VERSION ""

NS_ :

BS_:

BU_: RLPSU DPSU APSU PSB SHVU_RR vHS_B2 FCS EMCU SLB RCM CGW_CCU vDummy_HS_B ATS RLHV PFSU SGU ALBCU DSAU SWRC SHVU_FR RCS RRPSU BLTN_CAM SCM DLBCU OHCL RWPC RRHV WPC HOD ASAU

BO_ 799 SBCM_DRV_01_200ms: 8 CGW_CCU
 SG_ SBCM_DRV_Crc1Val : 0|8@1+ (1,0) [0|0] ""  Vector__XXX
 SG_ DRV_CrashUnlockCmd : 10|1@1+ (1,0) [0|0] ""  BLTN_CAM
 SG_ C_ApprOpenStatus : 11|1@1+ (1,0) [0|0] ""  Vector__XXX
 SG_ SBCM_DRV_AlvCnt1Val : 12|4@1+ (1,0) [0|0] ""  Vector__XXX
 SG_ DoorLock_DrvKeyLkSwSta_SBCM : 16|2@1+ (1,0) [0|0] ""  Vector__XXX
 SG_ DoorLock_DrvKeyUnLkSwSta_SBCM : 18|2@1+ (1,0) [0|0] ""  Vector__XXX
 SG_ Warn_DrvDrSwSta_SBCM : 20|2@1+ (1,0) [0|0] ""  WPC,RWPC,DPSU,ATS,BLTN_CAM
 SG_ DoorLock_DrvDrUnLkSta_SBCM : 22|2@1+ (1,0) [0|0] ""  ATS
 SG_ DRV_SEAWarn_LH : 24|2@1+ (1,0) [0|0] ""  Vector__XXX
 SG_ DRV_SEAWarn_RH : 26|2@1+ (1,0) [0|0] ""  Vector__XXX
 SG_ DRV_SEWWarn_LH : 28|2@1+ (1,0) [0|0] ""  Vector__XXX
 SG_ DRV_SEWWarn_RH : 30|2@1+ (1,0) [0|0] ""  Vector__XXX
 SG_ DRV_MRActivationAlarm : 32|2@1+ (1,0) [0|0] ""  Vector__XXX
 SG_ DRV_ReleaseWarn : 34|2@1+ (1,0) [0|0] ""  Vector__XXX
 SG_ Latch_TypeOption_DRV : 36|2@1+ (1,0) [0|0] ""  Vector__XXX
 SG_ DRV_SWFailAlarm : 38|2@1+ (1,0) [0|0] ""  Vector__XXX
 SG_ USM_PwrDRApprOpnSetSta : 40|2@1+ (1,0) [0|0] ""  Vector__XXX
 SG_ USM_PwrDRApprOpnSetOpt : 42|2@1+ (1,0) [0|0] ""  Vector__XXX
 SG_ USM_PwrDRCloseByRKELockSta : 44|2@1+ (1,0) [0|0] ""  Vector__XXX
 SG_ USM_PwrDRCloseByRKELockOpt : 46|2@1+ (1,0) [0|0] ""  Vector__XXX
 SG_ USM_PwrDRCloseByBrakeSta : 48|2@1+ (1,0) [0|0] ""  Vector__XXX
 SG_ USM_PwrDRCloseByBrakeOpt : 50|2@1+ (1,0) [0|0] ""  Vector__XXX
 SG_ USM_PwrDRBuzzerSta : 52|2@1+ (1,0) [0|0] ""  Vector__XXX
 SG_ USM_PwrDRBuzzerOpt : 54|2@1+ (1,0) [0|0] ""  Vector__XXX
 SG_ PDS_TypeOption_DRV : 56|2@1+ (1,0) [0|0] ""  Vector__XXX
 SG_ C_DrvDoorApproachOpen : 58|2@1+ (1,0) [0|0] ""  Vector__XXX
 SG_ C_DrvDoorApproachClose : 60|2@1+ (1,0) [0|0] ""  Vector__XXX
 SG_ DoorLock_PDSLkSwSta_DRV : 62|2@1+ (1,0) [0|0] ""  Vector__XXX
 SG_ DRVDoorPushAlarm : 8|2@1+ (1,0) [0|0] ""  Vector__XXX

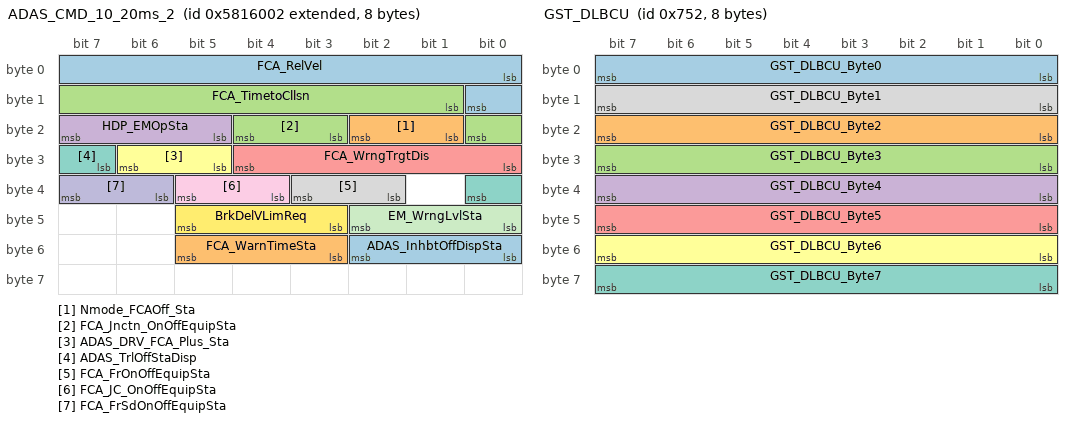
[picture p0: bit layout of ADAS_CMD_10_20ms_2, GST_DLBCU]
BO_ 2239848450 ADAS_CMD_10_20ms_2: 8 CGW_CCU
 SG_ FCA_RelVel : 0|9@1+ (0.1,-25.5) [0|0] "m/s"  Vector__XXX
 SG_ Nmode_FCAOff_Sta : 17|2@1+ (1,0) [0|0] ""  Vector__XXX
 SG_ FCA_Jnctn_OnOffEquipSta : 19|2@1+ (1,0) [0|0] ""  PSB
 SG_ HDP_EMOpSta : 21|3@1+ (1,0) [0|0] ""  Vector__XXX
 SG_ FCA_WrngTrgtDis : 24|5@1+ (1,0) [0|0] ""  APSU
 SG_ ADAS_DRV_FCA_Plus_Sta : 29|2@1+ (1,0) [0|0] ""  Vector__XXX
 SG_ ADAS_TrlOffStaDisp : 31|2@1+ (1,0) [0|0] ""  Vector__XXX
 SG_ FCA_FrOnOffEquipSta : 34|2@1+ (1,0) [0|0] ""  Vector__XXX
 SG_ FCA_JC_OnOffEquipSta : 36|2@1+ (1,0) [0|0] ""  Vector__XXX
 SG_ FCA_FrSdOnOffEquipSta : 38|2@1+ (1,0) [0|0] ""  Vector__XXX
 SG_ EM_WrngLvlSta : 40|3@1+ (1,0) [0|0] ""  Vector__XXX
 SG_ BrkDelVLimReq : 43|3@1+ (1,0) [0|0] ""  Vector__XXX
 SG_ ADAS_InhbtOffDispSta : 48|3@1+ (1,0) [0|0] ""  Vector__XXX
 SG_ FCA_WarnTimeSta : 51|3@1+ (1,0) [0|0] ""  Vector__XXX
 SG_ FCA_TimetoCllsn : 9|8@1+ (10,0) [0|0] "ms"  Vector__XXX

BO_ 1874 GST_DLBCU: 8 CGW_CCU
 SG_ GST_DLBCU_Byte0 : 0|8@1+ (1,0) [0|0] ""  DLBCU
 SG_ GST_DLBCU_Byte2 : 16|8@1+ (1,0) [0|0] ""  DLBCU
 SG_ GST_DLBCU_Byte3 : 24|8@1+ (1,0) [0|0] ""  DLBCU
 SG_ GST_DLBCU_Byte4 : 32|8@1+ (1,0) [0|0] ""  DLBCU
 SG_ GST_DLBCU_Byte5 : 40|8@1+ (1,0) [0|0] ""  DLBCU
 SG_ GST_DLBCU_Byte6 : 48|8@1+ (1,0) [0|0] ""  DLBCU
 SG_ GST_DLBCU_Byte7 : 56|8@1+ (1,0) [0|0] ""  DLBCU
 SG_ GST_DLBCU_Byte1 : 8|8@1+ (1,0) [0|0] ""  DLBCU

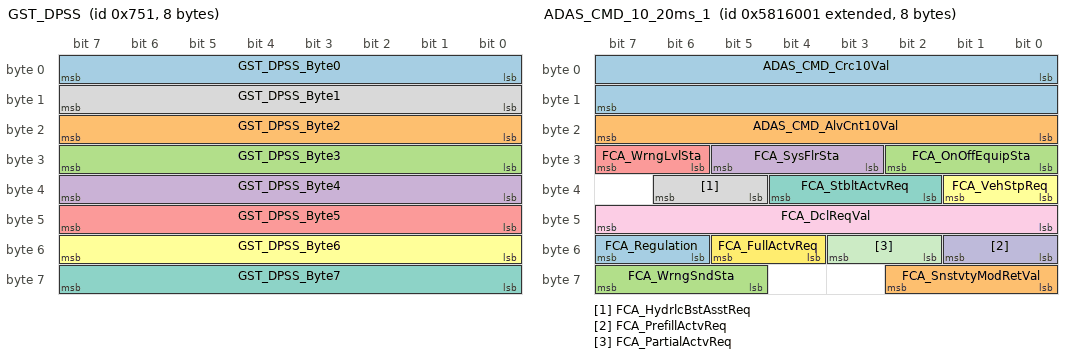
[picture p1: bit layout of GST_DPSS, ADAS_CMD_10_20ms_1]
BO_ 1873 GST_DPSS: 8 CGW_CCU
 SG_ GST_DPSS_Byte0 : 0|8@1+ (1,0) [0|0] ""  DPSU
 SG_ GST_DPSS_Byte2 : 16|8@1+ (1,0) [0|0] ""  DPSU
 SG_ GST_DPSS_Byte3 : 24|8@1+ (1,0) [0|0] ""  DPSU
 SG_ GST_DPSS_Byte4 : 32|8@1+ (1,0) [0|0] ""  DPSU
 SG_ GST_DPSS_Byte5 : 40|8@1+ (1,0) [0|0] ""  DPSU
 SG_ GST_DPSS_Byte6 : 48|8@1+ (1,0) [0|0] ""  DPSU
 SG_ GST_DPSS_Byte7 : 56|8@1+ (1,0) [0|0] ""  DPSU
 SG_ GST_DPSS_Byte1 : 8|8@1+ (1,0) [0|0] ""  DPSU

BO_ 2239848449 ADAS_CMD_10_20ms_1: 8 CGW_CCU
 SG_ ADAS_CMD_Crc10Val : 0|16@1+ (1,0) [0|0] ""  PSB
 SG_ ADAS_CMD_AlvCnt10Val : 16|8@1+ (1,0) [0|0] ""  PSB
 SG_ FCA_OnOffEquipSta : 24|3@1+ (1,0) [0|0] ""  PSB
 SG_ FCA_SysFlrSta : 27|3@1+ (1,0) [0|0] ""  PSB
 SG_ FCA_WrngLvlSta : 30|2@1+ (1,0) [0|0] ""  SWRC,APSU,RRPSU,RLPSU
 SG_ FCA_VehStpReq : 32|2@1+ (1,0) [0|0] ""  SWRC
 SG_ FCA_StbltActvReq : 34|3@1+ (1,0) [0|0] ""  PSB
 SG_ FCA_HydrlcBstAsstReq : 37|2@1+ (1,0) [0|0] ""  Vector__XXX
 SG_ FCA_DclReqVal : 40|8@1+ (0.01,0) [0|0] "g"  Vector__XXX
 SG_ FCA_PrefillActvReq : 48|2@1+ (1,0) [0|0] ""  Vector__XXX
 SG_ FCA_PartialActvReq : 50|2@1+ (1,0) [0|0] ""  Vector__XXX
 SG_ FCA_FullActvReq : 52|2@1+ (1,0) [0|0] ""  APSU,RRPSU,RLPSU
 SG_ FCA_Regulation : 54|2@1+ (1,0) [0|0] ""  Vector__XXX
 SG_ FCA_SnstvtyModRetVal : 56|3@1+ (1,0) [0|0] ""  Vector__XXX
 SG_ FCA_WrngSndSta : 61|3@1+ (1,0) [0|0] ""  Vector__XXX

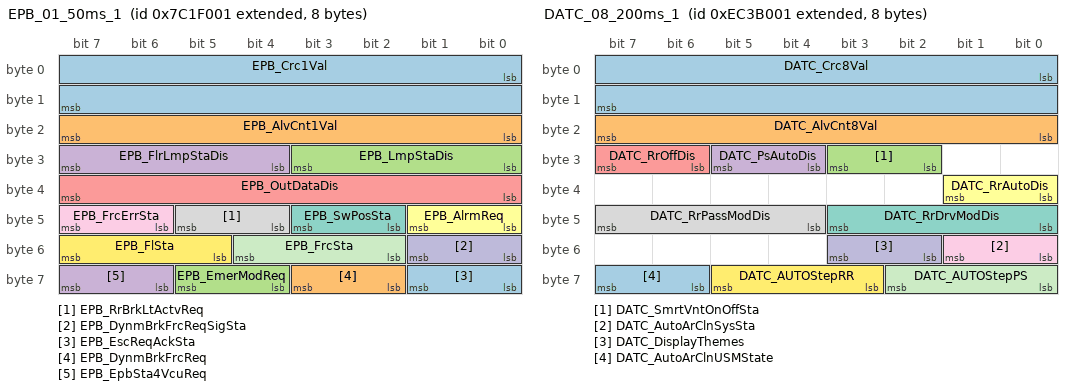
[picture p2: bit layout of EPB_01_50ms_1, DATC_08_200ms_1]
BO_ 2277634049 EPB_01_50ms_1: 8 CGW_CCU
 SG_ EPB_Crc1Val : 0|16@1+ (1,0) [0|0] ""  Vector__XXX
 SG_ EPB_AlvCnt1Val : 16|8@1+ (1,0) [0|0] ""  Vector__XXX
 SG_ EPB_LmpStaDis : 24|4@1+ (1,0) [0|0] ""  APSU,RLHV,RRHV,DPSU,PFSU,RRPSU,RLPSU
 SG_ EPB_FlrLmpStaDis : 28|4@1+ (1,0) [0|0] ""  Vector__XXX
 SG_ EPB_OutDataDis : 32|8@1+ (1,0) [0|0] ""  Vector__XXX
 SG_ EPB_AlrmReq : 40|2@1+ (1,0) [0|0] ""  Vector__XXX
 SG_ EPB_SwPosSta : 42|2@1+ (1,0) [0|0] ""  Vector__XXX
 SG_ EPB_RrBrkLtActvReq : 44|2@1+ (1,0) [0|0] ""  Vector__XXX
 SG_ EPB_FrcErrSta : 46|2@1+ (1,0) [0|0] ""  Vector__XXX
 SG_ EPB_DynmBrkFrcReqSigSta : 48|2@1+ (1,0) [0|0] ""  Vector__XXX
 SG_ EPB_FrcSta : 50|3@1+ (1,0) [0|0] ""  Vector__XXX
 SG_ EPB_FlSta : 53|3@1+ (1,0) [0|0] ""  Vector__XXX
 SG_ EPB_EscReqAckSta : 56|2@1+ (1,0) [0|0] ""  Vector__XXX
 SG_ EPB_DynmBrkFrcReq : 58|2@1+ (1,0) [0|0] ""  Vector__XXX
 SG_ EPB_EmerModReq : 60|2@1+ (1,0) [0|0] ""  Vector__XXX
 SG_ EPB_EpbSta4VcuReq : 62|2@1+ (1,0) [0|0] ""  Vector__XXX

BO_ 2277634050 EPB_01_50ms_2: 8 CGW_CCU
 SG_ EPB_ActlFrcVal : 0|12@1+ (1,-1000) [0|0] ""  Vector__XXX
 SG_ EPB_DynmBrkFrcDclReq : 16|8@1+ (0.01,0) [0|0] "g"  Vector__XXX

BO_ 2395189249 DATC_08_200ms_1: 8 CGW_CCU
 SG_ DATC_Crc8Val : 0|16@1+ (1,0) [0|0] ""  Vector__XXX
 SG_ DATC_AlvCnt8Val : 16|8@1+ (1,0) [0|0] ""  Vector__XXX
 SG_ DATC_SmrtVntOnOffSta : 26|2@1+ (1,0) [0|0] ""  Vector__XXX
 SG_ DATC_PsAutoDis : 28|2@1+ (1,0) [0|0] ""  ATS
 SG_ DATC_RrOffDis : 30|2@1+ (1,0) [0|0] ""  Vector__XXX
 SG_ DATC_RrAutoDis : 32|2@1+ (1,0) [0|0] ""  ATS
 SG_ DATC_RrDrvModDis : 40|4@1+ (1,0) [0|0] ""  ATS
 SG_ DATC_RrPassModDis : 44|4@1+ (1,0) [0|0] ""  ATS
 SG_ DATC_AutoArClnSysSta : 48|2@1+ (1,0) [0|0] ""  Vector__XXX
 SG_ DATC_DisplayThemes : 50|2@1+ (1,0) [0|0] ""  Vector__XXX
 SG_ DATC_AUTOStepPS : 56|3@1+ (1,0) [0|0] ""  ATS
 SG_ DATC_AUTOStepRR : 59|3@1+ (1,0) [0|0] ""  ATS
 SG_ DATC_AutoArClnUSMState : 62|2@1+ (1,0) [0|0] ""  Vector__XXX

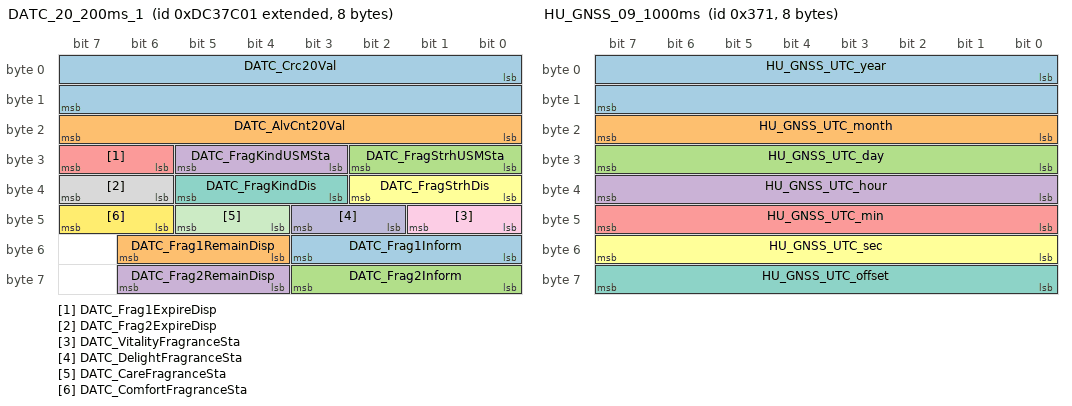
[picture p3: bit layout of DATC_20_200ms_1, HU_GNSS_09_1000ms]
BO_ 2378398721 DATC_20_200ms_1: 8 CGW_CCU
 SG_ DATC_Crc20Val : 0|16@1+ (1,0) [0|0] ""  Vector__XXX
 SG_ DATC_AlvCnt20Val : 16|8@1+ (1,0) [0|0] ""  Vector__XXX
 SG_ DATC_FragStrhUSMSta : 24|3@1+ (1,0) [0|0] ""  ATS
 SG_ DATC_FragKindUSMSta : 27|3@1+ (1,0) [0|0] ""  ATS
 SG_ DATC_Frag1ExpireDisp : 30|2@1+ (1,0) [0|0] ""  ATS
 SG_ DATC_FragStrhDis : 32|3@1+ (1,0) [0|0] ""  ATS
 SG_ DATC_FragKindDis : 35|3@1+ (1,0) [0|0] ""  ATS
 SG_ DATC_Frag2ExpireDisp : 38|2@1+ (1,0) [0|0] ""  ATS
 SG_ DATC_VitalityFragranceSta : 40|2@1+ (1,0) [0|0] ""  Vector__XXX
 SG_ DATC_DelightFragranceSta : 42|2@1+ (1,0) [0|0] ""  Vector__XXX
 SG_ DATC_CareFragranceSta : 44|2@1+ (1,0) [0|0] ""  Vector__XXX
 SG_ DATC_ComfortFragranceSta : 46|2@1+ (1,0) [0|0] ""  Vector__XXX
 SG_ DATC_Frag1Inform : 48|4@1+ (1,0) [0|0] ""  ATS
 SG_ DATC_Frag1RemainDisp : 52|3@1+ (1,0) [0|0] ""  ATS
 SG_ DATC_Frag2Inform : 56|4@1+ (1,0) [0|0] ""  ATS
 SG_ DATC_Frag2RemainDisp : 60|3@1+ (1,0) [0|0] ""  ATS

BO_ 881 HU_GNSS_09_1000ms: 8 CGW_CCU
 SG_ HU_GNSS_UTC_year : 0|16@1+ (1,0) [0|0] ""  BLTN_CAM
 SG_ HU_GNSS_UTC_month : 16|8@1+ (1,0) [0|0] ""  BLTN_CAM
 SG_ HU_GNSS_UTC_day : 24|8@1+ (1,0) [0|0] ""  BLTN_CAM
 SG_ HU_GNSS_UTC_hour : 32|8@1+ (1,0) [0|0] ""  BLTN_CAM
 SG_ HU_GNSS_UTC_min : 40|8@1+ (1,0) [0|0] ""  BLTN_CAM
 SG_ HU_GNSS_UTC_sec : 48|8@1+ (1,0) [0|0] ""  BLTN_CAM
 SG_ HU_GNSS_UTC_offset : 56|8@1+ (1,0) [0|0] "Sec"  BLTN_CAM

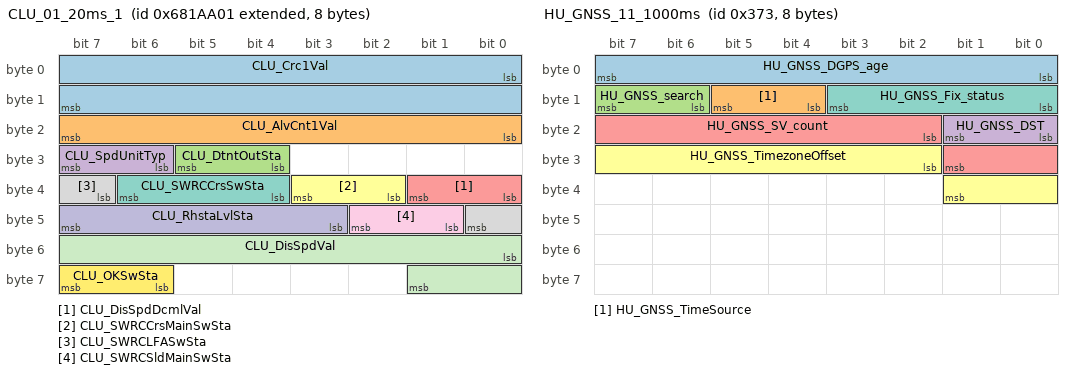
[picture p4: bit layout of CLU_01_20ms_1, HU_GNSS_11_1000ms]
BO_ 2256644609 CLU_01_20ms_1: 8 CGW_CCU
 SG_ CLU_Crc1Val : 0|16@1+ (1,0) [0|0] ""  SHVU_RR,DPSU,ATS
 SG_ CLU_AlvCnt1Val : 16|8@1+ (1,0) [0|0] ""  SHVU_RR,DPSU,ATS,EMCU
 SG_ CLU_DtntOutSta : 28|2@1+ (1,0) [0|0] ""  FCS,WPC,RWPC,SWRC,APSU,RLHV,RRHV,SHVU_FR,SHVU_RR,DPSU,RCS,RRPSU,RLPSU,ATS,DSAU,ASAU,OHCL
 SG_ CLU_SpdUnitTyp : 30|2@1+ (1,0) [0|0] ""  DPSU,BLTN_CAM,EMCU
 SG_ CLU_DisSpdDcmlVal : 32|2@1+ (0.125,0) [0|0] ""  Vector__XXX
 SG_ CLU_SWRCCrsMainSwSta : 34|2@1+ (1,0) [0|0] ""  Vector__XXX
 SG_ CLU_SWRCCrsSwSta : 36|3@1+ (1,0) [0|0] ""  Vector__XXX
 SG_ CLU_SWRCLFASwSta : 39|2@1+ (1,0) [0|0] ""  Vector__XXX
 SG_ CLU_SWRCSldMainSwSta : 41|2@1+ (1,0) [0|0] ""  Vector__XXX
 SG_ CLU_RhstaLvlSta : 43|5@1+ (1,0) [0|0] ""  FCS,WPC,RWPC,SWRC,APSU,RLHV,RRHV,SHVU_FR,SHVU_RR,DPSU,RCS,RRPSU,RLPSU,ATS,DSAU,ASAU,OHCL
 SG_ CLU_DisSpdVal : 48|10@1+ (0.5,0) [0|0] "km/h or MPH"  APSU,DPSU,BLTN_CAM,EMCU
 SG_ CLU_OKSwSta : 62|2@1+ (1,0) [0|0] ""  Vector__XXX

BO_ 883 HU_GNSS_11_1000ms: 8 CGW_CCU
 SG_ HU_GNSS_DGPS_age : 0|8@1+ (1,0) [0|0] "Sec"  Vector__XXX
 SG_ HU_GNSS_TimeSource : 12|2@1+ (1,0) [0|0] ""  Vector__XXX
 SG_ HU_GNSS_search : 14|2@1+ (1,0) [0|0] ""  Vector__XXX
 SG_ HU_GNSS_DST : 16|2@1+ (1,0) [0|0] ""  BLTN_CAM
 SG_ HU_GNSS_SV_count : 18|8@1+ (1,0) [0|0] ""  Vector__XXX
 SG_ HU_GNSS_TimezoneOffset : 26|8@1- (15,0) [0|0] "minute"  BLTN_CAM
 SG_ HU_GNSS_Fix_status : 8|4@1+ (1,0) [0|0] ""  Vector__XXX

BO_ 2470761217 CLU_07_00ms_1: 8 CGW_CCU
 SG_ CLU_Crc7Val : 0|16@1+ (1,0) [0|0] ""  Vector__XXX
 SG_ CLU_AlvCnt7Val : 16|8@1+ (1,0) [0|0] ""  Vector__XXX
 SG_ USM_AutoDrLkSetReq : 24|3@1+ (1,0) [0|0] ""  Vector__XXX
 SG_ USM_AutoDrUnlckSetReq : 27|3@1+ (1,0) [0|0] ""  Vector__XXX
 SG_ USM_HLmpEscrtSetReq : 30|2@1+ (1,0) [0|0] ""  Vector__XXX
 SG_ USM_SmrtTrnkSetReq : 32|3@1+ (1,0) [0|0] ""  Vector__XXX
 SG_ USM_MdLmpSetReq : 35|3@1+ (1,0) [0|0] ""  Vector__XXX
 SG_ USM_HrnAnswerBckSetReq : 38|2@1+ (1,0) [0|0] ""  Vector__XXX
 SG_ USM_OneTouchTrplTrnSetReq : 40|3@1+ (1,0) [0|0] ""  Vector__XXX
 SG_ USM_PsmSetReq : 43|3@1+ (1,0) [0|0] ""  DPSU
 SG_ USM_PtgmSetReq : 46|2@1+ (1,0) [0|0] ""  Vector__XXX
 SG_ USM_ScmSetReq : 48|2@1+ (1,0) [0|0] ""  Vector__XXX
 SG_ USM_OSTempUnitSetReq : 50|2@1+ (1,0) [0|0] ""  Vector__XXX
 SG_ USM_TfrChgSetReq : 52|2@1+ (1,0) [0|0] ""  Vector__XXX
 SG_ USM_WALModSetreq : 54|2@1+ (1,0) [0|0] ""  Vector__XXX
 SG_ USM_EscOffSetReq : 56|3@1+ (1,0) [0|0] ""  Vector__XXX
 SG_ USM_PsmHgtSetReq : 59|3@1+ (1,0) [0|0] ""  Vector__XXX

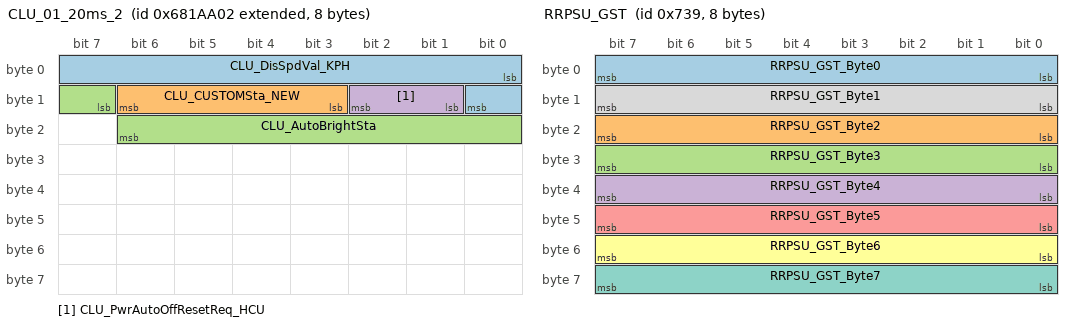
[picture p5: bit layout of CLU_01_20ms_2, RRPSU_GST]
BO_ 2256644610 CLU_01_20ms_2: 8 CGW_CCU
 SG_ CLU_DisSpdVal_KPH : 0|9@1+ (1,0) [0|0] "km/h"  WPC,RWPC,APSU,RLHV,RRHV,SHVU_FR,SHVU_RR,DPSU,DLBCU,PFSU,RRPSU,RLPSU,ATS,DSAU,ASAU,RCM,ALBCU
 SG_ CLU_CUSTOMSta_NEW : 11|4@1+ (1,0) [0|0] ""  Vector__XXX
 SG_ CLU_AutoBrightSta : 15|8@1+ (1,0) [0|0] ""  FCS,WPC,RWPC,SWRC,APSU,RLHV,RRHV,SHVU_FR,SHVU_RR,DPSU,RCS,ATS,DSAU,ASAU,OHCL,BLTN_CAM
 SG_ CLU_PwrAutoOffResetReq_HCU : 9|2@1+ (1,0) [0|0] ""  Vector__XXX

BO_ 1849 RRPSU_GST: 8 RRPSU
 SG_ RRPSU_GST_Byte0 : 0|8@1+ (1,0) [0|0] ""  CGW_CCU
 SG_ RRPSU_GST_Byte2 : 16|8@1+ (1,0) [0|0] ""  CGW_CCU
 SG_ RRPSU_GST_Byte3 : 24|8@1+ (1,0) [0|0] ""  CGW_CCU
 SG_ RRPSU_GST_Byte4 : 32|8@1+ (1,0) [0|0] ""  CGW_CCU
 SG_ RRPSU_GST_Byte5 : 40|8@1+ (1,0) [0|0] ""  CGW_CCU
 SG_ RRPSU_GST_Byte6 : 48|8@1+ (1,0) [0|0] ""  CGW_CCU
 SG_ RRPSU_GST_Byte7 : 56|8@1+ (1,0) [0|0] ""  CGW_CCU
 SG_ RRPSU_GST_Byte1 : 8|8@1+ (1,0) [0|0] ""  CGW_CCU

BO_ 884 HU_GNSS_12_1000ms: 8 CGW_CCU
 SG_ HU_MM_Latitude : 0|32@1- (1.0E-6,0) [0|0] "¢ª"  BLTN_CAM
 SG_ HU_MM_Longitude : 32|32@1- (1.0E-6,0) [0|0] "¢ª"  BLTN_CAM

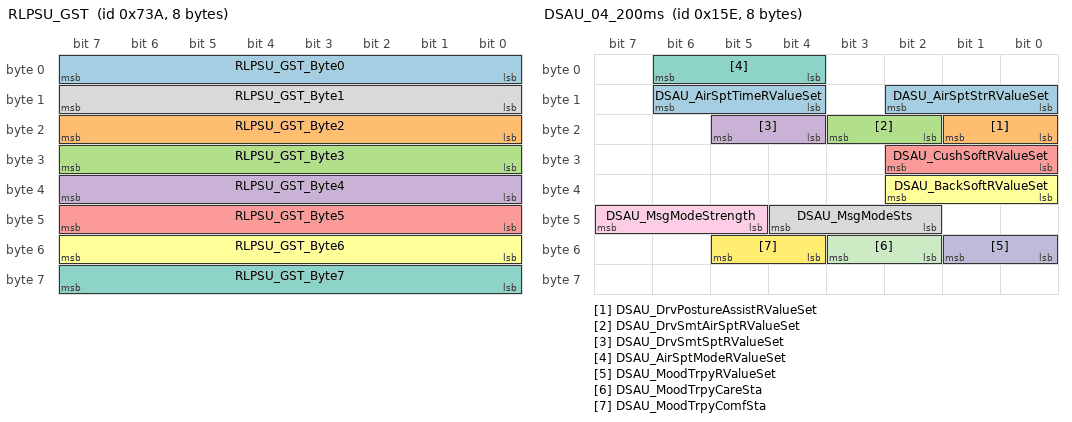
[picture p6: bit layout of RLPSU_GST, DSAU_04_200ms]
BO_ 1850 RLPSU_GST: 8 RLPSU
 SG_ RLPSU_GST_Byte0 : 0|8@1+ (1,0) [0|0] ""  CGW_CCU
 SG_ RLPSU_GST_Byte2 : 16|8@1+ (1,0) [0|0] ""  CGW_CCU
 SG_ RLPSU_GST_Byte3 : 24|8@1+ (1,0) [0|0] ""  CGW_CCU
 SG_ RLPSU_GST_Byte4 : 32|8@1+ (1,0) [0|0] ""  CGW_CCU
 SG_ RLPSU_GST_Byte5 : 40|8@1+ (1,0) [0|0] ""  CGW_CCU
 SG_ RLPSU_GST_Byte6 : 48|8@1+ (1,0) [0|0] ""  CGW_CCU
 SG_ RLPSU_GST_Byte7 : 56|8@1+ (1,0) [0|0] ""  CGW_CCU
 SG_ RLPSU_GST_Byte1 : 8|8@1+ (1,0) [0|0] ""  CGW_CCU

BO_ 2210462212 HCU_03_10ms_4: 8 CGW_CCU

BO_ 350 DSAU_04_200ms: 8 DSAU
 SG_ DSAU_AirSptTimeRValueSet : 12|3@1+ (1,0) [0|0] ""  CGW_CCU
 SG_ DSAU_DrvPostureAssistRValueSet : 16|2@1+ (1,0) [0|0] ""  Vector__XXX
 SG_ DSAU_DrvSmtAirSptRValueSet : 18|2@1+ (1,0) [0|0] ""  CGW_CCU
 SG_ DSAU_DrvSmtSptRValueSet : 20|2@1+ (1,0) [0|0] ""  Vector__XXX
 SG_ DSAU_CushSoftRValueSet : 24|3@1+ (1,0) [0|0] ""  CGW_CCU
 SG_ DSAU_BackSoftRValueSet : 32|3@1+ (1,0) [0|0] ""  CGW_CCU
 SG_ DSAU_AirSptModeRValueSet : 4|3@1+ (1,0) [0|0] ""  CGW_CCU
 SG_ DSAU_MsgModeSts : 42|3@1+ (1,0) [0|0] ""  CGW_CCU
 SG_ DSAU_MsgModeStrength : 45|3@1+ (1,0) [0|0] ""  CGW_CCU
 SG_ DSAU_MoodTrpyRValueSet : 48|2@1+ (1,0) [0|0] ""  CGW_CCU
 SG_ DSAU_MoodTrpyCareSta : 50|2@1+ (1,0) [0|0] ""  CGW_CCU
 SG_ DSAU_MoodTrpyComfSta : 52|2@1+ (1,0) [0|0] ""  CGW_CCU
 SG_ DASU_AirSptStrRValueSet : 8|3@1+ (1,0) [0|0] ""  CGW_CCU

BO_ 349 DSAU_03_200ms: 8 DSAU
 SG_ DSAU_CushInfDis : 0|2@1+ (1,0) [0|0] ""  CGW_CCU
 SG_ DSAU_CushDefDis : 2|2@1+ (1,0) [0|0] ""  CGW_CCU

BO_ 348 DSAU_02_200ms: 8 DSAU
 SG_ DSAU_BolsterInfDis : 0|2@1+ (1,0) [0|0] ""  CGW_CCU
 SG_ DSAU_BolsterDefDis : 2|2@1+ (1,0) [0|0] ""  CGW_CCU

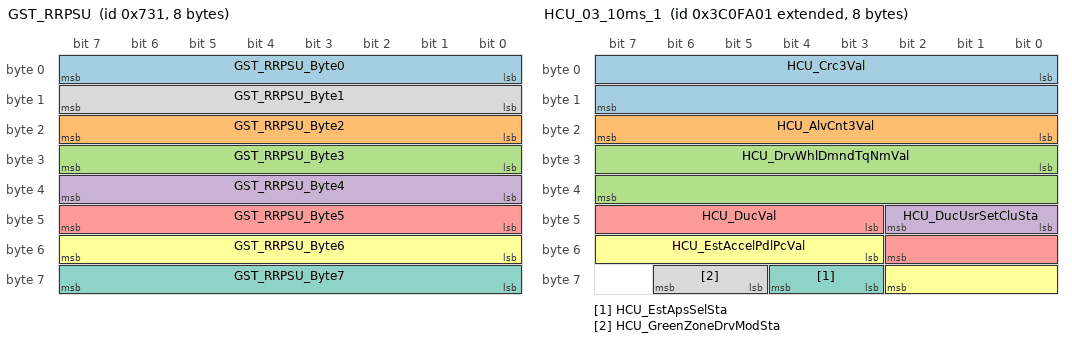
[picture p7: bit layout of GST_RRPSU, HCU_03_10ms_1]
BO_ 1841 GST_RRPSU: 8 CGW_CCU
 SG_ GST_RRPSU_Byte0 : 0|8@1+ (1,0) [0|0] ""  RRPSU
 SG_ GST_RRPSU_Byte2 : 16|8@1+ (1,0) [0|0] ""  RRPSU
 SG_ GST_RRPSU_Byte3 : 24|8@1+ (1,0) [0|0] ""  RRPSU
 SG_ GST_RRPSU_Byte4 : 32|8@1+ (1,0) [0|0] ""  RRPSU
 SG_ GST_RRPSU_Byte5 : 40|8@1+ (1,0) [0|0] ""  RRPSU
 SG_ GST_RRPSU_Byte6 : 48|8@1+ (1,0) [0|0] ""  RRPSU
 SG_ GST_RRPSU_Byte7 : 56|8@1+ (1,0) [0|0] ""  RRPSU
 SG_ GST_RRPSU_Byte1 : 8|8@1+ (1,0) [0|0] ""  RRPSU

BO_ 2210462209 HCU_03_10ms_1: 8 CGW_CCU
 SG_ HCU_Crc3Val : 0|16@1+ (1,0) [0|0] ""  Vector__XXX
 SG_ HCU_AlvCnt3Val : 16|8@1+ (1,0) [0|0] ""  Vector__XXX
 SG_ HCU_DrvWhlDmndTqNmVal : 24|16@1- (1,0) [0|0] "Nm"  Vector__XXX
 SG_ HCU_DucUsrSetCluSta : 40|3@1+ (1,0) [0|0] ""  Vector__XXX
 SG_ HCU_DucVal : 43|8@1+ (1,0) [0|0] "km"  Vector__XXX
 SG_ HCU_EstAccelPdlPcVal : 51|8@1+ (0.390625,0) [0|0] "%"  Vector__XXX
 SG_ HCU_EstApsSelSta : 59|2@1+ (1,0) [0|0] ""  Vector__XXX
 SG_ HCU_GreenZoneDrvModSta : 61|2@1+ (1,0) [0|0] ""  Vector__XXX

BO_ 346 DPSS_04_200ms: 8 DPSU
 SG_ DPSS_WalkInSwitchSts : 44|2@1+ (1,0) [0|0] ""  Vector__XXX

BO_ 2210462210 HCU_03_10ms_2: 8 CGW_CCU
 SG_ HCU_GreenZoneLmpDis : 0|2@1+ (1,0) [0|0] ""  Vector__XXX
 SG_ HCU_MILOnReq : 10|2@1+ (1,0) [0|0] ""  Vector__XXX
 SG_ HCU_PhevAutoModOnSta : 12|2@1+ (1,0) [0|0] "flag"  Vector__XXX
 SG_ HCU_SccDrvOvrdReq : 14|2@1+ (1,0) [0|0] ""  Vector__XXX
 SG_ HCU_SccEnblSta : 16|2@1+ (1,0) [0|0] ""  Vector__XXX
 SG_ HCU_SlwDnSta : 18|2@1+ (1,0) [0|0] ""  Vector__XXX
 SG_ HCU_HcuRdySta : 2|2@1+ (1,0) [0|0] ""  Vector__XXX
 SG_ HCU_SmrtEcoGdDis : 20|2@1+ (1,0) [0|0] ""  Vector__XXX
 SG_ HCU_SmrtEcoLvlDis : 22|7@1+ (1,0) [0|0] ""  Vector__XXX
 SG_ HCU_SmrtEcoRngDis : 29|7@1+ (1,0) [0|0] ""  Vector__XXX
 SG_ HCU_SpdLimDeviceActSta : 36|2@1+ (1,0) [0|0] ""  Vector__XXX
 SG_ HCU_SpdLimDeviceOperSta : 38|2@1+ (1,0) [0|0] ""  Vector__XXX
 SG_ HCU_HEVRdyDis : 4|2@1+ (1,0) [0|0] ""  Vector__XXX
 SG_ HCU_SpdLimDeviceVehSpdVal : 40|8@1+ (1,0) [0|0] "km/h"  Vector__XXX
 SG_ HCU_SrvModSta : 48|2@1+ (1,0) [0|0] ""  Vector__XXX
 SG_ HCU_StrtInhbt2Sta : 50|2@1+ (1,0) [0|0] ""  Vector__XXX
 SG_ HCU_StrtInhbtSta : 52|2@1+ (1,0) [0|0] ""  Vector__XXX
 SG_ HCU_SysShtOffReq : 54|2@1+ (1,0) [0|0] ""  Vector__XXX
 SG_ HCU_VehStrtEnblSta : 56|2@1+ (1,0) [0|0] ""  Vector__XXX
 SG_ HCU_BrkLmpOnReq : 58|2@1+ (1,0) [0|0] ""  Vector__XXX
 SG_ HCU_HevRdySta : 6|2@1+ (1,0) [0|0] ""  WPC,RWPC,SWRC,HOD,BLTN_CAM
 SG_ HCU_CcDrvAlrtDis : 60|2@1+ (1,0) [0|0] ""  Vector__XXX
 SG_ HCU_SldDrvAlrtDis : 62|2@1+ (1,0) [0|0] ""  Vector__XXX
 SG_ HCU_LimpOffSta : 8|2@1+ (1,0) [0|0] ""  Vector__XXX

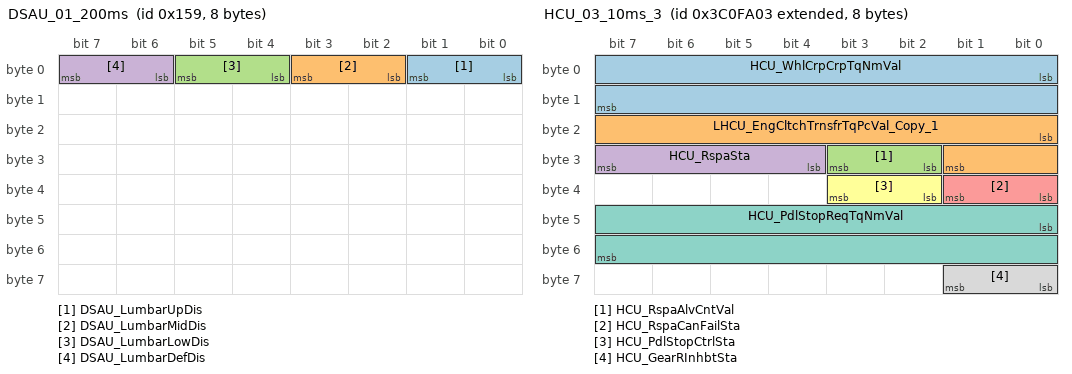
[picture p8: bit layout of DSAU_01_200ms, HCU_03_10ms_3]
BO_ 345 DSAU_01_200ms: 8 DSAU
 SG_ DSAU_LumbarUpDis : 0|2@1+ (1,0) [0|0] ""  CGW_CCU
 SG_ DSAU_LumbarMidDis : 2|2@1+ (1,0) [0|0] ""  CGW_CCU
 SG_ DSAU_LumbarLowDis : 4|2@1+ (1,0) [0|0] ""  CGW_CCU
 SG_ DSAU_LumbarDefDis : 6|2@1+ (1,0) [0|0] ""  CGW_CCU

BO_ 2210462211 HCU_03_10ms_3: 8 CGW_CCU
 SG_ HCU_WhlCrpCrpTqNmVal : 0|16@1- (1,0) [0|0] "Nm"  Vector__XXX
 SG_ LHCU_EngCltchTrnsfrTqPcVal_Copy_1 : 16|10@1- (0.1953125,0) [0|0] "%"  Vector__XXX
 SG_ HCU_RspaAlvCntVal : 26|2@1+ (1,0) [0|0] "Step"  Vector__XXX
 SG_ HCU_RspaSta : 28|4@1+ (1,0) [0|0] ""  Vector__XXX
 SG_ HCU_RspaCanFailSta : 32|2@1+ (1,0) [0|0] ""  Vector__XXX
 SG_ HCU_PdlStopCtrlSta : 34|2@1+ (1,0) [0|0] ""  Vector__XXX
 SG_ HCU_PdlStopReqTqNmVal : 40|16@1+ (1,0) [0|0] "Nm"  Vector__XXX
 SG_ HCU_GearRInhbtSta : 56|2@1+ (1,0) [0|0] ""  Vector__XXX

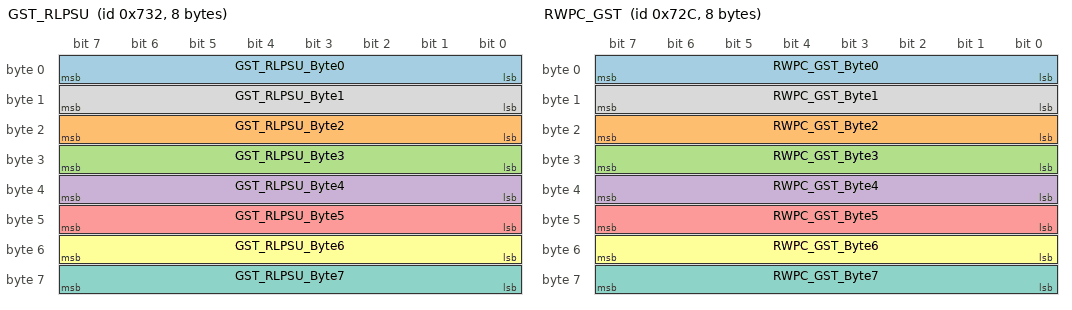
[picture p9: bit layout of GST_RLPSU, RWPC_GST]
BO_ 1842 GST_RLPSU: 8 CGW_CCU
 SG_ GST_RLPSU_Byte0 : 0|8@1+ (1,0) [0|0] ""  RLPSU
 SG_ GST_RLPSU_Byte2 : 16|8@1+ (1,0) [0|0] ""  RLPSU
 SG_ GST_RLPSU_Byte3 : 24|8@1+ (1,0) [0|0] ""  RLPSU
 SG_ GST_RLPSU_Byte4 : 32|8@1+ (1,0) [0|0] ""  RLPSU
 SG_ GST_RLPSU_Byte5 : 40|8@1+ (1,0) [0|0] ""  RLPSU
 SG_ GST_RLPSU_Byte6 : 48|8@1+ (1,0) [0|0] ""  RLPSU
 SG_ GST_RLPSU_Byte7 : 56|8@1+ (1,0) [0|0] ""  RLPSU
 SG_ GST_RLPSU_Byte1 : 8|8@1+ (1,0) [0|0] ""  RLPSU

BO_ 1836 RWPC_GST: 8 RWPC
 SG_ RWPC_GST_Byte0 : 0|8@1+ (1,0) [0|0] ""  CGW_CCU
 SG_ RWPC_GST_Byte2 : 16|8@1+ (1,0) [0|0] ""  CGW_CCU
 SG_ RWPC_GST_Byte3 : 24|8@1+ (1,0) [0|0] ""  CGW_CCU
 SG_ RWPC_GST_Byte4 : 32|8@1+ (1,0) [0|0] ""  CGW_CCU
 SG_ RWPC_GST_Byte5 : 40|8@1+ (1,0) [0|0] ""  CGW_CCU
 SG_ RWPC_GST_Byte6 : 48|8@1+ (1,0) [0|0] ""  CGW_CCU
 SG_ RWPC_GST_Byte7 : 56|8@1+ (1,0) [0|0] ""  CGW_CCU
 SG_ RWPC_GST_Byte1 : 8|8@1+ (1,0) [0|0] ""  CGW_CCU

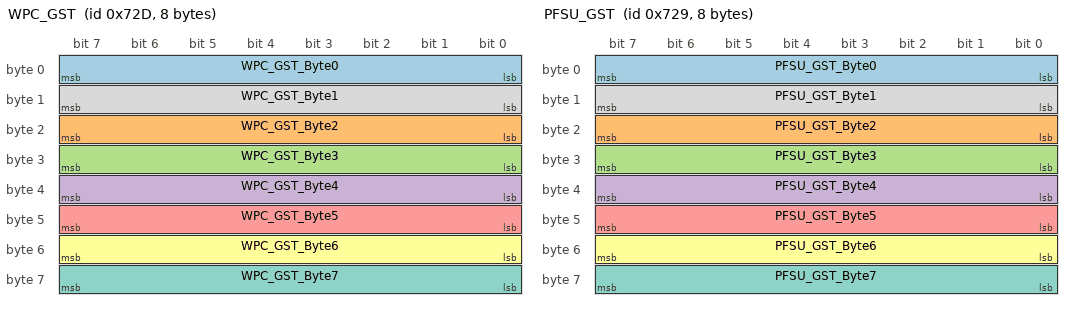
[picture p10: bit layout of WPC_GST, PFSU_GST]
BO_ 1837 WPC_GST: 8 WPC
 SG_ WPC_GST_Byte0 : 0|8@1+ (1,0) [0|0] ""  CGW_CCU
 SG_ WPC_GST_Byte2 : 16|8@1+ (1,0) [0|0] ""  CGW_CCU
 SG_ WPC_GST_Byte3 : 24|8@1+ (1,0) [0|0] ""  CGW_CCU
 SG_ WPC_GST_Byte4 : 32|8@1+ (1,0) [0|0] ""  CGW_CCU
 SG_ WPC_GST_Byte5 : 40|8@1+ (1,0) [0|0] ""  CGW_CCU
 SG_ WPC_GST_Byte6 : 48|8@1+ (1,0) [0|0] ""  CGW_CCU
 SG_ WPC_GST_Byte7 : 56|8@1+ (1,0) [0|0] ""  CGW_CCU
 SG_ WPC_GST_Byte1 : 8|8@1+ (1,0) [0|0] ""  CGW_CCU

BO_ 1833 PFSU_GST: 8 PFSU
 SG_ PFSU_GST_Byte0 : 0|8@1+ (1,0) [0|0] ""  CGW_CCU
 SG_ PFSU_GST_Byte2 : 16|8@1+ (1,0) [0|0] ""  CGW_CCU
 SG_ PFSU_GST_Byte3 : 24|8@1+ (1,0) [0|0] ""  CGW_CCU
 SG_ PFSU_GST_Byte4 : 32|8@1+ (1,0) [0|0] ""  CGW_CCU
 SG_ PFSU_GST_Byte5 : 40|8@1+ (1,0) [0|0] ""  CGW_CCU
 SG_ PFSU_GST_Byte6 : 48|8@1+ (1,0) [0|0] ""  CGW_CCU
 SG_ PFSU_GST_Byte7 : 56|8@1+ (1,0) [0|0] ""  CGW_CCU
 SG_ PFSU_GST_Byte1 : 8|8@1+ (1,0) [0|0] ""  CGW_CCU

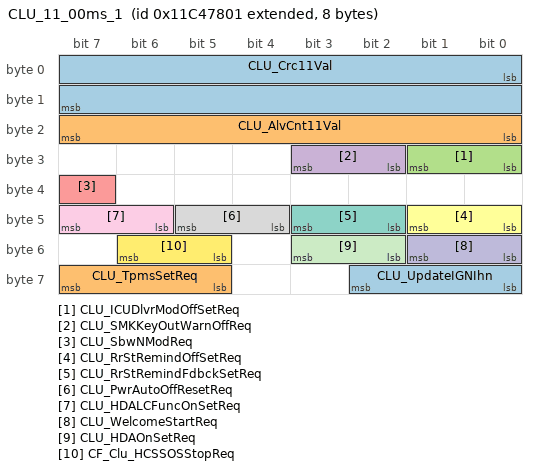
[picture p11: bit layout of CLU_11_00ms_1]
BO_ 2445572097 CLU_11_00ms_1: 8 CGW_CCU
 SG_ CLU_Crc11Val : 0|16@1+ (1,0) [0|0] ""  Vector__XXX
 SG_ CLU_AlvCnt11Val : 16|8@1+ (1,0) [0|0] ""  Vector__XXX
 SG_ CLU_ICUDlvrModOffSetReq : 24|2@1+ (1,0) [0|0] ""  Vector__XXX
 SG_ CLU_SMKKeyOutWarnOffReq : 26|2@1+ (1,0) [0|0] ""  Vector__XXX
 SG_ CLU_SbwNModReq : 39|1@1+ (1,0) [0|0] ""  Vector__XXX
 SG_ CLU_RrStRemindOffSetReq : 40|2@1+ (1,0) [0|0] ""  SWRC
 SG_ CLU_RrStRemindFdbckSetReq : 42|2@1+ (1,0) [0|0] ""  SWRC
 SG_ CLU_PwrAutoOffResetReq : 44|2@1+ (1,0) [0|0] ""  Vector__XXX
 SG_ CLU_HDALCFuncOnSetReq : 46|2@1+ (1,0) [0|0] ""  Vector__XXX
 SG_ CLU_WelcomeStartReq : 48|2@1+ (1,0) [0|0] ""  SWRC
 SG_ CLU_HDAOnSetReq : 50|2@1+ (1,0) [0|0] ""  Vector__XXX
 SG_ CF_Clu_HCSSOSStopReq : 53|2@1+ (1,0) [0|0] ""  Vector__XXX
 SG_ CLU_UpdateIGNIhn : 56|3@1+ (1,0) [0|0] ""  Vector__XXX
 SG_ CLU_TpmsSetReq : 61|3@1+ (1,0) [0|0] ""  Vector__XXX

CM_ BO_ 2239848449 "[P] Periodic";
CM_ SG_ 2239848449 ADAS_CMD_Crc10Val "ADAS_CMD_CyclicRedundancyCheck10Value ##2G##FCA - FCA11 - CR_FCA_ChkSum";
CM_ SG_ 2239848449 ADAS_CMD_AlvCnt10Val "ADAS_CMD_AliveCounter10Value ##2G##FCA - FCA11 - CR_FCA_Alive";
CM_ SG_ 2239848449 FCA_OnOffEquipSta "FCA_OnOffEquipmentStatus ##2G##FCA - FCA12 - FCA_USM";
CM_ SG_ 2239848449 FCA_SysFlrSta "FCA_SystemFailureStatus ##2G##FCA - FCA11 - FCA_Failinfo";
CM_ SG_ 2239848449 FCA_WrngLvlSta "FCA_WarningLevelStatus ##2G##FCA - FCA11 - CF_VSM_Warn";
CM_ SG_ 2239848449 FCA_VehStpReq "FCA_VehicleStopRequest ##2G##FCA - FCA11 - FCA_StopReq";
CM_ SG_ 2239848449 FCA_StbltActvReq "FCA_SeatBeltActivateRequest ##2G##FCA - FCA11 - CF_VSM_BeltCmd";
CM_ SG_ 2239848449 FCA_HydrlcBstAsstReq "FCA_HydraulicBoostAssistRequest ##2G##FCA - FCA11 - CF_VSM_HBACmd";
CM_ SG_ 2239848449 FCA_DclReqVal "FCA_DecelerationRequestValue ##2G##FCA - FCA11 - CR_VSM_DecCmd";
CM_ SG_ 2239848449 FCA_PrefillActvReq "FCA_PrefillActivateRequest ##2G##FCA - FCA11 - CF_VSM_Prefill";
CM_ SG_ 2239848449 FCA_PartialActvReq "FCA_PartialActivateRequest";
CM_ SG_ 2239848449 FCA_FullActvReq "FCA_FullActivateRequest";
CM_ SG_ 2239848449 FCA_Regulation "FCA_Regulation";
CM_ SG_ 2239848449 FCA_SnstvtyModRetVal "FCA_SensitivityModeReturnValue ##2G##FCA - FCA12 - FCA_DrvSetState";
CM_ SG_ 2239848449 FCA_WrngSndSta "FCA warning sound status";
CM_ BO_ 2239848450 "[P] Periodic";
CM_ SG_ 2239848450 FCA_RelVel "FCA_RelativeVelocity ##2G##FCA - FCA11_FS - FCA_RelativeVelocity";
CM_ SG_ 2239848450 Nmode_FCAOff_Sta "Nmode_FCAOff_Status ##2G##FCA - FCA12 - Nmode_FCAOff_Status";
CM_ SG_ 2239848450 FCA_Jnctn_OnOffEquipSta "FCA_Junction_OnOffEquipStatus";
CM_ SG_ 2239848450 HDP_EMOpSta "HDP EM Operating State";
CM_ SG_ 2239848450 FCA_WrngTrgtDis "FCA_WarningTargetDisplay";
CM_ SG_ 2239848450 ADAS_DRV_FCA_Plus_Sta "Àü¹æÄ«¸Þ¶ó, Àü¹æ·¹ÀÌ´õ ¹× ÀüÃø¹æ ·¹ÀÌ´õ/ÈÄÃø¹æ ·¹ÀÌÅÍ Ç»Àü Æ®·¢À» ÅëÇØ FCA-Car Å¸°Ù ¹× ÀÚÂ÷ ÁÂÃø/¿ìÃø ¿µ¿ª È¸ÇÇ ºÒ°¡´É ¿©ºÎ¸¦ ÆÇ´ÜÇÏ¿© FCA-Car/Ped/Cyc+ Flag¸¦ Ãâ·Â";
CM_ SG_ 2239848450 ADAS_TrlOffStaDisp "ADAS_Trailer Off State Display";
CM_ SG_ 2239848450 FCA_FrOnOffEquipSta "FCA Front On Off Equipment State";
CM_ SG_ 2239848450 FCA_JC_OnOffEquipSta "FCA_JC On Off Equipment State";
CM_ SG_ 2239848450 FCA_FrSdOnOffEquipSta "FCA Front Side On Off Equipment State";
CM_ SG_ 2239848450 EM_WrngLvlSta "EM_WarningLevelStatus";
CM_ SG_ 2239848450 BrkDelVLimReq "Brake Delta V Limit Request";
CM_ SG_ 2239848450 ADAS_InhbtOffDispSta "ADAS Inhibit Off Display State";
CM_ SG_ 2239848450 FCA_WarnTimeSta "FCA Warning Timing State";
CM_ SG_ 2239848450 FCA_TimetoCllsn "FCA_TimetoCollision ##2G##FCA - FCA11_FS - FCA_TimetoCollision";
CM_ BO_ 2256644609 "[P] Periodic";
CM_ SG_ 2256644609 CLU_Crc1Val "CLU_CyclicRedundancyCheck1Value";
CM_ SG_ 2256644609 CLU_AlvCnt1Val "CLU_AliveCounter1Value";
CM_ SG_ 2256644609 CLU_DtntOutSta "CLU_DetentOutStatus";
CM_ SG_ 2256644609 CLU_SpdUnitTyp "CLU_SpeedUnitType";
CM_ SG_ 2256644609 CLU_DisSpdDcmlVal "CLU_DisplaySpeedDecimalValue";
CM_ SG_ 2256644609 CLU_SWRCCrsMainSwSta "CLU_SWRCCrsMainSwSta";
CM_ SG_ 2256644609 CLU_SWRCCrsSwSta "CLU_SWRCCrsSwSta";
CM_ SG_ 2256644609 CLU_SWRCLFASwSta "SWRC_LFASwitchStatus";
CM_ SG_ 2256644609 CLU_SWRCSldMainSwSta "SWRC_SpeedLimiterMainSwitchStatus";
CM_ SG_ 2256644609 CLU_RhstaLvlSta "CLU_RheostatLevelStatus";
CM_ SG_ 2256644609 CLU_DisSpdVal "CLU_DisplaySpeedValue";
CM_ SG_ 2256644609 CLU_OKSwSta "OK Switch On/Off State";
CM_ BO_ 2256644610 "[P] Periodic";
CM_ SG_ 2256644610 CLU_DisSpdVal_KPH "CLU_DisplaySpeedValue_KPH";
CM_ SG_ 2256644610 CLU_AutoBrightSta "CLU_AutoBrightStatus";
CM_ SG_ 2256644610 CLU_PwrAutoOffResetReq_HCU "reset power auto off time";
CM_ BO_ 2470761217 "[EC] On Event and On Change";
CM_ SG_ 2470761217 CLU_Crc7Val "CLU_CyclicRedundancyCheck7Value";
CM_ SG_ 2470761217 CLU_AlvCnt7Val "CLU_AliveCounter7Value";
CM_ SG_ 2470761217 USM_AutoDrLkSetReq "USM_AutoDoorLockSetRequest";
CM_ SG_ 2470761217 USM_AutoDrUnlckSetReq "USM_AutoDoorUnlockSetRequest";
CM_ SG_ 2470761217 USM_HLmpEscrtSetReq "USM_HeadLampEscortSetRequest";
CM_ SG_ 2470761217 USM_SmrtTrnkSetReq "USM_SmartTrunkSetRequest";
CM_ SG_ 2470761217 USM_MdLmpSetReq "USM_MoodLampSetRequest";
CM_ SG_ 2470761217 USM_HrnAnswerBckSetReq "USM_HornAnswerBackSetRequest";
CM_ SG_ 2470761217 USM_OneTouchTrplTrnSetReq "USM_OneTouchTripleTurnSetRequest";
CM_ SG_ 2470761217 USM_PsmSetReq "USM_PsmSetRequest";
CM_ SG_ 2470761217 USM_PtgmSetReq "USM_PtgmSetRequest";
CM_ SG_ 2470761217 USM_ScmSetReq "USM_ScmSetRequest";
CM_ SG_ 2470761217 USM_OSTempUnitSetReq "USM_OutsideTemperatureUnitSetValue";
CM_ SG_ 2470761217 USM_TfrChgSetReq "USM_TrafficChangeSetRequest";
CM_ SG_ 2470761217 USM_WALModSetreq "USM_WalkAwayLockModeSetRequest(2nd General : CF_Clu_WALNValueset))";
CM_ SG_ 2470761217 USM_EscOffSetReq "USM_EscOffSetRequest (2nd general : CLU14/CF_Clu_EscOffNValueSet";
CM_ SG_ 2470761217 USM_PsmHgtSetReq "USM_PsmHeightSetRequest(2nd general : CLU20/CF_Clu_PSMHeightNValueSet )";
CM_ BO_ 2445572097 "[EC] On Event and On Change";
CM_ SG_ 2445572097 CLU_Crc11Val "CLU_CyclicRedundancyCheck11Value";
CM_ SG_ 2445572097 CLU_AlvCnt11Val "CLU_AliveCounter11Value";
CM_ SG_ 2445572097 CLU_ICUDlvrModOffSetReq "CLU_ICUDeliveryModeOffSetRequest";
CM_ SG_ 2445572097 CLU_SMKKeyOutWarnOffReq "CLU_SMKKeyOutWarningOffRequest";
CM_ SG_ 2445572097 CLU_SbwNModReq "CLU_SbwNModeRequest(2nd general: CLU22/CF_Clu_SbwNModeReq)";
CM_ SG_ 2445572097 CLU_RrStRemindOffSetReq "CLU_RrseatReminderOffSetRequest(2nd general:CLU20/CF_Clu_RrSeatRemindOff)";
CM_ SG_ 2445572097 CLU_RrStRemindFdbckSetReq "CLU_RrseatReminderFeedbackRequest (2nd general : CLU20/CF_Clu_RrSeatRemindFeedback)";
CM_ SG_ 2445572097 CLU_PwrAutoOffResetReq "reset power auto off time";
CM_ SG_ 2445572097 CLU_HDALCFuncOnSetReq "CLU_HDALCFuncOnSetReq";
CM_ SG_ 2445572097 CLU_WelcomeStartReq "Cluster welcome start signal";
CM_ SG_ 2445572097 CLU_HDAOnSetReq "This signal is used for a request to set on LFA/HDA";
CM_ SG_ 2445572097 CF_Clu_HCSSOSStopReq "Request to stop the SOS call";
CM_ SG_ 2445572097 CLU_TpmsSetReq "This signal is for setting the reference pressure of the iTPMS system";
CM_ BO_ 2395189249 "[PE] Periodic and On Event";
CM_ SG_ 2395189249 DATC_Crc8Val "DATC_CyclicRedundancyCheck8Value";
CM_ SG_ 2395189249 DATC_AlvCnt8Val "DATC_AliveCounter8Value";
CM_ SG_ 2395189249 DATC_SmrtVntOnOffSta "DATC_SmartVentilationOnOffStatus";
CM_ SG_ 2395189249 DATC_PsAutoDis "DATC_PassengerAutoDisplay";
CM_ SG_ 2395189249 DATC_RrOffDis "DATC_RearOffDisplay";
CM_ SG_ 2395189249 DATC_RrAutoDis "DATC_RearAutoDisplay";
CM_ SG_ 2395189249 DATC_RrDrvModDis "DATC_RearDriverModeDisplay";
CM_ SG_ 2395189249 DATC_RrPassModDis "DATC_RearPassengerModeDisplay";
CM_ SG_ 2395189249 DATC_AutoArClnSysSta "Auto Air Cleaning System State (China region only)";
CM_ SG_ 2395189249 DATC_DisplayThemes "DATC_DisplayThemesInformation";
CM_ SG_ 2395189249 DATC_AUTOStepPS "This signal indicates Passenger AUTO step status in case Multi Auto Blower type.";
CM_ SG_ 2395189249 DATC_AUTOStepRR "This signal indicates Rear AUTO step status in case Multi Auto Blower type.";
CM_ SG_ 2395189249 DATC_AutoArClnUSMState "Auto Air Cleaning USM State (China only apply)";
CM_ BO_ 2378398721 "[PE] Periodic and On Event";
CM_ SG_ 2378398721 DATC_Crc20Val "DATC_CyclicRedundancyCheck20Value";
CM_ SG_ 2378398721 DATC_AlvCnt20Val "DATC_AliveCounter20Value";
CM_ SG_ 2378398721 DATC_FragStrhUSMSta "Fragrance Strength State";
CM_ SG_ 2378398721 DATC_FragKindUSMSta "Fragrance Kind State";
CM_ SG_ 2378398721 DATC_Frag1ExpireDisp "DATC_Fragrance1ExpireDisplay";
CM_ SG_ 2378398721 DATC_FragStrhDis "Fragrance Strength Display";
CM_ SG_ 2378398721 DATC_FragKindDis "Fragrance Kind Display";
CM_ SG_ 2378398721 DATC_Frag2ExpireDisp "DATC_Fragrance2ExpireDisplay";
CM_ SG_ 2378398721 DATC_VitalityFragranceSta "DATC_VitalityFragranceState";
CM_ SG_ 2378398721 DATC_DelightFragranceSta "DATC_DelightFragranceState";
CM_ SG_ 2378398721 DATC_CareFragranceSta "DATC_CareFragranceState";
CM_ SG_ 2378398721 DATC_ComfortFragranceSta "DATC_ComfortFragranceState";
CM_ SG_ 2378398721 DATC_Frag1Inform "DATC_Fragrance1Information";
CM_ SG_ 2378398721 DATC_Frag1RemainDisp "DATC_Fragrance1RemainDisplay";
CM_ SG_ 2378398721 DATC_Frag2Inform "DATC_Fragrance2Information";
CM_ SG_ 2378398721 DATC_Frag2RemainDisp "DATC_Fragrance2RemainDisplay";
CM_ BO_ 346 "[PE] Periodic and On Event";
CM_ SG_ 346 DPSS_WalkInSwitchSts "DPSS_WalkInSwitchStatus";
CM_ BO_ 345 "[PE] Periodic and On Event";
CM_ SG_ 345 DSAU_LumbarUpDis "DSAU_LumbarUppperDisplay";
CM_ SG_ 345 DSAU_LumbarMidDis "DSAU_LumbarMidDisplay";
CM_ SG_ 345 DSAU_LumbarLowDis "DSAU_LumbarLowerDisplay";
CM_ SG_ 345 DSAU_LumbarDefDis "DSAU_LumbarDeflationDisplay";
CM_ BO_ 348 "[PE] Periodic and On Event";
CM_ SG_ 348 DSAU_BolsterInfDis "DSAU_BolsterInflationDisplay";
CM_ SG_ 348 DSAU_BolsterDefDis "DSAU_BolsterDeflationDisplay";
CM_ BO_ 349 "[PE] Periodic and On Event";
CM_ SG_ 349 DSAU_CushInfDis "DSAU_CushionInflationDisplay";
CM_ SG_ 349 DSAU_CushDefDis "DSAU_CushionDeflationDisplay";
CM_ BO_ 350 "[PE] Periodic and On Event";
CM_ SG_ 350 DSAU_AirSptTimeRValueSet "Air Support Time(Massage Time) USM R Value";
CM_ SG_ 350 DSAU_DrvPostureAssistRValueSet "Drive Seat Posture Assist Function USM R Value";
CM_ SG_ 350 DSAU_DrvSmtAirSptRValueSet "Seat Smart Air Support Function USM R Value";
CM_ SG_ 350 DSAU_DrvSmtSptRValueSet "Seat Smart Support Function USM R Value";
CM_ SG_ 350 DSAU_CushSoftRValueSet "Cushion Soft R Value";
CM_ SG_ 350 DSAU_BackSoftRValueSet "Back Soft USM R Value";
CM_ SG_ 350 DSAU_AirSptModeRValueSet "Air Support Mode(Massage Mode) USM R Value";
CM_ SG_ 350 DSAU_MsgModeSts "Air Support Mode Function Operating Display";
CM_ SG_ 350 DSAU_MsgModeStrength "Air Support intensity regulation(Massage Strenth)";
CM_ SG_ 350 DSAU_MoodTrpyRValueSet "Drive Seat Mood Therapy R Value";
CM_ SG_ 350 DSAU_MoodTrpyCareSta "Drive Seat Mood Therapy Care Mode R Value";
CM_ SG_ 350 DSAU_MoodTrpyComfSta "Drive Seat Mood Therapy Comfort Mode R Value";
CM_ SG_ 350 DASU_AirSptStrRValueSet "Air Support Strenth(Massage Strenth) USM R Value";
CM_ BO_ 2277634049 "[P] Periodic";
CM_ SG_ 2277634049 EPB_Crc1Val "EPB_CyclicRedundancyCheck1Value";
CM_ SG_ 2277634049 EPB_AlvCnt1Val "EPB_AliveCounter1Value";
CM_ SG_ 2277634049 EPB_LmpStaDis "EPB_LampStateDisplay ##2G##EPB - EPB11 - EPB_I_LAMP";
CM_ SG_ 2277634049 EPB_FlrLmpStaDis "EPB_FailureLampStateDisplay ##2G##EPB - EPB11 - EPB_F_LAMP";
CM_ SG_ 2277634049 EPB_OutDataDis "EPB_OutputDataDisplay ##2G##EPB - EPB11 - EPB_CLU";
CM_ SG_ 2277634049 EPB_AlrmReq "EPB_AlarmRequest ##2G##EPB - EPB11 - EPB_ALARM";
CM_ SG_ 2277634049 EPB_SwPosSta "EPB_SwitchPositionStatus ##2G##EPB - EPB11 - EPB_SWITCH";
CM_ SG_ 2277634049 EPB_RrBrkLtActvReq "EPB_RearBrakeLightActivationRequest ##2G##EPB - EPB11 - EPB_RBL";
CM_ SG_ 2277634049 EPB_FrcErrSta "EPB_ForceErrorStatus ##2G##EPB - EPB11 - EPB_FRC_ERR";
CM_ SG_ 2277634049 EPB_DynmBrkFrcReqSigSta "EPB_DynamicBrakingForceRequestSignalStatus ##2G##EPB - EPB11 - EPB_DBF_STAT";
CM_ SG_ 2277634049 EPB_FrcSta "EPB_ForceStatus ##2G##EPB - EPB11 - EPB_STATUS";
CM_ SG_ 2277634049 EPB_FlSta "EPB_FailStatus ##2G##EPB - EPB11 - EPB_FAIL";
CM_ SG_ 2277634049 EPB_EscReqAckSta "EPB_EscRequestAcknowledgeStatus ##2G##EPB - EPB11 - ESP_ACK";
CM_ SG_ 2277634049 EPB_DynmBrkFrcReq "EPB_DynamicBrakingForceRequest ##2G##EPB - EPB11 - EPB_DBF_REQ";
CM_ SG_ 2277634049 EPB_EmerModReq "EPB Emergency Mode Request";
CM_ SG_ 2277634049 EPB_EpbSta4VcuReq "EPB Status when VCU request of parking command or not parking command";
CM_ BO_ 2277634050 "[P] Periodic";
CM_ SG_ 2277634050 EPB_ActlFrcVal "EPB_ActualForceValue ##2G##EPB - EPB11 - EPB_FORCE";
CM_ SG_ 2277634050 EPB_DynmBrkFrcDclReq "EPB_DynamicBrakingForceDecelerationRequest ##2G##EPB - EPB11 - EPB_DBF_DECEL";
CM_ BO_ 1874 "[TP] Transport Protocol";
CM_ BO_ 1873 "[TP] Transport Protocol";
CM_ BO_ 1842 "[TP] Transport Protocol";
CM_ BO_ 1841 "[TP] Transport Protocol";
CM_ BO_ 2210462209 "[P] Periodic";
CM_ SG_ 2210462209 HCU_Crc3Val "HCU_CyclicRedundancyCheck3Value";
CM_ SG_ 2210462209 HCU_AlvCnt3Val "HCU_AliveCounter3Value";
CM_ SG_ 2210462209 HCU_DrvWhlDmndTqNmVal "HCU_DriverWheelDemandTorqueNmValue ##2G##HCU - HCU2 - CR_Hcu_WhlDemTq_Nm";
CM_ SG_ 2210462209 HCU_DucUsrSetCluSta "HCU_DucUserSettingClusterStatus ##2G##HCU - HCU4 - CF_Hcu_DUCPopUp";
CM_ SG_ 2210462209 HCU_DucVal "HCU_DucValue ##2G##HCU - HCU4 - CR_Hcu_DUC";
CM_ SG_ 2210462209 HCU_EstAccelPdlPcVal "HCU_EstimatedAcceleratorPedalPcValue ##2G##HCU - HCU4 - CR_Hcu_EstAccPed_PC";
CM_ SG_ 2210462209 HCU_EstApsSelSta "HCU_EstimatedApsSelectStatus ##2G##HCU - HCU4 - CF_HCU_EstApsSel";
CM_ SG_ 2210462209 HCU_GreenZoneDrvModSta "0x0:Default (USM ¹Ì Ç¥Ãâ (¸Þ´º»èÁ¦))
0x1:Off (USM Ç¥Ãâ Off »óÅÂ Ç¥½Ã) ##2G##HCU - HCU4 - CF_Hcu_GreenZoneDrv_Status";
CM_ BO_ 2210462210 "[P] Periodic";
CM_ SG_ 2210462210 HCU_GreenZoneLmpDis "Indicate Green Zone Area ##2G##HCU - HCU4 - CF_Hcu_GreenZoneLamp";
CM_ SG_ 2210462210 HCU_MILOnReq "HCU_MalfunctionIndicatorLampOnRequest ##2G##HCU - HCU1 - CF_Hcu_MILReq";
CM_ SG_ 2210462210 HCU_PhevAutoModOnSta "HCU_PhevAutoModeOnStatus ##2G##HCU - HCU4 - CF_Hcu_AutoCdCs";
CM_ SG_ 2210462210 HCU_SccDrvOvrdReq "HCU_SccDriverOverrideRequest ##2G##HCU - HCU2 - CF_Hcu_Ovrride";
CM_ SG_ 2210462210 HCU_SccEnblSta "HCU_SmartCruiseControlEnableStatus ##2G##HCU - HCU2 - CF_Hcu_SccEna";
CM_ SG_ 2210462210 HCU_SlwDnSta "HCU_SlowDownStatus ##2G##HCU - HCU1 - CF_Hcu_SlwDwnStat";
CM_ SG_ 2210462210 HCU_HcuRdySta "HCU_HybridControlUnitReadyStatus ##2G##HCU - HCU1 - CF_Hcu_Rdy";
CM_ SG_ 2210462210 HCU_SmrtEcoGdDis "HCU_SmartEcoGuideDisplay ##2G##HCU - HCU4 - CF_Hcu_SmartEcoDisp";
CM_ SG_ 2210462210 HCU_SmrtEcoLvlDis "HCU_SmartEcoLevelDisplay ##2G##HCU - HCU4 - CR_Hcu_SmartEcoLvl";
CM_ SG_ 2210462210 HCU_SmrtEcoRngDis "HCU_SmartEcoRangeDisplay ##2G##HCU - HCU4 - CR_Hcu_SmartEcoRng";
CM_ SG_ 2210462210 HCU_SpdLimDeviceActSta "HCU_SpeedLimiterDeviceActivationStatus ##2G##HCU - HCU4 - CF_Vcu_SldAct";
CM_ SG_ 2210462210 HCU_SpdLimDeviceOperSta "HCU_SpeedLimiterDeviceOperationStatus ##2G##HCU - HCU4 - CF_Hcu_SldOpr";
CM_ SG_ 2210462210 HCU_HEVRdyDis "HCU_HybridVehicleReadyDisplay ##2G##HCU - HCU1 - CF_Hcu_HevRdyClu";
CM_ SG_ 2210462210 HCU_SpdLimDeviceVehSpdVal "HCU_SpeedLimiterDeviceVehicleSpeedValue ##2G##HCU - HCU4 - CR_Vcu_SldVs";
CM_ SG_ 2210462210 HCU_SrvModSta "HCU_ServiceModeStatus ##2G##HCU - HCU2 - CF_Hcu_ServiceMod";
CM_ SG_ 2210462210 HCU_StrtInhbt2Sta "HCU_StartInhibit2Status ##2G##HCU - HCU3 - CF_Hcu_StartInh";
CM_ SG_ 2210462210 HCU_StrtInhbtSta "HCU_StartInhibitStatus ##2G##HCU - HCU1 - CF_Hcu_StInhStat";
CM_ SG_ 2210462210 HCU_SysShtOffReq "HCU_SystemShutOffRequest ##2G##HCU - HCU1 - CF_Hcu_SysShutOffReq";
CM_ SG_ 2210462210 HCU_VehStrtEnblSta "HCU_VehicleStartEnableStatus ##2G##HCU - HCU1 - CF_Hcu_Veh_ST";
CM_ SG_ 2210462210 HCU_BrkLmpOnReq "HCU_BrakeLampOnRequest###2G####HCU - HCU5 - CF_Hcu_BrkLpReq";
CM_ SG_ 2210462210 HCU_HevRdySta "HCU_HybridVehicleReadyStatus ##2G##HCU - HCU1 - CF_Hcu_HevRdy";
CM_ SG_ 2210462210 HCU_CcDrvAlrtDis "Driver display information of CC can not be engaged";
CM_ SG_ 2210462210 HCU_SldDrvAlrtDis "SLD must be disengaged by system or cannot be engaged";
CM_ SG_ 2210462210 HCU_LimpOffSta "HCU_LimpOffStatus ##2G##HCU - HCU22 - CF_Hcu_LimpOff";
CM_ BO_ 2210462211 "[P] Periodic";
CM_ SG_ 2210462211 HCU_WhlCrpCrpTqNmVal "HCU_WheelCreepTorqueNmValue ##2G##HCU - HCU2 - CR_Hcu_CrpTq_Nm";
CM_ SG_ 2210462211 LHCU_EngCltchTrnsfrTqPcVal_Copy_1 "##2G##HCU - HCU7 - CR_Hcu_EngCltTrnfTq_Pc";
CM_ SG_ 2210462211 HCU_RspaAlvCntVal "RSPA HCU Alive Counter ##2G##HCU - HCU4 - CF_Hcu_RspaAliveCnt";
CM_ SG_ 2210462211 HCU_RspaSta "HCU RSPA Cooperative control staus ##2G##HCU - HCU4 - CF_Hcu_RspaStat";
CM_ SG_ 2210462211 HCU_RspaCanFailSta "HCU RSPA CAN Fail Status ##2G##HCU - HCU4 - CR_Hcu_RspaCanFailFlag";
CM_ BO_ 2210462212 "[P] Periodic";
CM_ BO_ 881 "[P] Periodic";
CM_ SG_ 881 HU_GNSS_UTC_year "UTC year";
CM_ SG_ 881 HU_GNSS_UTC_hour "UTC_HOUR";
CM_ BO_ 883 "[P] Periodic";
CM_ SG_ 883 HU_GNSS_TimeSource "Time Source¶õ ÀÏÁ¾ÀÇ ModuleÀÌ Ãâ·ÂÇÒ ¼ö ÀÖ´Â ½Ã°£Á¤º¸ÀÇ À¯È¿¼º·¹º§À» Å¸³ª³»¸ç, User´Â RTC  or GPS(<1ms)  ÀÏ¶§¸¸ ½Ã°£ Á¤º¸ »ç¿ë °¡´É";
CM_ SG_ 883 HU_GNSS_DST "DST setting";
CM_ SG_ 883 HU_GNSS_TimezoneOffset "Timezone Offset";
CM_ SG_ 883 HU_GNSS_Fix_status "GNSS fix status";
CM_ BO_ 884 "[P] Periodic";
CM_ SG_ 884 HU_MM_Latitude "Map matching Latitude";
CM_ SG_ 884 HU_MM_Longitude "Mapmatching Longitude";
CM_ BO_ 1833 "[TP] Transport Protocol";
CM_ BO_ 1850 "[TP] Transport Protocol";
CM_ BO_ 1849 "[TP] Transport Protocol";
CM_ BO_ 1836 "[TP] Transport Protocol";
CM_ BO_ 799 "[PE] Periodic and On Event";
CM_ SG_ 799 SBCM_DRV_Crc1Val "SBCM_DRV_CyclicRedundancyCheck1Value";
CM_ SG_ 799 C_ApprOpenStatus "Stop fob searching signal";
CM_ SG_ 799 SBCM_DRV_AlvCnt1Val "SBCM_DRV_AliveCounter1Value";
CM_ SG_ 799 DoorLock_DrvKeyLkSwSta_SBCM "DoorLock_DriverKeyLockSwitchStatus ##2G## -  - C_DrvKeyLockSw";
CM_ SG_ 799 DoorLock_DrvKeyUnLkSwSta_SBCM "DoorLock_DriverKeyUnLockSwitchStatus ##2G## -  - C_DrvKeyUnlockSw";
CM_ SG_ 799 Warn_DrvDrSwSta_SBCM "DoorLock_DriverDoorSwitchStatus ##2G## -  - C_DrvDrSw,CF_Gway_DrvDrSw,Warn_DrvDrSwSta";
CM_ SG_ 799 DoorLock_DrvDrUnLkSta_SBCM "DoorLock_DriverDoorUnLockStatus ##2G## -  - C_DrvUnlockState,CF_Gway_DrvUnlockState";
CM_ SG_ 799 C_DrvDoorApproachOpen "Approach open";
CM_ BO_ 1837 "[TP] Transport Protocol";
BA_DEF_ BO_ "DiagState" ENUM "No","Yes" ;
BA_DEF_ BO_ "DiagResponse" ENUM "No","Yes" ;
BA_DEF_ BO_ "DiagRequest" ENUM "No","Yes" ;
BA_DEF_ BO_ "TpMessage" ENUM "No","Yes" ;
BA_DEF_ BO_ "UsrMsgIDSforwardDeviation" INT 0 100 ;
BA_DEF_ BO_ "UsrMsgIDSbackwardDeviation" INT 50 1000 ;
BA_DEF_ BO_ "GenMsgCycleTime" INT 0 2000 ;
BA_DEF_ BO_ "GenMsgStartDelayTime" INT 0 2000 ;
BA_DEF_ BO_ "GenMsgSendType" ENUM "Cyclic","NoMsgSendType" ;
BA_DEF_ BO_ "GenMsgCycleTimeFast" INT 0 500 ;
BA_DEF_ BO_ "GenMsgDelayTime" INT 0 20 ;
BA_DEF_ BO_ "GenMsgILSupport" ENUM "No","Yes" ;
BA_DEF_ BO_ "GenMsgNrOfRepetition" INT 0 3 ;
BA_DEF_ BO_ "NmMessage" ENUM "No","Yes" ;
BA_DEF_ BO_ "NWM-Botschaft" ENUM "No","Yes" ;
BA_DEF_ BO_ "TpTxIndex" INT 0 255 ;
BA_DEF_ BO_ "VFrameFormat" ENUM "StandardCAN","ExtendedCAN","reserved","reserved","reserved","reserved","reserved","reserved","reserved","reserved","reserved","reserved","reserved","reserved","StandardCAN_FD","ExtendedCAN_FD" ;
BA_DEF_ SG_ "UserSigValidity" ENUM "B+","ACC","IG","IG1","IG2","IG3","IG1 or IG2","IG1 or IG3","Undef" ;
BA_DEF_ SG_ "TimeoutValue" STRING ;
BA_DEF_ SG_ "UsrSigPurpose" ENUM "Undef","FN","DIAG","DIAG(Req)","DIAG(Res)","DIAG(Phy)","DEV","CCP(Req)","CCP(Res)","NM","TP" ;
BA_DEF_ SG_ "GenSigStartValue" INT 0 1215752192 ;
BA_DEF_ SG_ "NetworkRequest" ENUM "Yes","No" ;
BA_DEF_ SG_ "NetworkRequestHoldingTime" INT 0 65535 ;
BA_DEF_ SG_ "Description" STRING ;
BA_DEF_ SG_ "Version" STRING ;
BA_DEF_ SG_ "GenSigEnvVarType" ENUM "Int","Float","Undef" ;
BA_DEF_ SG_ "GenSigSendType" ENUM "Cyclic","OnWrite","OnWriteWithRepetition","OnChange","OnChangeWithRepetition","IfActive","IfActiveWithRepetition","NoSigSendType","OnChangeAndIfActive","OnChangeAndIfActiveWithRepetition" ;
BA_DEF_ SG_ "GwSigLatencyTime" INT 0 65536 ;
BA_DEF_ SG_ "GwSigMissingSourceType" ENUM "Undef","OldValue","DefaultValue","InitialValue" ;
BA_DEF_ SG_ "NWM-WakeupAllowed" ENUM "<n.a.>" ;
BA_DEF_ SG_ "RoutingFactor" INT 1 1215752192 ;
BA_DEF_REL_ BU_SG_REL_ "GenSigTimeoutTime" INT 0 7000 ;
BA_DEF_DEF_ "DiagState" "No" ;
BA_DEF_DEF_ "DiagResponse" "No" ;
BA_DEF_DEF_ "DiagRequest" "No" ;
BA_DEF_DEF_ "TpMessage" "No" ;
BA_DEF_DEF_ "UsrMsgIDSforwardDeviation" 10 ;
BA_DEF_DEF_ "UsrMsgIDSbackwardDeviation" 100 ;
BA_DEF_DEF_ "GenMsgCycleTime" 200 ;
BA_DEF_DEF_ "GenMsgStartDelayTime" 0 ;
BA_DEF_DEF_ "GenMsgSendType" "NoMsgSendType" ;
BA_DEF_DEF_ "GenMsgCycleTimeFast" 40 ;
BA_DEF_DEF_ "GenMsgDelayTime" 20 ;
BA_DEF_DEF_ "GenMsgILSupport" "Yes" ;
BA_DEF_DEF_ "GenMsgNrOfRepetition" 3 ;
BA_DEF_DEF_ "NmMessage" "No" ;
BA_DEF_DEF_ "NWM-Botschaft" "No" ;
BA_DEF_DEF_ "TpTxIndex" 0 ;
BA_DEF_DEF_ "VFrameFormat" "StandardCAN" ;
BA_DEF_DEF_ "UserSigValidity" "IG" ;
BA_DEF_DEF_ "TimeoutValue" "" ;
BA_DEF_DEF_ "UsrSigPurpose" "FN" ;
BA_DEF_DEF_ "GenSigStartValue" 0 ;
BA_DEF_DEF_ "NetworkRequest" "No" ;
BA_DEF_DEF_ "NetworkRequestHoldingTime" 0 ;
BA_DEF_DEF_ "Description" "" ;
BA_DEF_DEF_ "Version" "" ;
BA_DEF_DEF_ "GenSigEnvVarType" "Undef" ;
BA_DEF_DEF_ "GenSigSendType" "NoSigSendType" ;
BA_DEF_DEF_ "GwSigLatencyTime" 40 ;
BA_DEF_DEF_ "GwSigMissingSourceType" "Undef" ;
BA_DEF_DEF_ "NWM-WakeupAllowed" "<n.a.>" ;
BA_DEF_DEF_ "RoutingFactor" 1 ;
BA_DEF_DEF_REL_ "GenSigTimeoutTime" 500 ;
BA_ "GenMsgSendType" BO_ 2239848449 0;
BA_ "GenMsgCycleTime" BO_ 2239848449 100;
BA_ "GenMsgCycleTimeFast" BO_ 2239848449 0;
BA_ "GenMsgNrOfRepetition" BO_ 2239848449 0;
BA_ "VFrameFormat" BO_ 2239848449 1;
BA_ "Description" SG_ 2239848449 ADAS_CMD_Crc10Val "The data area for CRC calculation is based on the data length (DLC) of the message DB.

The CRC shall be calculated over the entire data block (excluding the CRC bytes) including the user data, alive counter and Data ID

 

- CRC Polynomial (0x1021) , Initial Value : 0xFFFF, XOR value : 0x0000, Data ID : Message ID + 0xF800 

- The initial value is for CRC calculation and the message should be sent with the calculated result value. 

- The mathematical expression to 16 bit CRC polynomial is given here. G(x) = x16 + x12 + x5 + 1";
BA_ "GenSigStartValue" SG_ 2239848449 ADAS_CMD_Crc10Val 65535;
BA_ "UserSigValidity" SG_ 2239848449 ADAS_CMD_Crc10Val 3;
BA_REL_ "GenSigTimeoutTime" BU_SG_REL_ PSB SG_ 2239848449 ADAS_CMD_Crc10Val 1500;
BA_ "RoutingFactor" SG_ 2239848449 ADAS_CMD_Crc10Val 5;
BA_ "Version" SG_ 2239848449 ADAS_CMD_Crc10Val "18.11.08";
BA_ "Description" SG_ 2239848449 ADAS_CMD_AlvCnt10Val "For the first transmission request for a data element the counter shall be initialized with 0 and shall be incremented by 1 for every subsequent send request. 

When the counter reaches the maximum value(0xFF), then it shall restart with 0 for the next send request";
BA_ "UserSigValidity" SG_ 2239848449 ADAS_CMD_AlvCnt10Val 3;
BA_REL_ "GenSigTimeoutTime" BU_SG_REL_ PSB SG_ 2239848449 ADAS_CMD_AlvCnt10Val 1500;
BA_ "RoutingFactor" SG_ 2239848449 ADAS_CMD_AlvCnt10Val 5;
BA_ "Version" SG_ 2239848449 ADAS_CMD_AlvCnt10Val "18.11.08";
BA_ "Description" SG_ 2239848449 FCA_OnOffEquipSta "This signal describes the FCA Function.

- ½Ã½ºÅÛ ÀåÂø ¿©ºÎ ¹× ½Ã½ºÅÛ on/off Á¤º¸";
BA_ "UserSigValidity" SG_ 2239848449 FCA_OnOffEquipSta 3;
BA_REL_ "GenSigTimeoutTime" BU_SG_REL_ PSB SG_ 2239848449 FCA_OnOffEquipSta 1500;
BA_ "RoutingFactor" SG_ 2239848449 FCA_OnOffEquipSta 5;
BA_ "Version" SG_ 2239848449 FCA_OnOffEquipSta "17.12.00";
BA_ "Description" SG_ 2239848449 FCA_SysFlrSta "This signal describes the failure information of FCA Function.

- ½Ã½ºÅÛ Á¤»ó ¶Ç´Â Ä«¸Þ¶ó/·¹ÀÌ´õ/½Ã½ºÅÛ °íÀå»óÅÂ Á¤º¸

0x1: Temporary unavailable by Front View Camera (blockage, high temperature, etc) for Sensor Fusion FCA 

0x2: Temporary unavailable by Front Radar (blockage, high temperature, etc) for either Radar only FCA or Sensor Fusion FCA when logic is in Front Radar

0x3: System failure (Failure by Front View Camera failure, Front Radar failure or relative cooperative control units, etc)

0x4: Temporary unavailable by Front View Camera (blockage, high temperature, etc) for Front View Camera only FCA

0x5: Temporary unavailable of steering function by Front View Camera (blockage, high temperature, etc) for sensor fusion when logic is in ADAS_DRV

0x6: Temporary unavailable by Front Radar (blockage, high temperature, etc) for Sensor Fusion FCA when logic is in Front View Camera";
BA_ "UserSigValidity" SG_ 2239848449 FCA_SysFlrSta 3;
BA_REL_ "GenSigTimeoutTime" BU_SG_REL_ PSB SG_ 2239848449 FCA_SysFlrSta 1500;
BA_ "RoutingFactor" SG_ 2239848449 FCA_SysFlrSta 5;
BA_ "Version" SG_ 2239848449 FCA_SysFlrSta "19.08.04";
BA_ "Description" SG_ 2239848449 FCA_WrngLvlSta "Request CLU to activate the corresponding warning device(s) according to the FCA warning level. (Braking / Steering act)

- FCA ±â´ÉÀÇ Á¦µ¿ ¹× Á¶Çâ Á¦¾î ÀÛµ¿ »óÅÂ Ç¥½Ã¿ë Á¤º¸½ÅÈ£";
BA_ "UserSigValidity" SG_ 2239848449 FCA_WrngLvlSta 3;
BA_REL_ "GenSigTimeoutTime" BU_SG_REL_ SWRC SG_ 2239848449 FCA_WrngLvlSta 1500;
BA_REL_ "GenSigTimeoutTime" BU_SG_REL_ APSU SG_ 2239848449 FCA_WrngLvlSta 1500;
BA_REL_ "GenSigTimeoutTime" BU_SG_REL_ RRPSU SG_ 2239848449 FCA_WrngLvlSta 1500;
BA_REL_ "GenSigTimeoutTime" BU_SG_REL_ RLPSU SG_ 2239848449 FCA_WrngLvlSta 1500;
BA_ "RoutingFactor" SG_ 2239848449 FCA_WrngLvlSta 5;
BA_ "Version" SG_ 2239848449 FCA_WrngLvlSta "19.06.02";
BA_ "Description" SG_ 2239848449 FCA_VehStpReq "A control request flag for vehicle stop. FCA expects vehicle to be controlled to a complete stop and hold its state by ESC.



- FCA Á¦µ¿»óÈ² Á¾·áÈÄ Á¤Â÷ »óÅÂ À¯Áö¸¦ À§ÇÑ ½ÅÈ£";
BA_ "UserSigValidity" SG_ 2239848449 FCA_VehStpReq 3;
BA_REL_ "GenSigTimeoutTime" BU_SG_REL_ SWRC SG_ 2239848449 FCA_VehStpReq 1500;
BA_ "RoutingFactor" SG_ 2239848449 FCA_VehStpReq 5;
BA_ "Version" SG_ 2239848449 FCA_VehStpReq "17.12.00";
BA_ "Description" SG_ 2239848449 FCA_StbltActvReq "Depending on the driving situation, FCA tells PSB to release(no alert), retract or pull the seat belt for occupant protection or warning.

- FCA Á¦µ¿»óÈ²½Ã ½ÃÆ®º§Æ® ÀÛµ¿À» À§ÇÑ Á¤º¸ ½ÅÈ£";
BA_ "UserSigValidity" SG_ 2239848449 FCA_StbltActvReq 3;
BA_REL_ "GenSigTimeoutTime" BU_SG_REL_ PSB SG_ 2239848449 FCA_StbltActvReq 1500;
BA_ "RoutingFactor" SG_ 2239848449 FCA_StbltActvReq 5;
BA_ "Version" SG_ 2239848449 FCA_StbltActvReq "17.12.00";
BA_ "Description" SG_ 2239848449 FCA_HydrlcBstAsstReq "Depending on the driving situation, FCA tells ESC to use lowered HBA (Hydraulic Boost Assist) threshold to sensitize the HBA entrance. 

The boost assist function is more easily activated than under normal driving condition.

- FCA Á¦µ¿»óÈ²½Ã HBA ÀÛµ¿À» À§ÇÑ Á¤º¸ ½ÅÈ£";
BA_ "UserSigValidity" SG_ 2239848449 FCA_HydrlcBstAsstReq 3;
BA_ "RoutingFactor" SG_ 2239848449 FCA_HydrlcBstAsstReq 5;
BA_ "Version" SG_ 2239848449 FCA_HydrlcBstAsstReq "17.12.00";
BA_ "Description" SG_ 2239848449 FCA_DclReqVal "Depending on the driving situation, FCA gives ESC the deceleration command. ESC maintains the deceleration.

- FCA Á¦µ¿À» À§ÇÑ ¿ä±¸ °¨¼Óµµ °ª";
BA_ "UserSigValidity" SG_ 2239848449 FCA_DclReqVal 3;
BA_ "RoutingFactor" SG_ 2239848449 FCA_DclReqVal 5;
BA_ "Version" SG_ 2239848449 FCA_DclReqVal "17.12.00";
BA_ "Description" SG_ 2239848449 FCA_PrefillActvReq "A control requeset flag for FCA first warning. (Audible Warning)

- FCA 1Â÷ Á¦µ¿»óÈ² ¿äÃ»½ÅÈ£";
BA_ "UserSigValidity" SG_ 2239848449 FCA_PrefillActvReq 3;
BA_ "RoutingFactor" SG_ 2239848449 FCA_PrefillActvReq 5;
BA_ "Version" SG_ 2239848449 FCA_PrefillActvReq "17.12.00";
BA_ "Description" SG_ 2239848449 FCA_PartialActvReq "A control requeset flag for FCA second warning. (Partial braking)

- FCA 2Â÷ Á¦µ¿»óÈ² ¿äÃ»½ÅÈ£";
BA_ "UserSigValidity" SG_ 2239848449 FCA_PartialActvReq 3;
BA_ "RoutingFactor" SG_ 2239848449 FCA_PartialActvReq 5;
BA_ "Version" SG_ 2239848449 FCA_PartialActvReq "17.11.00";
BA_ "Description" SG_ 2239848449 FCA_FullActvReq "A control requeset flag for FCA third warning. (Full braking)

- FCA 3Â÷ Á¦µ¿»óÈ² ¿äÃ»½ÅÈ£";
BA_ "UserSigValidity" SG_ 2239848449 FCA_FullActvReq 3;
BA_REL_ "GenSigTimeoutTime" BU_SG_REL_ APSU SG_ 2239848449 FCA_FullActvReq 1500;
BA_REL_ "GenSigTimeoutTime" BU_SG_REL_ RRPSU SG_ 2239848449 FCA_FullActvReq 1500;
BA_REL_ "GenSigTimeoutTime" BU_SG_REL_ RLPSU SG_ 2239848449 FCA_FullActvReq 1500;
BA_ "RoutingFactor" SG_ 2239848449 FCA_FullActvReq 5;
BA_ "Version" SG_ 2239848449 FCA_FullActvReq "17.11.00";
BA_ "Description" SG_ 2239848449 FCA_Regulation "This signal contains FCA regulation compliance information.";
BA_ "UserSigValidity" SG_ 2239848449 FCA_Regulation 3;
BA_ "RoutingFactor" SG_ 2239848449 FCA_Regulation 5;
BA_ "Version" SG_ 2239848449 FCA_Regulation "20.12.01";
BA_ "Description" SG_ 2239848449 FCA_SnstvtyModRetVal "This signal is FCA sensitive set mode switch(USM) info return value to cluster.

- FCA ¹Î°¨µµ ¼³Á¤ °ü·Ã USM ¼³Á¤ ½ºÀ§Ä¡ Á¤º¸ÀÇ ¸®ÅÏ °ª";
BA_ "UserSigValidity" SG_ 2239848449 FCA_SnstvtyModRetVal 3;
BA_ "RoutingFactor" SG_ 2239848449 FCA_SnstvtyModRetVal 5;
BA_ "Version" SG_ 2239848449 FCA_SnstvtyModRetVal "17.12.00";
BA_ "Description" SG_ 2239848449 FCA_WrngSndSta "FCA warning sound status";
BA_ "UserSigValidity" SG_ 2239848449 FCA_WrngSndSta 3;
BA_ "RoutingFactor" SG_ 2239848449 FCA_WrngSndSta 5;
BA_ "Version" SG_ 2239848449 FCA_WrngSndSta "18.12.04";
BA_ "GenMsgSendType" BO_ 2239848450 0;
BA_ "GenMsgCycleTime" BO_ 2239848450 100;
BA_ "GenMsgCycleTimeFast" BO_ 2239848450 0;
BA_ "GenMsgNrOfRepetition" BO_ 2239848450 0;
BA_ "VFrameFormat" BO_ 2239848450 1;
BA_ "Description" SG_ 2239848450 FCA_RelVel "This signal indicates the relative velocity between the host vehicle and a forward vehicle.







(PH) = ((HEX)-0FFH)*0.1 [m/s/digit]



       = (HEX)*0.1 [m/s/digit] - 25.5 [m/s]



CAN Message Physical range : Max. Relative velocity : 0x1FE(25.5m/s), Zero : 0x0FF(0m/s), Min. Relative velocity : 0x000(-25.5m/s)";
BA_ "UserSigValidity" SG_ 2239848450 FCA_RelVel 3;
BA_ "RoutingFactor" SG_ 2239848450 FCA_RelVel 5;
BA_ "Version" SG_ 2239848450 FCA_RelVel "20.02.00";
BA_ "Description" SG_ 2239848450 Nmode_FCAOff_Sta "This signal describes status of FCA off when Nmode on";
BA_ "UserSigValidity" SG_ 2239848450 Nmode_FCAOff_Sta 3;
BA_ "RoutingFactor" SG_ 2239848450 Nmode_FCAOff_Sta 5;
BA_ "Version" SG_ 2239848450 Nmode_FCAOff_Sta "17.12.00";
BA_ "Description" SG_ 2239848450 FCA_Jnctn_OnOffEquipSta "This signal describes the FCA-JC Function.

- ½Ã½ºÅÛ ÀåÂø ¿©ºÎ ¹× ½Ã½ºÅÛ on/off Á¤º¸";
BA_ "UserSigValidity" SG_ 2239848450 FCA_Jnctn_OnOffEquipSta 3;
BA_REL_ "GenSigTimeoutTime" BU_SG_REL_ PSB SG_ 2239848450 FCA_Jnctn_OnOffEquipSta 1500;
BA_ "RoutingFactor" SG_ 2239848450 FCA_Jnctn_OnOffEquipSta 5;
BA_ "Version" SG_ 2239848450 FCA_Jnctn_OnOffEquipSta "17.11.00";
BA_ "Description" SG_ 2239848450 HDP_EMOpSta "EM On (Not Active/Active), Off status";
BA_ "UserSigValidity" SG_ 2239848450 HDP_EMOpSta 3;
BA_ "RoutingFactor" SG_ 2239848450 HDP_EMOpSta 5;
BA_ "Version" SG_ 2239848450 HDP_EMOpSta "20.06.05";
BA_ "Description" SG_ 2239848450 FCA_WrngTrgtDis "Request CLU to activate the corresponding warning device(s) according to the type of FCA warning target.

- FCA °æ°í ´ë»ó Á¾·ùº° Ç¥½Ã Á¤º¸½ÅÈ£";
BA_ "UserSigValidity" SG_ 2239848450 FCA_WrngTrgtDis 3;
BA_REL_ "GenSigTimeoutTime" BU_SG_REL_ APSU SG_ 2239848450 FCA_WrngTrgtDis 1500;
BA_ "RoutingFactor" SG_ 2239848450 FCA_WrngTrgtDis 5;
BA_ "Version" SG_ 2239848450 FCA_WrngTrgtDis "19.03.06";
BA_ "Description" SG_ 2239848450 ADAS_DRV_FCA_Plus_Sta "Àü¹æÄ«¸Þ¶ó, Àü¹æ·¹ÀÌ´õ ¹× ÀüÃø¹æ ·¹ÀÌ´õ/ÈÄÃø¹æ ·¹ÀÌÅÍ Ç»Àü Æ®·¢À» ÅëÇØ FCA-Car Å¸°Ù ¹× ÀÚÂ÷ ÁÂÃø/¿ìÃø ¿µ¿ª È¸ÇÇ ºÒ°¡´É ¿©ºÎ¸¦ ÆÇ´ÜÇÏ¿© FCA-Car/Ped/Cyc+ Flag¸¦ Ãâ·ÂÇÔ";
BA_ "UserSigValidity" SG_ 2239848450 ADAS_DRV_FCA_Plus_Sta 3;
BA_ "RoutingFactor" SG_ 2239848450 ADAS_DRV_FCA_Plus_Sta 5;
BA_ "Version" SG_ 2239848450 ADAS_DRV_FCA_Plus_Sta "18.08.06";
BA_ "Description" SG_ 2239848450 ADAS_TrlOffStaDisp "This signal describes ADAS system automatically off by trailer connected.";
BA_ "UserSigValidity" SG_ 2239848450 ADAS_TrlOffStaDisp 3;
BA_ "RoutingFactor" SG_ 2239848450 ADAS_TrlOffStaDisp 5;
BA_ "Version" SG_ 2239848450 ADAS_TrlOffStaDisp "20.12.01";
BA_ "Description" SG_ 2239848450 FCA_FrOnOffEquipSta "This signal describes the FCA-Car/Ped/Cyc/JT state.

- Front Camera Only: FCA-Car/Ped/Cyc

- Sensor Fusion: FCA-Car/Ped/Cyc/JT



 FCA-Car/Ped/Cyc/JT Àû¿ë ¿©ºÎ ¹× On/Off Á¤º¸

- Àü¹æ Ä«¸Þ¶ó ´Üµ¶: FCA-Car/Ped/Cyc

- ¼¾¼­Ç»Àü: FCA-Car/Ped/Cyc/JT";
BA_ "UserSigValidity" SG_ 2239848450 FCA_FrOnOffEquipSta 3;
BA_ "RoutingFactor" SG_ 2239848450 FCA_FrOnOffEquipSta 5;
BA_ "Version" SG_ 2239848450 FCA_FrOnOffEquipSta "20.12.03";
BA_ "Description" SG_ 2239848450 FCA_JC_OnOffEquipSta "This signal describes the FCA-JC state.

 - FCA-JC Àû¿ë ¿©ºÎ ¹× On/Off Á¤º¸";
BA_ "UserSigValidity" SG_ 2239848450 FCA_JC_OnOffEquipSta 3;
BA_ "RoutingFactor" SG_ 2239848450 FCA_JC_OnOffEquipSta 5;
BA_ "Version" SG_ 2239848450 FCA_JC_OnOffEquipSta "20.12.03";
BA_ "Description" SG_ 2239848450 FCA_FrSdOnOffEquipSta "This signal describes the FCA-LO/LS, w/ ESA state.

 - FCA-LO/LS, w/ ESA Àû¿ë ¿©ºÎ ¹×  On/Off Á¤º¸";
BA_ "UserSigValidity" SG_ 2239848450 FCA_FrSdOnOffEquipSta 3;
BA_ "RoutingFactor" SG_ 2239848450 FCA_FrSdOnOffEquipSta 5;
BA_ "Version" SG_ 2239848450 FCA_FrSdOnOffEquipSta "20.12.03";
BA_ "Description" SG_ 2239848450 EM_WrngLvlSta "Request CLU to activate the corresponding warning device(s) according to the EM warning level. (Braking / Steering act)

- EM ±â´ÉÀÇ Á¦µ¿ ¹× Á¶Çâ Á¦¾î ÀÛµ¿ »óÅÂ Ç¥½Ã¿ë Á¤º¸½ÅÈ£";
BA_ "UserSigValidity" SG_ 2239848450 EM_WrngLvlSta 3;
BA_ "RoutingFactor" SG_ 2239848450 EM_WrngLvlSta 5;
BA_ "Version" SG_ 2239848450 EM_WrngLvlSta "19.12.00";
BA_ "Description" SG_ 2239848450 BrkDelVLimReq "- Request ESC whether to release brake control or not when FCA or EM function reduces vehicle¡¯s velocity over 50km/h for ISO 26262.

- FCA ¶Ç´Â EM ÀÛµ¿ Áß ESC°¡ 50km/h ÃÊ°ú °¨¼Ó ½Ã Á¦µ¿Á¦¾î ÇØÁ¦/¹ÌÇØÁ¦ ¿äÃ» ½ÅÈ£ (ISO 26262 ´ëÀÀ)";
BA_ "UserSigValidity" SG_ 2239848450 BrkDelVLimReq 3;
BA_ "RoutingFactor" SG_ 2239848450 BrkDelVLimReq 5;
BA_ "Version" SG_ 2239848450 BrkDelVLimReq "20.03.00";
BA_ "Description" SG_ 2239848450 ADAS_InhbtOffDispSta "This Signal dispaly the ADAS System off inhibition state 

- »óÈ²¿¡ µû¸¥ ADAS ½Ã½ºÅÛ ²ô±â ±ÝÁö »óÅÂ Ç¥½Ã ½ÅÈ£";
BA_ "UserSigValidity" SG_ 2239848450 ADAS_InhbtOffDispSta 3;
BA_ "RoutingFactor" SG_ 2239848450 ADAS_InhbtOffDispSta 5;
BA_ "Version" SG_ 2239848450 ADAS_InhbtOffDispSta "20.12.00";
BA_ "Description" SG_ 2239848450 FCA_WarnTimeSta "This signal describes the FCA warning timing state.

 - FCA °æ°í ½ÃÁ¡ Á¤º¸";
BA_ "UserSigValidity" SG_ 2239848450 FCA_WarnTimeSta 3;
BA_ "RoutingFactor" SG_ 2239848450 FCA_WarnTimeSta 5;
BA_ "Version" SG_ 2239848450 FCA_WarnTimeSta "20.12.00";
BA_ "Description" SG_ 2239848450 FCA_TimetoCllsn "This signal indicates predictive time to Collision between the host vehicle and a forward vehicle.







(PH) = 10*(HEX) [ms]



CAN Message Physical range : 0 ~ 2540 [ms], Resolution : 10ms";
BA_ "GenSigStartValue" SG_ 2239848450 FCA_TimetoCllsn 254;
BA_ "UserSigValidity" SG_ 2239848450 FCA_TimetoCllsn 3;
BA_ "RoutingFactor" SG_ 2239848450 FCA_TimetoCllsn 5;
BA_ "Version" SG_ 2239848450 FCA_TimetoCllsn "19.06.03";
BA_ "GenMsgSendType" BO_ 2256644609 0;
BA_ "GenMsgCycleTime" BO_ 2256644609 100;
BA_ "GenMsgCycleTimeFast" BO_ 2256644609 0;
BA_ "GenMsgNrOfRepetition" BO_ 2256644609 0;
BA_ "VFrameFormat" BO_ 2256644609 1;
BA_ "Description" SG_ 2256644609 CLU_Crc1Val "The data area for CRC calculation is based on the data length (DLC) of the message DB.

The CRC shall be calculated over the entire data block (excluding the CRC bytes) including the user data, alive counter and Data ID

 

- CRC Polynomial (0x1021) , Initial Value : 0xFFFF, XOR value : 0x0000, Data ID : Message ID + 0xF800 

- The initial value is for CRC calculation and the message should be sent with the calculated result value. 

- The mathematical expression to 16 bit CRC polynomial is given here. G(x) = x16 + x12 + x5 + 1";
BA_ "GenSigStartValue" SG_ 2256644609 CLU_Crc1Val 65535;
BA_ "UserSigValidity" SG_ 2256644609 CLU_Crc1Val 3;
BA_REL_ "GenSigTimeoutTime" BU_SG_REL_ SHVU_RR SG_ 2256644609 CLU_Crc1Val 1500;
BA_REL_ "GenSigTimeoutTime" BU_SG_REL_ DPSU SG_ 2256644609 CLU_Crc1Val 1500;
BA_REL_ "GenSigTimeoutTime" BU_SG_REL_ ATS SG_ 2256644609 CLU_Crc1Val 1500;
BA_ "RoutingFactor" SG_ 2256644609 CLU_Crc1Val 5;
BA_ "Version" SG_ 2256644609 CLU_Crc1Val "18.11.08";
BA_ "Description" SG_ 2256644609 CLU_AlvCnt1Val "For the first transmission request for a data element the counter shall be initialized with 0 and shall be incremented by 1 for every subsequent send request. 

When the counter reaches the maximum value(0xFF), then it shall restart with 0 for the next send request";
BA_ "UserSigValidity" SG_ 2256644609 CLU_AlvCnt1Val 3;
BA_REL_ "GenSigTimeoutTime" BU_SG_REL_ SHVU_RR SG_ 2256644609 CLU_AlvCnt1Val 1500;
BA_REL_ "GenSigTimeoutTime" BU_SG_REL_ DPSU SG_ 2256644609 CLU_AlvCnt1Val 1500;
BA_REL_ "GenSigTimeoutTime" BU_SG_REL_ ATS SG_ 2256644609 CLU_AlvCnt1Val 1500;
BA_REL_ "GenSigTimeoutTime" BU_SG_REL_ EMCU SG_ 2256644609 CLU_AlvCnt1Val 1500;
BA_ "RoutingFactor" SG_ 2256644609 CLU_AlvCnt1Val 5;
BA_ "Version" SG_ 2256644609 CLU_AlvCnt1Val "18.11.08";
BA_ "Description" SG_ 2256644609 CLU_DtntOutSta "This signal indicates the status of detent illumination. Cluster sends the detent information for a Unified Illumination system.";
BA_ "UserSigValidity" SG_ 2256644609 CLU_DtntOutSta 0;
BA_REL_ "GenSigTimeoutTime" BU_SG_REL_ FCS SG_ 2256644609 CLU_DtntOutSta 1500;
BA_REL_ "GenSigTimeoutTime" BU_SG_REL_ WPC SG_ 2256644609 CLU_DtntOutSta 1500;
BA_REL_ "GenSigTimeoutTime" BU_SG_REL_ RWPC SG_ 2256644609 CLU_DtntOutSta 1500;
BA_REL_ "GenSigTimeoutTime" BU_SG_REL_ SWRC SG_ 2256644609 CLU_DtntOutSta 1500;
BA_REL_ "GenSigTimeoutTime" BU_SG_REL_ APSU SG_ 2256644609 CLU_DtntOutSta 1500;
BA_REL_ "GenSigTimeoutTime" BU_SG_REL_ RLHV SG_ 2256644609 CLU_DtntOutSta 1500;
BA_REL_ "GenSigTimeoutTime" BU_SG_REL_ RRHV SG_ 2256644609 CLU_DtntOutSta 1500;
BA_REL_ "GenSigTimeoutTime" BU_SG_REL_ SHVU_FR SG_ 2256644609 CLU_DtntOutSta 1500;
BA_REL_ "GenSigTimeoutTime" BU_SG_REL_ SHVU_RR SG_ 2256644609 CLU_DtntOutSta 1500;
BA_REL_ "GenSigTimeoutTime" BU_SG_REL_ DPSU SG_ 2256644609 CLU_DtntOutSta 1500;
BA_REL_ "GenSigTimeoutTime" BU_SG_REL_ RCS SG_ 2256644609 CLU_DtntOutSta 1500;
BA_REL_ "GenSigTimeoutTime" BU_SG_REL_ RRPSU SG_ 2256644609 CLU_DtntOutSta 1500;
BA_REL_ "GenSigTimeoutTime" BU_SG_REL_ RLPSU SG_ 2256644609 CLU_DtntOutSta 1500;
BA_REL_ "GenSigTimeoutTime" BU_SG_REL_ ATS SG_ 2256644609 CLU_DtntOutSta 1500;
BA_REL_ "GenSigTimeoutTime" BU_SG_REL_ DSAU SG_ 2256644609 CLU_DtntOutSta 1500;
BA_REL_ "GenSigTimeoutTime" BU_SG_REL_ ASAU SG_ 2256644609 CLU_DtntOutSta 1500;
BA_REL_ "GenSigTimeoutTime" BU_SG_REL_ OHCL SG_ 2256644609 CLU_DtntOutSta 1500;
BA_ "RoutingFactor" SG_ 2256644609 CLU_DtntOutSta 5;
BA_ "Version" SG_ 2256644609 CLU_DtntOutSta "17.11.00";
BA_ "Description" SG_ 2256644609 CLU_SpdUnitTyp "This signal indicates the unit of the speed displayed in the speedometer.";
BA_ "UserSigValidity" SG_ 2256644609 CLU_SpdUnitTyp 3;
BA_REL_ "GenSigTimeoutTime" BU_SG_REL_ DPSU SG_ 2256644609 CLU_SpdUnitTyp 1500;
BA_REL_ "GenSigTimeoutTime" BU_SG_REL_ BLTN_CAM SG_ 2256644609 CLU_SpdUnitTyp 1500;
BA_REL_ "GenSigTimeoutTime" BU_SG_REL_ EMCU SG_ 2256644609 CLU_SpdUnitTyp 1500;
BA_ "RoutingFactor" SG_ 2256644609 CLU_SpdUnitTyp 5;
BA_ "Version" SG_ 2256644609 CLU_SpdUnitTyp "17.11.00";
BA_ "Description" SG_ 2256644609 CLU_DisSpdDcmlVal "The signal 'CF_Clu_VanzDecimal' means the extra value of the signal 'CF_Clu_Vanz' (vehicle speed which is indicated in the speedometer)

Also, This signal should be sent in km/h or MPH according to the 'CF_Clu_SPEED_UNIT' signal.

CF_Clu_SPEED_UNIT = 0 : [km/h]

CF_Clu_SPEED_UNIT = 1 : [MPH]



Example)   CF_Clu_Vanz = 13,  CF_Clu_VanzDecimal  = 3

Displayed vehicle speed  = (CF_Clu_Vanz / 2) + (CF_Clu_VanzDecimal / 8)

= ( 13 / 2 ) + ( 3 / 8 ) = 6.875 [Km/h or MPH]";
BA_ "UserSigValidity" SG_ 2256644609 CLU_DisSpdDcmlVal 3;
BA_ "RoutingFactor" SG_ 2256644609 CLU_DisSpdDcmlVal 5;
BA_ "Version" SG_ 2256644609 CLU_DisSpdDcmlVal "17.11.00";
BA_ "Description" SG_ 2256644609 CLU_SWRCCrsMainSwSta "Cruise on/off switch";
BA_ "UserSigValidity" SG_ 2256644609 CLU_SWRCCrsMainSwSta 3;
BA_ "RoutingFactor" SG_ 2256644609 CLU_SWRCCrsMainSwSta 5;
BA_ "Version" SG_ 2256644609 CLU_SWRCCrsMainSwSta "18.04.00";
BA_ "Description" SG_ 2256644609 CLU_SWRCCrsSwSta "Depending on whether One-touch logic is applied, the meaning of each signal value is divided into two cases as shown below



Case1) Not applied

0x0:Idle Position

0x1:Resume/Plus

0x2:Set/Minus

0x3:Time gap (Distance, SCC only)

0x4:ACC/SCC cancel



Case2) Applied

0x0: Idle Position

0x1: Plus/Set

0x2: Minus/Set

0x3: Time gap (Distance, SCC only)

0x4: Pause/Resume";
BA_ "UserSigValidity" SG_ 2256644609 CLU_SWRCCrsSwSta 3;
BA_ "RoutingFactor" SG_ 2256644609 CLU_SWRCCrsSwSta 5;
BA_ "Version" SG_ 2256644609 CLU_SWRCCrsSwSta "18.07.01";
BA_ "Description" SG_ 2256644609 CLU_SWRCLFASwSta "LFA/HDA on/off switch";
BA_ "UserSigValidity" SG_ 2256644609 CLU_SWRCLFASwSta 3;
BA_ "RoutingFactor" SG_ 2256644609 CLU_SWRCLFASwSta 5;
BA_ "Version" SG_ 2256644609 CLU_SWRCLFASwSta "18.04.00";
BA_ "Description" SG_ 2256644609 CLU_SWRCSldMainSwSta "Speedlimiter on/off switch";
BA_ "UserSigValidity" SG_ 2256644609 CLU_SWRCSldMainSwSta 3;
BA_ "RoutingFactor" SG_ 2256644609 CLU_SWRCSldMainSwSta 5;
BA_ "Version" SG_ 2256644609 CLU_SWRCSldMainSwSta "18.04.00";
BA_ "Description" SG_ 2256644609 CLU_RhstaLvlSta "This signal is used for a rheostat level of CLUSTER from 1 to 21 level (21 level : Detent) for a Unified Illumination system.



¡Ø Start Value : Current value";
BA_ "UserSigValidity" SG_ 2256644609 CLU_RhstaLvlSta 0;
BA_REL_ "GenSigTimeoutTime" BU_SG_REL_ FCS SG_ 2256644609 CLU_RhstaLvlSta 1500;
BA_REL_ "GenSigTimeoutTime" BU_SG_REL_ WPC SG_ 2256644609 CLU_RhstaLvlSta 1500;
BA_REL_ "GenSigTimeoutTime" BU_SG_REL_ RWPC SG_ 2256644609 CLU_RhstaLvlSta 1500;
BA_REL_ "GenSigTimeoutTime" BU_SG_REL_ SWRC SG_ 2256644609 CLU_RhstaLvlSta 1500;
BA_REL_ "GenSigTimeoutTime" BU_SG_REL_ APSU SG_ 2256644609 CLU_RhstaLvlSta 1500;
BA_REL_ "GenSigTimeoutTime" BU_SG_REL_ RLHV SG_ 2256644609 CLU_RhstaLvlSta 1500;
BA_REL_ "GenSigTimeoutTime" BU_SG_REL_ RRHV SG_ 2256644609 CLU_RhstaLvlSta 1500;
BA_REL_ "GenSigTimeoutTime" BU_SG_REL_ SHVU_FR SG_ 2256644609 CLU_RhstaLvlSta 1500;
BA_REL_ "GenSigTimeoutTime" BU_SG_REL_ SHVU_RR SG_ 2256644609 CLU_RhstaLvlSta 1500;
BA_REL_ "GenSigTimeoutTime" BU_SG_REL_ DPSU SG_ 2256644609 CLU_RhstaLvlSta 1500;
BA_REL_ "GenSigTimeoutTime" BU_SG_REL_ RCS SG_ 2256644609 CLU_RhstaLvlSta 1500;
BA_REL_ "GenSigTimeoutTime" BU_SG_REL_ RRPSU SG_ 2256644609 CLU_RhstaLvlSta 1500;
BA_REL_ "GenSigTimeoutTime" BU_SG_REL_ RLPSU SG_ 2256644609 CLU_RhstaLvlSta 1500;
BA_REL_ "GenSigTimeoutTime" BU_SG_REL_ ATS SG_ 2256644609 CLU_RhstaLvlSta 1500;
BA_REL_ "GenSigTimeoutTime" BU_SG_REL_ DSAU SG_ 2256644609 CLU_RhstaLvlSta 1500;
BA_REL_ "GenSigTimeoutTime" BU_SG_REL_ ASAU SG_ 2256644609 CLU_RhstaLvlSta 1500;
BA_REL_ "GenSigTimeoutTime" BU_SG_REL_ OHCL SG_ 2256644609 CLU_RhstaLvlSta 1500;
BA_ "RoutingFactor" SG_ 2256644609 CLU_RhstaLvlSta 5;
BA_ "Version" SG_ 2256644609 CLU_RhstaLvlSta "17.11.00";
BA_ "Description" SG_ 2256644609 CLU_DisSpdVal "The vehicle speed which is indicated in the speedmeter has to be sent to SCC. This value is used for evalution of SCC command values instead of the vehicle velocity in order to avoid significant difference between the speedmeter indicator and the set speed indicator(especially in the case of free cruising with the set speed). In terms of debouning and presnce on CAN, the same time scales have to be used and described for time gap setting.

This signal should be sent in km/h or MPH according to the ¡°SPEED_UNIT¡± signal.

SPEED_UNIT = 0 : [km/h]

SPEED_UNIT = 1 : [MPH]";
BA_ "UserSigValidity" SG_ 2256644609 CLU_DisSpdVal 3;
BA_REL_ "GenSigTimeoutTime" BU_SG_REL_ APSU SG_ 2256644609 CLU_DisSpdVal 1500;
BA_REL_ "GenSigTimeoutTime" BU_SG_REL_ DPSU SG_ 2256644609 CLU_DisSpdVal 1500;
BA_REL_ "GenSigTimeoutTime" BU_SG_REL_ BLTN_CAM SG_ 2256644609 CLU_DisSpdVal 1500;
BA_REL_ "GenSigTimeoutTime" BU_SG_REL_ EMCU SG_ 2256644609 CLU_DisSpdVal 1500;
BA_ "RoutingFactor" SG_ 2256644609 CLU_DisSpdVal 5;
BA_ "Version" SG_ 2256644609 CLU_DisSpdVal "17.12.03";
BA_ "Description" SG_ 2256644609 CLU_OKSwSta "This signal represents operating status of Ok Switch in Steering Wheel. Default value of this signal is 0 and the value is set to 1 only while a driver is pressing the OK Switch.";
BA_ "UserSigValidity" SG_ 2256644609 CLU_OKSwSta 3;
BA_ "RoutingFactor" SG_ 2256644609 CLU_OKSwSta 5;
BA_ "Version" SG_ 2256644609 CLU_OKSwSta "19.03.06";
BA_ "GenMsgSendType" BO_ 2256644610 0;
BA_ "GenMsgCycleTime" BO_ 2256644610 100;
BA_ "GenMsgCycleTimeFast" BO_ 2256644610 0;
BA_ "GenMsgNrOfRepetition" BO_ 2256644610 0;
BA_ "VFrameFormat" BO_ 2256644610 1;
BA_ "Description" SG_ 2256644610 CLU_DisSpdVal_KPH "The vehicle speed which is indicated in the speedmeter.

This signal should be sent in km/h only.";
BA_ "UserSigValidity" SG_ 2256644610 CLU_DisSpdVal_KPH 3;
BA_REL_ "GenSigTimeoutTime" BU_SG_REL_ WPC SG_ 2256644610 CLU_DisSpdVal_KPH 1500;
BA_REL_ "GenSigTimeoutTime" BU_SG_REL_ RWPC SG_ 2256644610 CLU_DisSpdVal_KPH 1500;
BA_REL_ "GenSigTimeoutTime" BU_SG_REL_ APSU SG_ 2256644610 CLU_DisSpdVal_KPH 1500;
BA_REL_ "GenSigTimeoutTime" BU_SG_REL_ RLHV SG_ 2256644610 CLU_DisSpdVal_KPH 1500;
BA_REL_ "GenSigTimeoutTime" BU_SG_REL_ RRHV SG_ 2256644610 CLU_DisSpdVal_KPH 1500;
BA_REL_ "GenSigTimeoutTime" BU_SG_REL_ SHVU_FR SG_ 2256644610 CLU_DisSpdVal_KPH 1500;
BA_REL_ "GenSigTimeoutTime" BU_SG_REL_ SHVU_RR SG_ 2256644610 CLU_DisSpdVal_KPH 1500;
BA_REL_ "GenSigTimeoutTime" BU_SG_REL_ DPSU SG_ 2256644610 CLU_DisSpdVal_KPH 1500;
BA_REL_ "GenSigTimeoutTime" BU_SG_REL_ DLBCU SG_ 2256644610 CLU_DisSpdVal_KPH 1500;
BA_REL_ "GenSigTimeoutTime" BU_SG_REL_ PFSU SG_ 2256644610 CLU_DisSpdVal_KPH 1500;
BA_REL_ "GenSigTimeoutTime" BU_SG_REL_ RRPSU SG_ 2256644610 CLU_DisSpdVal_KPH 1500;
BA_REL_ "GenSigTimeoutTime" BU_SG_REL_ RLPSU SG_ 2256644610 CLU_DisSpdVal_KPH 1500;
BA_REL_ "GenSigTimeoutTime" BU_SG_REL_ ATS SG_ 2256644610 CLU_DisSpdVal_KPH 1500;
BA_REL_ "GenSigTimeoutTime" BU_SG_REL_ DSAU SG_ 2256644610 CLU_DisSpdVal_KPH 1500;
BA_REL_ "GenSigTimeoutTime" BU_SG_REL_ ASAU SG_ 2256644610 CLU_DisSpdVal_KPH 1500;
BA_REL_ "GenSigTimeoutTime" BU_SG_REL_ RCM SG_ 2256644610 CLU_DisSpdVal_KPH 1500;
BA_REL_ "GenSigTimeoutTime" BU_SG_REL_ ALBCU SG_ 2256644610 CLU_DisSpdVal_KPH 1500;
BA_ "RoutingFactor" SG_ 2256644610 CLU_DisSpdVal_KPH 5;
BA_ "Version" SG_ 2256644610 CLU_DisSpdVal_KPH "17.12.09";
BA_ "Description" SG_ 2256644610 CLU_CUSTOMSta_NEW "This is a signal for New concept CUSTOM mode in AVN USM

This is a confirm signal for selecting CUSTOM mode in AVN USM

And Other units refer this signal when CUSTOM mode (CLU_DrvngModSwSta=0x6

). Other unit decided the Detailed CUSTOM Mode with this signal

EX>

 In AVN USM, MY DRIVE MODE is selected, sent CLU_CUSTOMSta_NEW= 0x1

In vehicle, current mode is MY DRIVE MODE, other unit refer this signal and decide detailed Mode.In this case, MY DRIVE MODE is a mode";
BA_ "UserSigValidity" SG_ 2256644610 CLU_CUSTOMSta_NEW 3;
BA_ "RoutingFactor" SG_ 2256644610 CLU_CUSTOMSta_NEW 5;
BA_ "Version" SG_ 2256644610 CLU_CUSTOMSta_NEW "20.08.07";
BA_ "Description" SG_ 2256644610 CLU_AutoBrightSta "This signal is used for a auto bright level of CLUSTER from 1step to 200step for a Unified Illumination system.



¡Ø Start Value : Current value";
BA_ "UserSigValidity" SG_ 2256644610 CLU_AutoBrightSta 0;
BA_REL_ "GenSigTimeoutTime" BU_SG_REL_ FCS SG_ 2256644610 CLU_AutoBrightSta 1500;
BA_REL_ "GenSigTimeoutTime" BU_SG_REL_ WPC SG_ 2256644610 CLU_AutoBrightSta 1500;
BA_REL_ "GenSigTimeoutTime" BU_SG_REL_ RWPC SG_ 2256644610 CLU_AutoBrightSta 1500;
BA_REL_ "GenSigTimeoutTime" BU_SG_REL_ SWRC SG_ 2256644610 CLU_AutoBrightSta 1500;
BA_REL_ "GenSigTimeoutTime" BU_SG_REL_ APSU SG_ 2256644610 CLU_AutoBrightSta 1500;
BA_REL_ "GenSigTimeoutTime" BU_SG_REL_ RLHV SG_ 2256644610 CLU_AutoBrightSta 1500;
BA_REL_ "GenSigTimeoutTime" BU_SG_REL_ RRHV SG_ 2256644610 CLU_AutoBrightSta 1500;
BA_REL_ "GenSigTimeoutTime" BU_SG_REL_ SHVU_FR SG_ 2256644610 CLU_AutoBrightSta 1500;
BA_REL_ "GenSigTimeoutTime" BU_SG_REL_ SHVU_RR SG_ 2256644610 CLU_AutoBrightSta 1500;
BA_REL_ "GenSigTimeoutTime" BU_SG_REL_ DPSU SG_ 2256644610 CLU_AutoBrightSta 1500;
BA_REL_ "GenSigTimeoutTime" BU_SG_REL_ RCS SG_ 2256644610 CLU_AutoBrightSta 1500;
BA_REL_ "GenSigTimeoutTime" BU_SG_REL_ ATS SG_ 2256644610 CLU_AutoBrightSta 1500;
BA_REL_ "GenSigTimeoutTime" BU_SG_REL_ DSAU SG_ 2256644610 CLU_AutoBrightSta 1500;
BA_REL_ "GenSigTimeoutTime" BU_SG_REL_ ASAU SG_ 2256644610 CLU_AutoBrightSta 1500;
BA_REL_ "GenSigTimeoutTime" BU_SG_REL_ OHCL SG_ 2256644610 CLU_AutoBrightSta 1500;
BA_REL_ "GenSigTimeoutTime" BU_SG_REL_ BLTN_CAM SG_ 2256644610 CLU_AutoBrightSta 1500;
BA_ "RoutingFactor" SG_ 2256644610 CLU_AutoBrightSta 5;
BA_ "Version" SG_ 2256644610 CLU_AutoBrightSta "20.12.05";
BA_ "Description" SG_ 2256644610 CLU_PwrAutoOffResetReq_HCU "This signal is used for a request to reset power auto off time

when OK sw on, this signal 0x1 for 3 period times,and send 0x0 

It is signal for HCU";
BA_ "UserSigValidity" SG_ 2256644610 CLU_PwrAutoOffResetReq_HCU 3;
BA_ "RoutingFactor" SG_ 2256644610 CLU_PwrAutoOffResetReq_HCU 5;
BA_ "Version" SG_ 2256644610 CLU_PwrAutoOffResetReq_HCU "19.10.03";
BA_ "GenMsgCycleTime" BO_ 2470761217 0;
BA_ "VFrameFormat" BO_ 2470761217 1;
BA_ "Description" SG_ 2470761217 CLU_Crc7Val "The data area for CRC calculation is based on the data length (DLC) of the message DB.

The CRC shall be calculated over the entire data block (excluding the CRC bytes) including the user data, alive counter and Data ID

 

- CRC Polynomial (0x1021) , Initial Value : 0xFFFF, XOR value : 0x0000, Data ID : Message ID + 0xF800 

- The initial value is for CRC calculation and the message should be sent with the calculated result value. 

- The mathematical expression to 16 bit CRC polynomial is given here. G(x) = x16 + x12 + x5 + 1";
BA_ "GenSigSendType" SG_ 2470761217 CLU_Crc7Val 4;
BA_ "GenSigStartValue" SG_ 2470761217 CLU_Crc7Val 65535;
BA_ "UserSigValidity" SG_ 2470761217 CLU_Crc7Val 3;
BA_ "Version" SG_ 2470761217 CLU_Crc7Val "18.11.08";
BA_ "Description" SG_ 2470761217 CLU_AlvCnt7Val "For the first transmission request for a data element the counter shall be initialized with 0 and shall be incremented by 1 for every subsequent send request. 

When the counter reaches the maximum value(0xFF), then it shall restart with 0 for the next send request";
BA_ "GenSigSendType" SG_ 2470761217 CLU_AlvCnt7Val 4;
BA_ "UserSigValidity" SG_ 2470761217 CLU_AlvCnt7Val 3;
BA_ "Version" SG_ 2470761217 CLU_AlvCnt7Val "18.11.08";
BA_ "Description" SG_ 2470761217 USM_AutoDrLkSetReq "Request set the new Auto Door Lock Mode";
BA_ "GenSigSendType" SG_ 2470761217 USM_AutoDrLkSetReq 4;
BA_ "UserSigValidity" SG_ 2470761217 USM_AutoDrLkSetReq 3;
BA_ "Version" SG_ 2470761217 USM_AutoDrLkSetReq "17.11.00";
BA_ "Description" SG_ 2470761217 USM_AutoDrUnlckSetReq "Request to set Auto Door Unlock Mode";
BA_ "GenSigSendType" SG_ 2470761217 USM_AutoDrUnlckSetReq 4;
BA_ "UserSigValidity" SG_ 2470761217 USM_AutoDrUnlckSetReq 3;
BA_ "Version" SG_ 2470761217 USM_AutoDrUnlckSetReq "17.11.00";
BA_ "Description" SG_ 2470761217 USM_HLmpEscrtSetReq "Request to set Head Lamp Escort Option";
BA_ "GenSigSendType" SG_ 2470761217 USM_HLmpEscrtSetReq 4;
BA_ "UserSigValidity" SG_ 2470761217 USM_HLmpEscrtSetReq 3;
BA_ "Version" SG_ 2470761217 USM_HLmpEscrtSetReq "17.11.00";
BA_ "Description" SG_ 2470761217 USM_SmrtTrnkSetReq "Request to set Smart Trunk/Tailgate Mode";
BA_ "GenSigSendType" SG_ 2470761217 USM_SmrtTrnkSetReq 4;
BA_ "UserSigValidity" SG_ 2470761217 USM_SmrtTrnkSetReq 3;
BA_ "Version" SG_ 2470761217 USM_SmrtTrnkSetReq "17.11.00";
BA_ "Description" SG_ 2470761217 USM_MdLmpSetReq "Request to set interior mood lamp setting";
BA_ "GenSigSendType" SG_ 2470761217 USM_MdLmpSetReq 4;
BA_ "UserSigValidity" SG_ 2470761217 USM_MdLmpSetReq 3;
BA_ "Version" SG_ 2470761217 USM_MdLmpSetReq "17.11.00";
BA_ "Description" SG_ 2470761217 USM_HrnAnswerBckSetReq "Request to set Horn Answer Back Mode";
BA_ "GenSigSendType" SG_ 2470761217 USM_HrnAnswerBckSetReq 4;
BA_ "UserSigValidity" SG_ 2470761217 USM_HrnAnswerBckSetReq 3;
BA_ "Version" SG_ 2470761217 USM_HrnAnswerBckSetReq "17.11.00";
BA_ "Description" SG_ 2470761217 USM_OneTouchTrplTrnSetReq "This signal is used for a request current setting value of USM Menus. When this signal change, the message (CLU14) is sent 3 times.";
BA_ "GenSigSendType" SG_ 2470761217 USM_OneTouchTrplTrnSetReq 4;
BA_ "UserSigValidity" SG_ 2470761217 USM_OneTouchTrplTrnSetReq 3;
BA_ "Version" SG_ 2470761217 USM_OneTouchTrplTrnSetReq "17.11.00";
BA_ "Description" SG_ 2470761217 USM_PsmSetReq "This signal is used for a request to set the value of UMS Menus.

This signal requests to set Seat Easy Access Mode.

When this signal change, the message (CLU14) is sent 3 times.";
BA_ "GenSigSendType" SG_ 2470761217 USM_PsmSetReq 4;
BA_ "UserSigValidity" SG_ 2470761217 USM_PsmSetReq 3;
BA_REL_ "GenSigTimeoutTime" BU_SG_REL_ DPSU SG_ 2470761217 USM_PsmSetReq 0;
BA_ "Version" SG_ 2470761217 USM_PsmSetReq "17.11.00";
BA_ "Description" SG_ 2470761217 USM_PtgmSetReq "Request to set PTGM Mode";
BA_ "GenSigSendType" SG_ 2470761217 USM_PtgmSetReq 4;
BA_ "UserSigValidity" SG_ 2470761217 USM_PtgmSetReq 3;
BA_ "Version" SG_ 2470761217 USM_PtgmSetReq "17.11.00";
BA_ "Description" SG_ 2470761217 USM_ScmSetReq "Request to set Steering Easy Access mode";
BA_ "GenSigSendType" SG_ 2470761217 USM_ScmSetReq 4;
BA_ "UserSigValidity" SG_ 2470761217 USM_ScmSetReq 3;
BA_ "Version" SG_ 2470761217 USM_ScmSetReq "17.11.00";
BA_ "Description" SG_ 2470761217 USM_OSTempUnitSetReq "This signal is used for a request to set the value of USM Menus. This signal requests to set Outside Temperature Unit.

When this signal change, the message (CLU14) is sent 3 times.";
BA_ "GenSigSendType" SG_ 2470761217 USM_OSTempUnitSetReq 4;
BA_ "UserSigValidity" SG_ 2470761217 USM_OSTempUnitSetReq 3;
BA_ "Version" SG_ 2470761217 USM_OSTempUnitSetReq "17.11.00";
BA_ "Description" SG_ 2470761217 USM_TfrChgSetReq "This signal is used for a request to set the value of UMS Menus.

This signal requests to set Traffic Change Mode.

When this signal change, the message (CLU4) is sent 3 times.";
BA_ "GenSigSendType" SG_ 2470761217 USM_TfrChgSetReq 4;
BA_ "UserSigValidity" SG_ 2470761217 USM_TfrChgSetReq 3;
BA_ "Version" SG_ 2470761217 USM_TfrChgSetReq "17.11.00";
BA_ "Description" SG_ 2470761217 USM_WALModSetreq "This signal is used for a request to set the value USM Menus.

This signal requests to set WAL(WalkAwayLock) function";
BA_ "GenSigSendType" SG_ 2470761217 USM_WALModSetreq 4;
BA_ "UserSigValidity" SG_ 2470761217 USM_WALModSetreq 3;
BA_ "Version" SG_ 2470761217 USM_WALModSetreq "18.10.02";
BA_ "Description" SG_ 2470761217 USM_EscOffSetReq "Request to set ESC OFF mode

If ESC off switch is not applied in vehicle, this signal is needed for USM menu";
BA_ "GenSigSendType" SG_ 2470761217 USM_EscOffSetReq 4;
BA_ "UserSigValidity" SG_ 2470761217 USM_EscOffSetReq 3;
BA_ "Version" SG_ 2470761217 USM_EscOffSetReq "18.07.03";
BA_ "Description" SG_ 2470761217 USM_PsmHgtSetReq "This signal is used for a request to set the value of UMS Menus.

This signal requests to set Seat Easy Access Mode.

When this signal change, the message (CLU_07_00ms) is sent 3 times.";
BA_ "GenSigSendType" SG_ 2470761217 USM_PsmHgtSetReq 4;
BA_ "UserSigValidity" SG_ 2470761217 USM_PsmHgtSetReq 3;
BA_ "Version" SG_ 2470761217 USM_PsmHgtSetReq "18.07.03";
BA_ "GenMsgCycleTime" BO_ 2445572097 0;
BA_ "VFrameFormat" BO_ 2445572097 1;
BA_ "Description" SG_ 2445572097 CLU_Crc11Val "The data area for CRC calculation is based on the data length (DLC) of the message DB.

The CRC shall be calculated over the entire data block (excluding the CRC bytes) including the user data, alive counter and Data ID

 

- CRC Polynomial (0x1021) , Initial Value : 0xFFFF, XOR value : 0x0000, Data ID : Message ID + 0xF800 

- The initial value is for CRC calculation and the message should be sent with the calculated result value. 

- The mathematical expression to 16 bit CRC polynomial is given here. G(x) = x16 + x12 + x5 + 1";
BA_ "GenSigSendType" SG_ 2445572097 CLU_Crc11Val 4;
BA_ "GenSigStartValue" SG_ 2445572097 CLU_Crc11Val 65535;
BA_ "UserSigValidity" SG_ 2445572097 CLU_Crc11Val 3;
BA_ "Version" SG_ 2445572097 CLU_Crc11Val "18.11.08";
BA_ "Description" SG_ 2445572097 CLU_AlvCnt11Val "For the first transmission request for a data element the counter shall be initialized with 0 and shall be incremented by 1 for every subsequent send request. 

When the counter reaches the maximum value(0xFF), then it shall restart with 0 for the next send request";
BA_ "GenSigSendType" SG_ 2445572097 CLU_AlvCnt11Val 4;
BA_ "UserSigValidity" SG_ 2445572097 CLU_AlvCnt11Val 3;
BA_ "Version" SG_ 2445572097 CLU_AlvCnt11Val "18.11.08";
BA_ "Description" SG_ 2445572097 CLU_ICUDlvrModOffSetReq "This signal is used for a request to set off the delivery mode for ICU";
BA_ "GenSigSendType" SG_ 2445572097 CLU_ICUDlvrModOffSetReq 4;
BA_ "UserSigValidity" SG_ 2445572097 CLU_ICUDlvrModOffSetReq 3;
BA_ "Version" SG_ 2445572097 CLU_ICUDlvrModOffSetReq "17.12.03";
BA_ "Description" SG_ 2445572097 CLU_SMKKeyOutWarnOffReq "This signal is used for a request to SMK warn off request";
BA_ "GenSigSendType" SG_ 2445572097 CLU_SMKKeyOutWarnOffReq 4;
BA_ "UserSigValidity" SG_ 2445572097 CLU_SMKKeyOutWarnOffReq 3;
BA_ "Version" SG_ 2445572097 CLU_SMKKeyOutWarnOffReq "17.12.03";
BA_ "Description" SG_ 2445572097 CLU_SbwNModReq "This signal is for N Mode request in SBW variant";
BA_ "GenSigSendType" SG_ 2445572097 CLU_SbwNModReq 4;
BA_ "UserSigValidity" SG_ 2445572097 CLU_SbwNModReq 3;
BA_ "Version" SG_ 2445572097 CLU_SbwNModReq "18.08.10";
BA_ "Description" SG_ 2445572097 CLU_RrStRemindOffSetReq "Request to set off the Rear Seat Remind 2nd Alarm";
BA_ "GenSigSendType" SG_ 2445572097 CLU_RrStRemindOffSetReq 4;
BA_ "UserSigValidity" SG_ 2445572097 CLU_RrStRemindOffSetReq 0;
BA_REL_ "GenSigTimeoutTime" BU_SG_REL_ SWRC SG_ 2445572097 CLU_RrStRemindOffSetReq 0;
BA_ "Version" SG_ 2445572097 CLU_RrStRemindOffSetReq "19.07.04";
BA_ "Description" SG_ 2445572097 CLU_RrStRemindFdbckSetReq "Signal is if or not 1st ROA alert message in cluster";
BA_ "GenSigSendType" SG_ 2445572097 CLU_RrStRemindFdbckSetReq 4;
BA_ "UserSigValidity" SG_ 2445572097 CLU_RrStRemindFdbckSetReq 0;
BA_REL_ "GenSigTimeoutTime" BU_SG_REL_ SWRC SG_ 2445572097 CLU_RrStRemindFdbckSetReq 0;
BA_ "Version" SG_ 2445572097 CLU_RrStRemindFdbckSetReq "19.07.06";
BA_ "Description" SG_ 2445572097 CLU_PwrAutoOffResetReq "This signal is used for a request to reset power auto off time";
BA_ "GenSigSendType" SG_ 2445572097 CLU_PwrAutoOffResetReq 4;
BA_ "UserSigValidity" SG_ 2445572097 CLU_PwrAutoOffResetReq 3;
BA_ "Version" SG_ 2445572097 CLU_PwrAutoOffResetReq "18.12.02";
BA_ "Description" SG_ 2445572097 CLU_HDALCFuncOnSetReq "This signal is used for a request to set on lane change function of HDA.";
BA_ "GenSigSendType" SG_ 2445572097 CLU_HDALCFuncOnSetReq 4;
BA_ "UserSigValidity" SG_ 2445572097 CLU_HDALCFuncOnSetReq 3;
BA_ "Version" SG_ 2445572097 CLU_HDALCFuncOnSetReq "19.03.05";
BA_ "Description" SG_ 2445572097 CLU_WelcomeStartReq "Cluster welcome start signal (CLU -> AVN)";
BA_ "GenSigSendType" SG_ 2445572097 CLU_WelcomeStartReq 4;
BA_ "UserSigValidity" SG_ 2445572097 CLU_WelcomeStartReq 0;
BA_REL_ "GenSigTimeoutTime" BU_SG_REL_ SWRC SG_ 2445572097 CLU_WelcomeStartReq 0;
BA_ "Version" SG_ 2445572097 CLU_WelcomeStartReq "19.08.05";
BA_ "Description" SG_ 2445572097 CLU_HDAOnSetReq "This signal is used for a request to set on LFA/HDA

Applied when LFA button doesn't exist";
BA_ "GenSigSendType" SG_ 2445572097 CLU_HDAOnSetReq 4;
BA_ "UserSigValidity" SG_ 2445572097 CLU_HDAOnSetReq 3;
BA_ "Version" SG_ 2445572097 CLU_HDAOnSetReq "19.08.05";
BA_ "Description" SG_ 2445572097 CF_Clu_HCSSOSStopReq "This signal is used for a request to stop the SOS call.

When this signal change, the message is sent 3 times.";
BA_ "GenSigSendType" SG_ 2445572097 CF_Clu_HCSSOSStopReq 4;
BA_ "UserSigValidity" SG_ 2445572097 CF_Clu_HCSSOSStopReq 3;
BA_ "Version" SG_ 2445572097 CF_Clu_HCSSOSStopReq "19.01.10";
BA_ "Description" SG_ 2445572097 CLU_UpdateIGNIhn "This signal is only used by IBU for Ignition control.



This signal is applied for cluster software update



Other units should not use this signal.";
BA_ "GenSigSendType" SG_ 2445572097 CLU_UpdateIGNIhn 4;
BA_ "UserSigValidity" SG_ 2445572097 CLU_UpdateIGNIhn 0;
BA_ "Version" SG_ 2445572097 CLU_UpdateIGNIhn "20.12.04";
BA_ "Description" SG_ 2445572097 CLU_TpmsSetReq "This signal is for setting the reference pressure of the iTPMS system";
BA_ "GenSigSendType" SG_ 2445572097 CLU_TpmsSetReq 4;
BA_ "UserSigValidity" SG_ 2445572097 CLU_TpmsSetReq 0;
BA_ "Version" SG_ 2445572097 CLU_TpmsSetReq "20.10.00";
BA_ "GenMsgSendType" BO_ 2395189249 0;
BA_ "VFrameFormat" BO_ 2395189249 1;
BA_ "Description" SG_ 2395189249 DATC_Crc8Val "The data area for CRC calculation is based on the data length (DLC) of the message DB.

The CRC shall be calculated over the entire data block (excluding the CRC bytes) including the user data, alive counter and Data ID

 

- CRC Polynomial (0x1021) , Initial Value : 0xFFFF, XOR value : 0x0000, Data ID : Message ID + 0xF800 

- The initial value is for CRC calculation and the message should be sent with the calculated result value. 

- The mathematical expression to 16 bit CRC polynomial is given here. G(x) = x16 + x12 + x5 + 1";
BA_ "GenSigSendType" SG_ 2395189249 DATC_Crc8Val 4;
BA_ "GenSigStartValue" SG_ 2395189249 DATC_Crc8Val 65535;
BA_ "UserSigValidity" SG_ 2395189249 DATC_Crc8Val 3;
BA_ "Version" SG_ 2395189249 DATC_Crc8Val "18.11.08";
BA_ "Description" SG_ 2395189249 DATC_AlvCnt8Val "For the first transmission request for a data element the counter shall be initialized with 0 and shall be incremented by 1 for every subsequent send request. 

When the counter reaches the maximum value(0xFF), then it shall restart with 0 for the next send request";
BA_ "GenSigSendType" SG_ 2395189249 DATC_AlvCnt8Val 4;
BA_ "UserSigValidity" SG_ 2395189249 DATC_AlvCnt8Val 3;
BA_ "Version" SG_ 2395189249 DATC_AlvCnt8Val "18.11.08";
BA_ "GenSigSendType" SG_ 2395189249 DATC_SmrtVntOnOffSta 4;
BA_ "GenSigStartValue" SG_ 2395189249 DATC_SmrtVntOnOffSta 3;
BA_ "UserSigValidity" SG_ 2395189249 DATC_SmrtVntOnOffSta 3;
BA_ "Version" SG_ 2395189249 DATC_SmrtVntOnOffSta "17.11.00";
BA_ "GenSigSendType" SG_ 2395189249 DATC_PsAutoDis 4;
BA_ "UserSigValidity" SG_ 2395189249 DATC_PsAutoDis 3;
BA_REL_ "GenSigTimeoutTime" BU_SG_REL_ ATS SG_ 2395189249 DATC_PsAutoDis 1500;
BA_ "Version" SG_ 2395189249 DATC_PsAutoDis "17.11.00";
BA_ "GenSigSendType" SG_ 2395189249 DATC_RrOffDis 4;
BA_ "GenSigStartValue" SG_ 2395189249 DATC_RrOffDis 3;
BA_ "UserSigValidity" SG_ 2395189249 DATC_RrOffDis 3;
BA_ "Version" SG_ 2395189249 DATC_RrOffDis "17.11.00";
BA_ "GenSigSendType" SG_ 2395189249 DATC_RrAutoDis 4;
BA_ "UserSigValidity" SG_ 2395189249 DATC_RrAutoDis 3;
BA_REL_ "GenSigTimeoutTime" BU_SG_REL_ ATS SG_ 2395189249 DATC_RrAutoDis 1500;
BA_ "Version" SG_ 2395189249 DATC_RrAutoDis "17.11.00";
BA_ "GenSigSendType" SG_ 2395189249 DATC_RrDrvModDis 4;
BA_ "UserSigValidity" SG_ 2395189249 DATC_RrDrvModDis 7;
BA_REL_ "GenSigTimeoutTime" BU_SG_REL_ ATS SG_ 2395189249 DATC_RrDrvModDis 1500;
BA_ "Version" SG_ 2395189249 DATC_RrDrvModDis "18.11.05";
BA_ "GenSigSendType" SG_ 2395189249 DATC_RrPassModDis 4;
BA_ "UserSigValidity" SG_ 2395189249 DATC_RrPassModDis 7;
BA_REL_ "GenSigTimeoutTime" BU_SG_REL_ ATS SG_ 2395189249 DATC_RrPassModDis 1500;
BA_ "Version" SG_ 2395189249 DATC_RrPassModDis "18.11.05";
BA_ "Description" SG_ 2395189249 DATC_AutoArClnSysSta "This signal indicates Auto Air Cleaning System State for pop-up on OSD screen

(China region only apply)";
BA_ "GenSigSendType" SG_ 2395189249 DATC_AutoArClnSysSta 4;
BA_ "GenSigStartValue" SG_ 2395189249 DATC_AutoArClnSysSta 3;
BA_ "UserSigValidity" SG_ 2395189249 DATC_AutoArClnSysSta 7;
BA_ "Version" SG_ 2395189249 DATC_AutoArClnSysSta "20.01.01";
BA_ "Description" SG_ 2395189249 DATC_DisplayThemes "This signal indicates DATC lcd white or black themes. (only TFT LCD type)";
BA_ "GenSigSendType" SG_ 2395189249 DATC_DisplayThemes 4;
BA_ "UserSigValidity" SG_ 2395189249 DATC_DisplayThemes 7;
BA_ "Version" SG_ 2395189249 DATC_DisplayThemes "20.01.01";
BA_ "Description" SG_ 2395189249 DATC_AUTOStepPS "This signal indicates Passenger AUTO step status in case Multi Auto Blower type.";
BA_ "GenSigSendType" SG_ 2395189249 DATC_AUTOStepPS 4;
BA_ "UserSigValidity" SG_ 2395189249 DATC_AUTOStepPS 7;
BA_REL_ "GenSigTimeoutTime" BU_SG_REL_ ATS SG_ 2395189249 DATC_AUTOStepPS 1500;
BA_ "Version" SG_ 2395189249 DATC_AUTOStepPS "19.12.00";
BA_ "Description" SG_ 2395189249 DATC_AUTOStepRR "This signal indicates Rear AUTO step status in case Multi Auto Blower type.";
BA_ "GenSigSendType" SG_ 2395189249 DATC_AUTOStepRR 4;
BA_ "UserSigValidity" SG_ 2395189249 DATC_AUTOStepRR 7;
BA_REL_ "GenSigTimeoutTime" BU_SG_REL_ ATS SG_ 2395189249 DATC_AUTOStepRR 1500;
BA_ "Version" SG_ 2395189249 DATC_AUTOStepRR "19.12.00";
BA_ "Description" SG_ 2395189249 DATC_AutoArClnUSMState "Auto Air Cleaning USM State (China only apply)";
BA_ "GenSigSendType" SG_ 2395189249 DATC_AutoArClnUSMState 4;
BA_ "GenSigStartValue" SG_ 2395189249 DATC_AutoArClnUSMState 3;
BA_ "UserSigValidity" SG_ 2395189249 DATC_AutoArClnUSMState 7;
BA_ "Version" SG_ 2395189249 DATC_AutoArClnUSMState "19.12.00";
BA_ "GenMsgSendType" BO_ 2378398721 0;
BA_ "VFrameFormat" BO_ 2378398721 1;
BA_ "Description" SG_ 2378398721 DATC_Crc20Val "The data area for CRC calculation is based on the data length (DLC) of the message DB.

The CRC shall be calculated over the entire data block (excluding the CRC bytes) including the user data, alive counter and Data ID

 

- CRC Polynomial (0x1021) , Initial Value : 0xFFFF, XOR value : 0x0000, Data ID : Message ID + 0xF800 

- The initial value is for CRC calculation and the message should be sent with the calculated result value. 

- The mathematical expression to 16 bit CRC polynomial is given here. G(x) = x16 + x12 + x5 + 1";
BA_ "GenSigSendType" SG_ 2378398721 DATC_Crc20Val 4;
BA_ "GenSigStartValue" SG_ 2378398721 DATC_Crc20Val 65535;
BA_ "UserSigValidity" SG_ 2378398721 DATC_Crc20Val 3;
BA_ "Version" SG_ 2378398721 DATC_Crc20Val "21.01.02";
BA_ "Description" SG_ 2378398721 DATC_AlvCnt20Val "For the first transmission request for a data element the counter shall be initialized with 0 and shall be incremented by 1 for every subsequent send request. 

When the counter reaches the maximum value(0xFF), then it shall restart with 0 for the next send request";
BA_ "GenSigSendType" SG_ 2378398721 DATC_AlvCnt20Val 4;
BA_ "UserSigValidity" SG_ 2378398721 DATC_AlvCnt20Val 3;
BA_ "Version" SG_ 2378398721 DATC_AlvCnt20Val "21.01.02";
BA_ "Description" SG_ 2378398721 DATC_FragStrhUSMSta "This signal indicate frangrance strength USM state";
BA_ "GenSigSendType" SG_ 2378398721 DATC_FragStrhUSMSta 4;
BA_ "UserSigValidity" SG_ 2378398721 DATC_FragStrhUSMSta 7;
BA_REL_ "GenSigTimeoutTime" BU_SG_REL_ ATS SG_ 2378398721 DATC_FragStrhUSMSta 1500;
BA_ "Version" SG_ 2378398721 DATC_FragStrhUSMSta "21.01.02";
BA_ "Description" SG_ 2378398721 DATC_FragKindUSMSta "This signal indicate fragrance kind USM state.";
BA_ "GenSigSendType" SG_ 2378398721 DATC_FragKindUSMSta 4;
BA_ "UserSigValidity" SG_ 2378398721 DATC_FragKindUSMSta 7;
BA_REL_ "GenSigTimeoutTime" BU_SG_REL_ ATS SG_ 2378398721 DATC_FragKindUSMSta 1500;
BA_ "Version" SG_ 2378398721 DATC_FragKindUSMSta "21.01.02";
BA_ "Description" SG_ 2378398721 DATC_Frag1ExpireDisp "This signal indicate Expire Display of Fragrance No.1";
BA_ "GenSigSendType" SG_ 2378398721 DATC_Frag1ExpireDisp 4;
BA_ "UserSigValidity" SG_ 2378398721 DATC_Frag1ExpireDisp 7;
BA_REL_ "GenSigTimeoutTime" BU_SG_REL_ ATS SG_ 2378398721 DATC_Frag1ExpireDisp 1500;
BA_ "Version" SG_ 2378398721 DATC_Frag1ExpireDisp "21.01.02";
BA_ "Description" SG_ 2378398721 DATC_FragStrhDis "This signal indicate frangrance strength display value.";
BA_ "GenSigSendType" SG_ 2378398721 DATC_FragStrhDis 4;
BA_ "UserSigValidity" SG_ 2378398721 DATC_FragStrhDis 7;
BA_REL_ "GenSigTimeoutTime" BU_SG_REL_ ATS SG_ 2378398721 DATC_FragStrhDis 1500;
BA_ "Version" SG_ 2378398721 DATC_FragStrhDis "21.01.02";
BA_ "Description" SG_ 2378398721 DATC_FragKindDis "This signal indicate fragrance kind display value.";
BA_ "GenSigSendType" SG_ 2378398721 DATC_FragKindDis 4;
BA_ "UserSigValidity" SG_ 2378398721 DATC_FragKindDis 7;
BA_REL_ "GenSigTimeoutTime" BU_SG_REL_ ATS SG_ 2378398721 DATC_FragKindDis 1500;
BA_ "Version" SG_ 2378398721 DATC_FragKindDis "21.01.02";
BA_ "Description" SG_ 2378398721 DATC_Frag2ExpireDisp "This signal indicate Expire Display of Fragrance No.2";
BA_ "GenSigSendType" SG_ 2378398721 DATC_Frag2ExpireDisp 4;
BA_ "UserSigValidity" SG_ 2378398721 DATC_Frag2ExpireDisp 7;
BA_REL_ "GenSigTimeoutTime" BU_SG_REL_ ATS SG_ 2378398721 DATC_Frag2ExpireDisp 1500;
BA_ "Version" SG_ 2378398721 DATC_Frag2ExpireDisp "21.01.02";
BA_ "Description" SG_ 2378398721 DATC_VitalityFragranceSta "This signal indicate USM setting state of Fragrance for Vatality Mood.";
BA_ "GenSigSendType" SG_ 2378398721 DATC_VitalityFragranceSta 4;
BA_ "UserSigValidity" SG_ 2378398721 DATC_VitalityFragranceSta 3;
BA_ "Version" SG_ 2378398721 DATC_VitalityFragranceSta "21.01.02";
BA_ "Description" SG_ 2378398721 DATC_DelightFragranceSta "This signal indicate USM setting state of Fragrance for Delight Mood.";
BA_ "GenSigSendType" SG_ 2378398721 DATC_DelightFragranceSta 4;
BA_ "UserSigValidity" SG_ 2378398721 DATC_DelightFragranceSta 3;
BA_ "Version" SG_ 2378398721 DATC_DelightFragranceSta "21.01.02";
BA_ "Description" SG_ 2378398721 DATC_CareFragranceSta "This signal indicate USM setting state of Fragrance for Care Mood.";
BA_ "GenSigSendType" SG_ 2378398721 DATC_CareFragranceSta 4;
BA_ "UserSigValidity" SG_ 2378398721 DATC_CareFragranceSta 3;
BA_ "Version" SG_ 2378398721 DATC_CareFragranceSta "21.01.02";
BA_ "Description" SG_ 2378398721 DATC_ComfortFragranceSta "This signal indicate USM setting state of Fragrance for Comfort Mood.";
BA_ "GenSigSendType" SG_ 2378398721 DATC_ComfortFragranceSta 4;
BA_ "UserSigValidity" SG_ 2378398721 DATC_ComfortFragranceSta 3;
BA_ "Version" SG_ 2378398721 DATC_ComfortFragranceSta "21.01.02";
BA_ "Description" SG_ 2378398721 DATC_Frag1Inform "This signal indicate Fragrance 1 information.";
BA_ "GenSigSendType" SG_ 2378398721 DATC_Frag1Inform 4;
BA_ "UserSigValidity" SG_ 2378398721 DATC_Frag1Inform 7;
BA_REL_ "GenSigTimeoutTime" BU_SG_REL_ ATS SG_ 2378398721 DATC_Frag1Inform 1500;
BA_ "Version" SG_ 2378398721 DATC_Frag1Inform "21.01.02";
BA_ "Description" SG_ 2378398721 DATC_Frag1RemainDisp "This signal indicate Remain Display of Fragrance No.1";
BA_ "GenSigSendType" SG_ 2378398721 DATC_Frag1RemainDisp 4;
BA_ "UserSigValidity" SG_ 2378398721 DATC_Frag1RemainDisp 7;
BA_REL_ "GenSigTimeoutTime" BU_SG_REL_ ATS SG_ 2378398721 DATC_Frag1RemainDisp 1500;
BA_ "Version" SG_ 2378398721 DATC_Frag1RemainDisp "21.01.02";
BA_ "Description" SG_ 2378398721 DATC_Frag2Inform "This signal indicate Fragrance 2 Information.";
BA_ "GenSigSendType" SG_ 2378398721 DATC_Frag2Inform 4;
BA_ "UserSigValidity" SG_ 2378398721 DATC_Frag2Inform 7;
BA_REL_ "GenSigTimeoutTime" BU_SG_REL_ ATS SG_ 2378398721 DATC_Frag2Inform 1500;
BA_ "Version" SG_ 2378398721 DATC_Frag2Inform "21.01.02";
BA_ "Description" SG_ 2378398721 DATC_Frag2RemainDisp "This signal indicate Remains Display of Fragrance No.2";
BA_ "GenSigSendType" SG_ 2378398721 DATC_Frag2RemainDisp 4;
BA_ "UserSigValidity" SG_ 2378398721 DATC_Frag2RemainDisp 7;
BA_REL_ "GenSigTimeoutTime" BU_SG_REL_ ATS SG_ 2378398721 DATC_Frag2RemainDisp 1500;
BA_ "Version" SG_ 2378398721 DATC_Frag2RemainDisp "21.01.02";
BA_ "GenMsgSendType" BO_ 346 0;
BA_ "Description" SG_ 346 DPSS_WalkInSwitchSts "DPSS_WalkInSwitchStatus";
BA_ "GenSigSendType" SG_ 346 DPSS_WalkInSwitchSts 4;
BA_ "UserSigValidity" SG_ 346 DPSS_WalkInSwitchSts 3;
BA_ "NetworkRequest" SG_ 346 DPSS_WalkInSwitchSts 0;
BA_ "NetworkRequestHoldingTime" SG_ 346 DPSS_WalkInSwitchSts 5000;
BA_ "Version" SG_ 346 DPSS_WalkInSwitchSts "19.11.06";
BA_ "GenMsgSendType" BO_ 345 0;
BA_ "Description" SG_ 345 DSAU_LumbarUpDis "DSAU_LumbarUppperDisplay";
BA_ "GenSigSendType" SG_ 345 DSAU_LumbarUpDis 4;
BA_ "UserSigValidity" SG_ 345 DSAU_LumbarUpDis 3;
BA_REL_ "GenSigTimeoutTime" BU_SG_REL_ CGW_CCU SG_ 345 DSAU_LumbarUpDis 1500;
BA_ "NetworkRequest" SG_ 345 DSAU_LumbarUpDis 0;
BA_ "NetworkRequestHoldingTime" SG_ 345 DSAU_LumbarUpDis 5000;
BA_ "Version" SG_ 345 DSAU_LumbarUpDis "21.08.04";
BA_ "Description" SG_ 345 DSAU_LumbarMidDis "DSAU_LumbarMidDisplay";
BA_ "GenSigSendType" SG_ 345 DSAU_LumbarMidDis 4;
BA_ "UserSigValidity" SG_ 345 DSAU_LumbarMidDis 3;
BA_REL_ "GenSigTimeoutTime" BU_SG_REL_ CGW_CCU SG_ 345 DSAU_LumbarMidDis 1500;
BA_ "NetworkRequest" SG_ 345 DSAU_LumbarMidDis 0;
BA_ "NetworkRequestHoldingTime" SG_ 345 DSAU_LumbarMidDis 5000;
BA_ "Version" SG_ 345 DSAU_LumbarMidDis "21.08.04";
BA_ "Description" SG_ 345 DSAU_LumbarLowDis "DSAU_LumbarLowerDisplay";
BA_ "GenSigSendType" SG_ 345 DSAU_LumbarLowDis 4;
BA_ "UserSigValidity" SG_ 345 DSAU_LumbarLowDis 3;
BA_REL_ "GenSigTimeoutTime" BU_SG_REL_ CGW_CCU SG_ 345 DSAU_LumbarLowDis 1500;
BA_ "NetworkRequest" SG_ 345 DSAU_LumbarLowDis 0;
BA_ "NetworkRequestHoldingTime" SG_ 345 DSAU_LumbarLowDis 5000;
BA_ "Version" SG_ 345 DSAU_LumbarLowDis "21.08.04";
BA_ "Description" SG_ 345 DSAU_LumbarDefDis "DSAU_LumbarDeflationDisplay";
BA_ "GenSigSendType" SG_ 345 DSAU_LumbarDefDis 4;
BA_ "UserSigValidity" SG_ 345 DSAU_LumbarDefDis 3;
BA_REL_ "GenSigTimeoutTime" BU_SG_REL_ CGW_CCU SG_ 345 DSAU_LumbarDefDis 1500;
BA_ "NetworkRequest" SG_ 345 DSAU_LumbarDefDis 0;
BA_ "NetworkRequestHoldingTime" SG_ 345 DSAU_LumbarDefDis 5000;
BA_ "Version" SG_ 345 DSAU_LumbarDefDis "21.08.04";
BA_ "GenMsgSendType" BO_ 348 0;
BA_ "Description" SG_ 348 DSAU_BolsterInfDis "DSAU_BolsterInflationDisplay";
BA_ "GenSigSendType" SG_ 348 DSAU_BolsterInfDis 4;
BA_ "UserSigValidity" SG_ 348 DSAU_BolsterInfDis 3;
BA_REL_ "GenSigTimeoutTime" BU_SG_REL_ CGW_CCU SG_ 348 DSAU_BolsterInfDis 1500;
BA_ "NetworkRequest" SG_ 348 DSAU_BolsterInfDis 0;
BA_ "NetworkRequestHoldingTime" SG_ 348 DSAU_BolsterInfDis 5000;
BA_ "Version" SG_ 348 DSAU_BolsterInfDis "19.11.06";
BA_ "Description" SG_ 348 DSAU_BolsterDefDis "DSAU_BolsterDeflationDisplay";
BA_ "GenSigSendType" SG_ 348 DSAU_BolsterDefDis 4;
BA_ "UserSigValidity" SG_ 348 DSAU_BolsterDefDis 3;
BA_REL_ "GenSigTimeoutTime" BU_SG_REL_ CGW_CCU SG_ 348 DSAU_BolsterDefDis 1500;
BA_ "NetworkRequest" SG_ 348 DSAU_BolsterDefDis 0;
BA_ "NetworkRequestHoldingTime" SG_ 348 DSAU_BolsterDefDis 5000;
BA_ "Version" SG_ 348 DSAU_BolsterDefDis "19.11.06";
BA_ "GenMsgSendType" BO_ 349 0;
BA_ "Description" SG_ 349 DSAU_CushInfDis "DSAU_CushionInflationDisplay";
BA_ "GenSigSendType" SG_ 349 DSAU_CushInfDis 4;
BA_ "UserSigValidity" SG_ 349 DSAU_CushInfDis 3;
BA_REL_ "GenSigTimeoutTime" BU_SG_REL_ CGW_CCU SG_ 349 DSAU_CushInfDis 1500;
BA_ "NetworkRequest" SG_ 349 DSAU_CushInfDis 0;
BA_ "NetworkRequestHoldingTime" SG_ 349 DSAU_CushInfDis 5000;
BA_ "Version" SG_ 349 DSAU_CushInfDis "19.11.06";
BA_ "Description" SG_ 349 DSAU_CushDefDis "DSAU_CushionDeflationDisplay";
BA_ "GenSigSendType" SG_ 349 DSAU_CushDefDis 4;
BA_ "UserSigValidity" SG_ 349 DSAU_CushDefDis 3;
BA_REL_ "GenSigTimeoutTime" BU_SG_REL_ CGW_CCU SG_ 349 DSAU_CushDefDis 1500;
BA_ "NetworkRequest" SG_ 349 DSAU_CushDefDis 0;
BA_ "NetworkRequestHoldingTime" SG_ 349 DSAU_CushDefDis 5000;
BA_ "Version" SG_ 349 DSAU_CushDefDis "19.11.06";
BA_ "GenMsgSendType" BO_ 350 0;
BA_ "Description" SG_ 350 DSAU_AirSptTimeRValueSet "Air Support Time(Massage Time) USM R Value";
BA_ "GenSigSendType" SG_ 350 DSAU_AirSptTimeRValueSet 4;
BA_ "UserSigValidity" SG_ 350 DSAU_AirSptTimeRValueSet 3;
BA_REL_ "GenSigTimeoutTime" BU_SG_REL_ CGW_CCU SG_ 350 DSAU_AirSptTimeRValueSet 1500;
BA_ "NetworkRequest" SG_ 350 DSAU_AirSptTimeRValueSet 0;
BA_ "NetworkRequestHoldingTime" SG_ 350 DSAU_AirSptTimeRValueSet 5000;
BA_ "Version" SG_ 350 DSAU_AirSptTimeRValueSet "19.11.06";
BA_ "Description" SG_ 350 DSAU_DrvPostureAssistRValueSet "Drive Seat Posture Assist Function USM R Value";
BA_ "GenSigSendType" SG_ 350 DSAU_DrvPostureAssistRValueSet 4;
BA_ "UserSigValidity" SG_ 350 DSAU_DrvPostureAssistRValueSet 3;
BA_ "NetworkRequest" SG_ 350 DSAU_DrvPostureAssistRValueSet 0;
BA_ "NetworkRequestHoldingTime" SG_ 350 DSAU_DrvPostureAssistRValueSet 5000;
BA_ "Version" SG_ 350 DSAU_DrvPostureAssistRValueSet "19.11.06";
BA_ "Description" SG_ 350 DSAU_DrvSmtAirSptRValueSet "Seat Smart Air Support Function USM R Value";
BA_ "GenSigSendType" SG_ 350 DSAU_DrvSmtAirSptRValueSet 4;
BA_ "UserSigValidity" SG_ 350 DSAU_DrvSmtAirSptRValueSet 3;
BA_REL_ "GenSigTimeoutTime" BU_SG_REL_ CGW_CCU SG_ 350 DSAU_DrvSmtAirSptRValueSet 1500;
BA_ "NetworkRequest" SG_ 350 DSAU_DrvSmtAirSptRValueSet 0;
BA_ "NetworkRequestHoldingTime" SG_ 350 DSAU_DrvSmtAirSptRValueSet 5000;
BA_ "Version" SG_ 350 DSAU_DrvSmtAirSptRValueSet "19.12.00";
BA_ "Description" SG_ 350 DSAU_DrvSmtSptRValueSet "Seat Smart Support Function USM R Value";
BA_ "GenSigSendType" SG_ 350 DSAU_DrvSmtSptRValueSet 4;
BA_ "UserSigValidity" SG_ 350 DSAU_DrvSmtSptRValueSet 3;
BA_ "NetworkRequest" SG_ 350 DSAU_DrvSmtSptRValueSet 0;
BA_ "NetworkRequestHoldingTime" SG_ 350 DSAU_DrvSmtSptRValueSet 5000;
BA_ "Version" SG_ 350 DSAU_DrvSmtSptRValueSet "19.12.01";
BA_ "Description" SG_ 350 DSAU_CushSoftRValueSet "Cushion Soft R Value";
BA_ "GenSigSendType" SG_ 350 DSAU_CushSoftRValueSet 4;
BA_ "UserSigValidity" SG_ 350 DSAU_CushSoftRValueSet 3;
BA_REL_ "GenSigTimeoutTime" BU_SG_REL_ CGW_CCU SG_ 350 DSAU_CushSoftRValueSet 1500;
BA_ "NetworkRequest" SG_ 350 DSAU_CushSoftRValueSet 0;
BA_ "NetworkRequestHoldingTime" SG_ 350 DSAU_CushSoftRValueSet 5000;
BA_ "Version" SG_ 350 DSAU_CushSoftRValueSet "20.04.02";
BA_ "Description" SG_ 350 DSAU_BackSoftRValueSet "Back Soft USM R Value";
BA_ "GenSigSendType" SG_ 350 DSAU_BackSoftRValueSet 4;
BA_ "UserSigValidity" SG_ 350 DSAU_BackSoftRValueSet 3;
BA_REL_ "GenSigTimeoutTime" BU_SG_REL_ CGW_CCU SG_ 350 DSAU_BackSoftRValueSet 1500;
BA_ "NetworkRequest" SG_ 350 DSAU_BackSoftRValueSet 0;
BA_ "NetworkRequestHoldingTime" SG_ 350 DSAU_BackSoftRValueSet 5000;
BA_ "Version" SG_ 350 DSAU_BackSoftRValueSet "20.04.02";
BA_ "Description" SG_ 350 DSAU_AirSptModeRValueSet "Air Support Mode(Massage Mode) USM R Value";
BA_ "GenSigSendType" SG_ 350 DSAU_AirSptModeRValueSet 4;
BA_ "UserSigValidity" SG_ 350 DSAU_AirSptModeRValueSet 3;
BA_REL_ "GenSigTimeoutTime" BU_SG_REL_ CGW_CCU SG_ 350 DSAU_AirSptModeRValueSet 1500;
BA_ "NetworkRequest" SG_ 350 DSAU_AirSptModeRValueSet 0;
BA_ "NetworkRequestHoldingTime" SG_ 350 DSAU_AirSptModeRValueSet 5000;
BA_ "Version" SG_ 350 DSAU_AirSptModeRValueSet "19.11.06";
BA_ "Description" SG_ 350 DSAU_MsgModeSts "Air Support Mode Function Operating Display";
BA_ "GenSigSendType" SG_ 350 DSAU_MsgModeSts 4;
BA_ "UserSigValidity" SG_ 350 DSAU_MsgModeSts 3;
BA_REL_ "GenSigTimeoutTime" BU_SG_REL_ CGW_CCU SG_ 350 DSAU_MsgModeSts 1500;
BA_ "NetworkRequest" SG_ 350 DSAU_MsgModeSts 0;
BA_ "NetworkRequestHoldingTime" SG_ 350 DSAU_MsgModeSts 5000;
BA_ "Version" SG_ 350 DSAU_MsgModeSts "20.04.02";
BA_ "Description" SG_ 350 DSAU_MsgModeStrength "Air Support intensity regulation(Massage Strenth)";
BA_ "GenSigSendType" SG_ 350 DSAU_MsgModeStrength 4;
BA_ "UserSigValidity" SG_ 350 DSAU_MsgModeStrength 3;
BA_REL_ "GenSigTimeoutTime" BU_SG_REL_ CGW_CCU SG_ 350 DSAU_MsgModeStrength 1500;
BA_ "NetworkRequest" SG_ 350 DSAU_MsgModeStrength 0;
BA_ "NetworkRequestHoldingTime" SG_ 350 DSAU_MsgModeStrength 5000;
BA_ "Version" SG_ 350 DSAU_MsgModeStrength "19.12.01";
BA_ "Description" SG_ 350 DSAU_MoodTrpyRValueSet "Drive Seat Mood Therapy R Value";
BA_ "GenSigSendType" SG_ 350 DSAU_MoodTrpyRValueSet 4;
BA_ "UserSigValidity" SG_ 350 DSAU_MoodTrpyRValueSet 3;
BA_REL_ "GenSigTimeoutTime" BU_SG_REL_ CGW_CCU SG_ 350 DSAU_MoodTrpyRValueSet 1500;
BA_ "NetworkRequest" SG_ 350 DSAU_MoodTrpyRValueSet 0;
BA_ "NetworkRequestHoldingTime" SG_ 350 DSAU_MoodTrpyRValueSet 5000;
BA_ "Version" SG_ 350 DSAU_MoodTrpyRValueSet "20.07.03";
BA_ "Description" SG_ 350 DSAU_MoodTrpyCareSta "Drive Seat Mood Therapy Care Mode R Value";
BA_ "GenSigSendType" SG_ 350 DSAU_MoodTrpyCareSta 4;
BA_ "UserSigValidity" SG_ 350 DSAU_MoodTrpyCareSta 3;
BA_REL_ "GenSigTimeoutTime" BU_SG_REL_ CGW_CCU SG_ 350 DSAU_MoodTrpyCareSta 1500;
BA_ "NetworkRequest" SG_ 350 DSAU_MoodTrpyCareSta 0;
BA_ "NetworkRequestHoldingTime" SG_ 350 DSAU_MoodTrpyCareSta 5000;
BA_ "Version" SG_ 350 DSAU_MoodTrpyCareSta "20.07.12";
BA_ "Description" SG_ 350 DSAU_MoodTrpyComfSta "Drive Seat Mood Therapy Comfort Mode R Value";
BA_ "GenSigSendType" SG_ 350 DSAU_MoodTrpyComfSta 4;
BA_ "UserSigValidity" SG_ 350 DSAU_MoodTrpyComfSta 3;
BA_REL_ "GenSigTimeoutTime" BU_SG_REL_ CGW_CCU SG_ 350 DSAU_MoodTrpyComfSta 1500;
BA_ "NetworkRequest" SG_ 350 DSAU_MoodTrpyComfSta 0;
BA_ "NetworkRequestHoldingTime" SG_ 350 DSAU_MoodTrpyComfSta 5000;
BA_ "Version" SG_ 350 DSAU_MoodTrpyComfSta "20.07.12";
BA_ "Description" SG_ 350 DASU_AirSptStrRValueSet "Air Support Strenth(Massage Strenth) USM R Value";
BA_ "GenSigSendType" SG_ 350 DASU_AirSptStrRValueSet 4;
BA_ "UserSigValidity" SG_ 350 DASU_AirSptStrRValueSet 3;
BA_REL_ "GenSigTimeoutTime" BU_SG_REL_ CGW_CCU SG_ 350 DASU_AirSptStrRValueSet 1500;
BA_ "NetworkRequest" SG_ 350 DASU_AirSptStrRValueSet 0;
BA_ "NetworkRequestHoldingTime" SG_ 350 DASU_AirSptStrRValueSet 5000;
BA_ "Version" SG_ 350 DASU_AirSptStrRValueSet "20.07.11";
BA_ "GenMsgSendType" BO_ 2277634049 0;
BA_ "GenMsgCycleTime" BO_ 2277634049 150;
BA_ "GenMsgCycleTimeFast" BO_ 2277634049 0;
BA_ "GenMsgNrOfRepetition" BO_ 2277634049 0;
BA_ "VFrameFormat" BO_ 2277634049 1;
BA_ "Description" SG_ 2277634049 EPB_Crc1Val "The data area for CRC calculation is based on the data length (DLC) of the message DB.

The CRC shall be calculated over the entire data block (excluding the CRC bytes) including the user data, alive counter and Data ID

 

- CRC Polynomial (0x1021) , Initial Value : 0xFFFF, XOR value : 0x0000, Data ID : Message ID + 0xF800 

- The initial value is for CRC calculation and the message should be sent with the calculated result value. 

- The mathematical expression to 16 bit CRC polynomial is given here. G(x) = x16 + x12 + x5 + 1";
BA_ "GenSigStartValue" SG_ 2277634049 EPB_Crc1Val 65535;
BA_ "UserSigValidity" SG_ 2277634049 EPB_Crc1Val 3;
BA_ "RoutingFactor" SG_ 2277634049 EPB_Crc1Val 3;
BA_ "Version" SG_ 2277634049 EPB_Crc1Val "18.11.08";
BA_ "Description" SG_ 2277634049 EPB_AlvCnt1Val "For the first transmission request for a data element the counter shall be initialized with 0 and shall be incremented by 1 for every subsequent send request. 

When the counter reaches the maximum value(0xFF), then it shall restart with 0 for the next send request";
BA_ "UserSigValidity" SG_ 2277634049 EPB_AlvCnt1Val 3;
BA_ "RoutingFactor" SG_ 2277634049 EPB_AlvCnt1Val 3;
BA_ "Version" SG_ 2277634049 EPB_AlvCnt1Val "18.11.08";
BA_ "Description" SG_ 2277634049 EPB_LmpStaDis "This signal indicates status lamp request from EPB to lamp control unit.

- If a lamp control unit can not get this signal via CAN due to any errors, the last lamp state before the error should be maintained.

- When EPB apply switch is pressed in the IG-key off sate, the parking brake lamp should be on for 15 seconds and off. In this case, the cluster shall have CAN wake-up capability.



EPB_LmpStaDis(0H) - Parking brake lamp status (Off)

EPB_LmpStaDis(1H) - Parking brake lamp status (On)

EPB_LmpStaDis(2H) - Parking brake lamp status (Blinking at 1Hz)";
BA_ "UserSigValidity" SG_ 2277634049 EPB_LmpStaDis 3;
BA_REL_ "GenSigTimeoutTime" BU_SG_REL_ APSU SG_ 2277634049 EPB_LmpStaDis 1500;
BA_REL_ "GenSigTimeoutTime" BU_SG_REL_ RLHV SG_ 2277634049 EPB_LmpStaDis 1500;
BA_REL_ "GenSigTimeoutTime" BU_SG_REL_ RRHV SG_ 2277634049 EPB_LmpStaDis 1500;
BA_REL_ "GenSigTimeoutTime" BU_SG_REL_ DPSU SG_ 2277634049 EPB_LmpStaDis 1500;
BA_REL_ "GenSigTimeoutTime" BU_SG_REL_ PFSU SG_ 2277634049 EPB_LmpStaDis 1500;
BA_REL_ "GenSigTimeoutTime" BU_SG_REL_ RRPSU SG_ 2277634049 EPB_LmpStaDis 1500;
BA_REL_ "GenSigTimeoutTime" BU_SG_REL_ RLPSU SG_ 2277634049 EPB_LmpStaDis 1500;
BA_ "RoutingFactor" SG_ 2277634049 EPB_LmpStaDis 3;
BA_ "Version" SG_ 2277634049 EPB_LmpStaDis "20.07.03";
BA_ "Description" SG_ 2277634049 EPB_FlrLmpStaDis "Information about the failure lamp request from EPB to lamp control unit.



EPB_F_LAMP(0H) - Yellow failure lamp status(Off)

EPB_F_LAMP(1H) - Yellow failure lamp status(On)

EPB_F_LAMP(2H) - Yellow failure lamp status(Blinking at 1 Hz)";
BA_ "UserSigValidity" SG_ 2277634049 EPB_FlrLmpStaDis 3;
BA_ "RoutingFactor" SG_ 2277634049 EPB_FlrLmpStaDis 3;
BA_ "Version" SG_ 2277634049 EPB_FlrLmpStaDis "17.12.00";
BA_ "Description" SG_ 2277634049 EPB_OutDataDis "An EPB can show its information message to driver on a cluster or a display module with this signal. ¡Ø 0x4 is for China";
BA_ "UserSigValidity" SG_ 2277634049 EPB_OutDataDis 3;
BA_ "RoutingFactor" SG_ 2277634049 EPB_OutDataDis 3;
BA_ "Version" SG_ 2277634049 EPB_OutDataDis "19.11.02";
BA_ "Description" SG_ 2277634049 EPB_AlrmReq "This signal indicates that an EPB requests cluster or tone controller to ring the alarm according to the status of an EPB.



Conversion [Condition]

0H : Normal operation

1H : EPB_CLU = 2 or 3

(send signals three time in a row & 1st signal should be sent at the same time as corresponding EPB_CLU 1st Signal)

2H : Dynamic braking[ECD, RWU] (send signal continuously)

3H : Reserved";
BA_ "UserSigValidity" SG_ 2277634049 EPB_AlrmReq 3;
BA_ "RoutingFactor" SG_ 2277634049 EPB_AlrmReq 3;
BA_ "Version" SG_ 2277634049 EPB_AlrmReq "17.12.00";
BA_ "Description" SG_ 2277634049 EPB_SwPosSta "Information about the EPB control switch state";
BA_ "UserSigValidity" SG_ 2277634049 EPB_SwPosSta 3;
BA_ "RoutingFactor" SG_ 2277634049 EPB_SwPosSta 3;
BA_ "Version" SG_ 2277634049 EPB_SwPosSta "17.12.00";
BA_ "Description" SG_ 2277634049 EPB_RrBrkLtActvReq "If an EPB acts braking and the vehicle speed is higher than pre-defined condition then rear brake lamp shall be turned on. This signal requests ESC or brake lamp controller to turn on rear brake lamp.";
BA_ "UserSigValidity" SG_ 2277634049 EPB_RrBrkLtActvReq 3;
BA_ "RoutingFactor" SG_ 2277634049 EPB_RrBrkLtActvReq 3;
BA_ "Version" SG_ 2277634049 EPB_RrBrkLtActvReq "17.12.00";
BA_ "Description" SG_ 2277634049 EPB_FrcErrSta "Detail descriptions of error status of EPB force if EPB_FrcErrSta = 00H";
BA_ "UserSigValidity" SG_ 2277634049 EPB_FrcErrSta 3;
BA_ "RoutingFactor" SG_ 2277634049 EPB_FrcErrSta 3;
BA_ "Version" SG_ 2277634049 EPB_FrcErrSta "17.12.00";
BA_ "Description" SG_ 2277634049 EPB_DynmBrkFrcReqSigSta "This signal indicates the validity of EPB_DynmBrkFrcReqSigSta (EPB request for ESP to activate Dynamic Brake Function) signal.";
BA_ "GenSigStartValue" SG_ 2277634049 EPB_DynmBrkFrcReqSigSta 1;
BA_ "UserSigValidity" SG_ 2277634049 EPB_DynmBrkFrcReqSigSta 3;
BA_ "RoutingFactor" SG_ 2277634049 EPB_DynmBrkFrcReqSigSta 3;
BA_ "Version" SG_ 2277634049 EPB_DynmBrkFrcReqSigSta "17.12.00";
BA_ "Description" SG_ 2277634049 EPB_FrcSta "Information about the force status of the EPB";
BA_ "UserSigValidity" SG_ 2277634049 EPB_FrcSta 3;
BA_ "RoutingFactor" SG_ 2277634049 EPB_FrcSta 3;
BA_ "Version" SG_ 2277634049 EPB_FrcSta "17.12.00";
BA_ "Description" SG_ 2277634049 EPB_FlSta "Information about availability of EPB. If this bit is set (EPB is not available), EPB motor control is not possible, e.g. by external AVH request.";
BA_ "GenSigStartValue" SG_ 2277634049 EPB_FlSta 2;
BA_ "UserSigValidity" SG_ 2277634049 EPB_FlSta 3;
BA_ "RoutingFactor" SG_ 2277634049 EPB_FlSta 3;
BA_ "Version" SG_ 2277634049 EPB_FlSta "17.12.00";
BA_ "Description" SG_ 2277634049 EPB_EscReqAckSta "Acknowledge signal for ESC request (e.g. AVH).



ESC sends request to release (1) or clamping (2) via signal REQ_EPB_ACT. The EPB acknowledges this request with EPB_EscReqAckSta = 1 within the time tESP_REQ_OK (value tbd) and performs according to the requested action. If signal EPB_EscReqAckSta remains = 0 for longer than tESP_REQ_OK, the requested action will be discarded.";
BA_ "UserSigValidity" SG_ 2277634049 EPB_EscReqAckSta 3;
BA_ "RoutingFactor" SG_ 2277634049 EPB_EscReqAckSta 3;
BA_ "Version" SG_ 2277634049 EPB_EscReqAckSta "17.12.00";
BA_ "Description" SG_ 2277634049 EPB_DynmBrkFrcReq "EPB dynamic Braking Request";
BA_ "UserSigValidity" SG_ 2277634049 EPB_DynmBrkFrcReq 3;
BA_ "RoutingFactor" SG_ 2277634049 EPB_DynmBrkFrcReq 3;
BA_ "Version" SG_ 2277634049 EPB_DynmBrkFrcReq "17.12.00";
BA_ "Description" SG_ 2277634049 EPB_EmerModReq "This signal is for requesting EPB emergency mode to eEPB ECU.

- Emergency EPB Mode : Turning On the Relay in order to change into Emgergency mode 

- Normal EPB Mode : Turning Off the Relay in order to change into Normal mode";
BA_ "UserSigValidity" SG_ 2277634049 EPB_EmerModReq 3;
BA_ "RoutingFactor" SG_ 2277634049 EPB_EmerModReq 3;
BA_ "Version" SG_ 2277634049 EPB_EmerModReq "20.04.06";
BA_ "Description" SG_ 2277634049 EPB_EpbSta4VcuReq "This signal indicates the status of EPB parking actuation opearated by VCU's request.";
BA_ "UserSigValidity" SG_ 2277634049 EPB_EpbSta4VcuReq 3;
BA_ "RoutingFactor" SG_ 2277634049 EPB_EpbSta4VcuReq 3;
BA_ "Version" SG_ 2277634049 EPB_EpbSta4VcuReq "20.07.01";
BA_ "GenMsgSendType" BO_ 2277634050 0;
BA_ "GenMsgCycleTime" BO_ 2277634050 150;
BA_ "GenMsgCycleTimeFast" BO_ 2277634050 0;
BA_ "GenMsgNrOfRepetition" BO_ 2277634050 0;
BA_ "VFrameFormat" BO_ 2277634050 1;
BA_ "Description" SG_ 2277634050 EPB_ActlFrcVal "Actual braking force measured by EPB force sensor.";
BA_ "GenSigStartValue" SG_ 2277634050 EPB_ActlFrcVal 1000;
BA_ "UserSigValidity" SG_ 2277634050 EPB_ActlFrcVal 3;
BA_ "RoutingFactor" SG_ 2277634050 EPB_ActlFrcVal 3;
BA_ "Version" SG_ 2277634050 EPB_ActlFrcVal "17.12.00";
BA_ "Description" SG_ 2277634050 EPB_DynmBrkFrcDclReq "Requested deceleration for DBF. The ESC must consider this value if EPB_DynmBrkFrcReq is equal to 1.";
BA_ "UserSigValidity" SG_ 2277634050 EPB_DynmBrkFrcDclReq 3;
BA_ "RoutingFactor" SG_ 2277634050 EPB_DynmBrkFrcDclReq 3;
BA_ "Version" SG_ 2277634050 EPB_DynmBrkFrcDclReq "17.12.00";
BA_ "GenMsgCycleTime" BO_ 1874 0;
BA_ "GenMsgCycleTimeFast" BO_ 1874 0;
BA_ "GenMsgNrOfRepetition" BO_ 1874 0;
BA_ "DiagRequest" BO_ 1874 1;
BA_ "GenMsgILSupport" BO_ 1874 0;
BA_ "TpMessage" BO_ 1874 1;
BA_ "TpTxIndex" BO_ 1874 121;
BA_ "Description" SG_ 1874 GST_DLBCU_Byte0 "TP Index : 121";
BA_ "UsrSigPurpose" SG_ 1874 GST_DLBCU_Byte0 3;
BA_ "UserSigValidity" SG_ 1874 GST_DLBCU_Byte0 0;
BA_REL_ "GenSigTimeoutTime" BU_SG_REL_ DLBCU SG_ 1874 GST_DLBCU_Byte0 0;
BA_ "NetworkRequest" SG_ 1874 GST_DLBCU_Byte0 0;
BA_ "NetworkRequestHoldingTime" SG_ 1874 GST_DLBCU_Byte0 5000;
BA_ "Version" SG_ 1874 GST_DLBCU_Byte0 "21.02.04";
BA_ "Description" SG_ 1874 GST_DLBCU_Byte2 "TP Index : 121";
BA_ "UsrSigPurpose" SG_ 1874 GST_DLBCU_Byte2 3;
BA_ "UserSigValidity" SG_ 1874 GST_DLBCU_Byte2 0;
BA_REL_ "GenSigTimeoutTime" BU_SG_REL_ DLBCU SG_ 1874 GST_DLBCU_Byte2 0;
BA_ "NetworkRequest" SG_ 1874 GST_DLBCU_Byte2 0;
BA_ "NetworkRequestHoldingTime" SG_ 1874 GST_DLBCU_Byte2 5000;
BA_ "Version" SG_ 1874 GST_DLBCU_Byte2 "21.02.04";
BA_ "Description" SG_ 1874 GST_DLBCU_Byte3 "TP Index : 121";
BA_ "UsrSigPurpose" SG_ 1874 GST_DLBCU_Byte3 3;
BA_ "UserSigValidity" SG_ 1874 GST_DLBCU_Byte3 0;
BA_REL_ "GenSigTimeoutTime" BU_SG_REL_ DLBCU SG_ 1874 GST_DLBCU_Byte3 0;
BA_ "NetworkRequest" SG_ 1874 GST_DLBCU_Byte3 0;
BA_ "NetworkRequestHoldingTime" SG_ 1874 GST_DLBCU_Byte3 5000;
BA_ "Version" SG_ 1874 GST_DLBCU_Byte3 "21.02.04";
BA_ "Description" SG_ 1874 GST_DLBCU_Byte4 "TP Index : 121";
BA_ "UsrSigPurpose" SG_ 1874 GST_DLBCU_Byte4 3;
BA_ "UserSigValidity" SG_ 1874 GST_DLBCU_Byte4 0;
BA_REL_ "GenSigTimeoutTime" BU_SG_REL_ DLBCU SG_ 1874 GST_DLBCU_Byte4 0;
BA_ "NetworkRequest" SG_ 1874 GST_DLBCU_Byte4 0;
BA_ "NetworkRequestHoldingTime" SG_ 1874 GST_DLBCU_Byte4 5000;
BA_ "Version" SG_ 1874 GST_DLBCU_Byte4 "21.02.04";
BA_ "Description" SG_ 1874 GST_DLBCU_Byte5 "TP Index : 121";
BA_ "UsrSigPurpose" SG_ 1874 GST_DLBCU_Byte5 3;
BA_ "UserSigValidity" SG_ 1874 GST_DLBCU_Byte5 0;
BA_REL_ "GenSigTimeoutTime" BU_SG_REL_ DLBCU SG_ 1874 GST_DLBCU_Byte5 0;
BA_ "NetworkRequest" SG_ 1874 GST_DLBCU_Byte5 0;
BA_ "NetworkRequestHoldingTime" SG_ 1874 GST_DLBCU_Byte5 5000;
BA_ "Version" SG_ 1874 GST_DLBCU_Byte5 "21.02.04";
BA_ "Description" SG_ 1874 GST_DLBCU_Byte6 "TP Index : 121";
BA_ "UsrSigPurpose" SG_ 1874 GST_DLBCU_Byte6 3;
BA_ "UserSigValidity" SG_ 1874 GST_DLBCU_Byte6 0;
BA_REL_ "GenSigTimeoutTime" BU_SG_REL_ DLBCU SG_ 1874 GST_DLBCU_Byte6 0;
BA_ "NetworkRequest" SG_ 1874 GST_DLBCU_Byte6 0;
BA_ "NetworkRequestHoldingTime" SG_ 1874 GST_DLBCU_Byte6 5000;
BA_ "Version" SG_ 1874 GST_DLBCU_Byte6 "21.02.04";
BA_ "Description" SG_ 1874 GST_DLBCU_Byte7 "TP Index : 121";
BA_ "UsrSigPurpose" SG_ 1874 GST_DLBCU_Byte7 3;
BA_ "UserSigValidity" SG_ 1874 GST_DLBCU_Byte7 0;
BA_REL_ "GenSigTimeoutTime" BU_SG_REL_ DLBCU SG_ 1874 GST_DLBCU_Byte7 0;
BA_ "NetworkRequest" SG_ 1874 GST_DLBCU_Byte7 0;
BA_ "NetworkRequestHoldingTime" SG_ 1874 GST_DLBCU_Byte7 5000;
BA_ "Version" SG_ 1874 GST_DLBCU_Byte7 "21.02.04";
BA_ "Description" SG_ 1874 GST_DLBCU_Byte1 "TP Index : 121";
BA_ "UsrSigPurpose" SG_ 1874 GST_DLBCU_Byte1 3;
BA_ "UserSigValidity" SG_ 1874 GST_DLBCU_Byte1 0;
BA_REL_ "GenSigTimeoutTime" BU_SG_REL_ DLBCU SG_ 1874 GST_DLBCU_Byte1 0;
BA_ "NetworkRequest" SG_ 1874 GST_DLBCU_Byte1 0;
BA_ "NetworkRequestHoldingTime" SG_ 1874 GST_DLBCU_Byte1 5000;
BA_ "Version" SG_ 1874 GST_DLBCU_Byte1 "21.02.04";
BA_ "GenMsgCycleTime" BO_ 1873 0;
BA_ "GenMsgCycleTimeFast" BO_ 1873 0;
BA_ "GenMsgNrOfRepetition" BO_ 1873 0;
BA_ "DiagRequest" BO_ 1873 1;
BA_ "GenMsgILSupport" BO_ 1873 0;
BA_ "TpMessage" BO_ 1873 1;
BA_ "TpTxIndex" BO_ 1873 122;
BA_ "Description" SG_ 1873 GST_DPSS_Byte0 "TP Index : 122";
BA_ "UsrSigPurpose" SG_ 1873 GST_DPSS_Byte0 3;
BA_ "UserSigValidity" SG_ 1873 GST_DPSS_Byte0 0;
BA_REL_ "GenSigTimeoutTime" BU_SG_REL_ DPSU SG_ 1873 GST_DPSS_Byte0 0;
BA_ "NetworkRequest" SG_ 1873 GST_DPSS_Byte0 0;
BA_ "NetworkRequestHoldingTime" SG_ 1873 GST_DPSS_Byte0 5000;
BA_ "Version" SG_ 1873 GST_DPSS_Byte0 "21.02.04";
BA_ "Description" SG_ 1873 GST_DPSS_Byte2 "TP Index : 122";
BA_ "UsrSigPurpose" SG_ 1873 GST_DPSS_Byte2 3;
BA_ "UserSigValidity" SG_ 1873 GST_DPSS_Byte2 0;
BA_REL_ "GenSigTimeoutTime" BU_SG_REL_ DPSU SG_ 1873 GST_DPSS_Byte2 0;
BA_ "NetworkRequest" SG_ 1873 GST_DPSS_Byte2 0;
BA_ "NetworkRequestHoldingTime" SG_ 1873 GST_DPSS_Byte2 5000;
BA_ "Version" SG_ 1873 GST_DPSS_Byte2 "21.02.04";
BA_ "Description" SG_ 1873 GST_DPSS_Byte3 "TP Index : 122";
BA_ "UsrSigPurpose" SG_ 1873 GST_DPSS_Byte3 3;
BA_ "UserSigValidity" SG_ 1873 GST_DPSS_Byte3 0;
BA_REL_ "GenSigTimeoutTime" BU_SG_REL_ DPSU SG_ 1873 GST_DPSS_Byte3 0;
BA_ "NetworkRequest" SG_ 1873 GST_DPSS_Byte3 0;
BA_ "NetworkRequestHoldingTime" SG_ 1873 GST_DPSS_Byte3 5000;
BA_ "Version" SG_ 1873 GST_DPSS_Byte3 "21.02.04";
BA_ "Description" SG_ 1873 GST_DPSS_Byte4 "TP Index : 122";
BA_ "UsrSigPurpose" SG_ 1873 GST_DPSS_Byte4 3;
BA_ "UserSigValidity" SG_ 1873 GST_DPSS_Byte4 0;
BA_REL_ "GenSigTimeoutTime" BU_SG_REL_ DPSU SG_ 1873 GST_DPSS_Byte4 0;
BA_ "NetworkRequest" SG_ 1873 GST_DPSS_Byte4 0;
BA_ "NetworkRequestHoldingTime" SG_ 1873 GST_DPSS_Byte4 5000;
BA_ "Version" SG_ 1873 GST_DPSS_Byte4 "21.02.04";
BA_ "Description" SG_ 1873 GST_DPSS_Byte5 "TP Index : 122";
BA_ "UsrSigPurpose" SG_ 1873 GST_DPSS_Byte5 3;
BA_ "UserSigValidity" SG_ 1873 GST_DPSS_Byte5 0;
BA_REL_ "GenSigTimeoutTime" BU_SG_REL_ DPSU SG_ 1873 GST_DPSS_Byte5 0;
BA_ "NetworkRequest" SG_ 1873 GST_DPSS_Byte5 0;
BA_ "NetworkRequestHoldingTime" SG_ 1873 GST_DPSS_Byte5 5000;
BA_ "Version" SG_ 1873 GST_DPSS_Byte5 "21.02.04";
BA_ "Description" SG_ 1873 GST_DPSS_Byte6 "TP Index : 122";
BA_ "UsrSigPurpose" SG_ 1873 GST_DPSS_Byte6 3;
BA_ "UserSigValidity" SG_ 1873 GST_DPSS_Byte6 0;
BA_REL_ "GenSigTimeoutTime" BU_SG_REL_ DPSU SG_ 1873 GST_DPSS_Byte6 0;
BA_ "NetworkRequest" SG_ 1873 GST_DPSS_Byte6 0;
BA_ "NetworkRequestHoldingTime" SG_ 1873 GST_DPSS_Byte6 5000;
BA_ "Version" SG_ 1873 GST_DPSS_Byte6 "21.02.04";
BA_ "Description" SG_ 1873 GST_DPSS_Byte7 "TP Index : 122";
BA_ "UsrSigPurpose" SG_ 1873 GST_DPSS_Byte7 3;
BA_ "UserSigValidity" SG_ 1873 GST_DPSS_Byte7 0;
BA_REL_ "GenSigTimeoutTime" BU_SG_REL_ DPSU SG_ 1873 GST_DPSS_Byte7 0;
BA_ "NetworkRequest" SG_ 1873 GST_DPSS_Byte7 0;
BA_ "NetworkRequestHoldingTime" SG_ 1873 GST_DPSS_Byte7 5000;
BA_ "Version" SG_ 1873 GST_DPSS_Byte7 "21.02.04";
BA_ "Description" SG_ 1873 GST_DPSS_Byte1 "TP Index : 122";
BA_ "UsrSigPurpose" SG_ 1873 GST_DPSS_Byte1 3;
BA_ "UserSigValidity" SG_ 1873 GST_DPSS_Byte1 0;
BA_REL_ "GenSigTimeoutTime" BU_SG_REL_ DPSU SG_ 1873 GST_DPSS_Byte1 0;
BA_ "NetworkRequest" SG_ 1873 GST_DPSS_Byte1 0;
BA_ "NetworkRequestHoldingTime" SG_ 1873 GST_DPSS_Byte1 5000;
BA_ "Version" SG_ 1873 GST_DPSS_Byte1 "21.02.04";
BA_ "GenMsgCycleTime" BO_ 1842 0;
BA_ "GenMsgCycleTimeFast" BO_ 1842 0;
BA_ "GenMsgNrOfRepetition" BO_ 1842 0;
BA_ "DiagRequest" BO_ 1842 1;
BA_ "GenMsgILSupport" BO_ 1842 0;
BA_ "TpMessage" BO_ 1842 1;
BA_ "TpTxIndex" BO_ 1842 161;
BA_ "Description" SG_ 1842 GST_RLPSU_Byte0 "TP Index : 161";
BA_ "UsrSigPurpose" SG_ 1842 GST_RLPSU_Byte0 3;
BA_ "UserSigValidity" SG_ 1842 GST_RLPSU_Byte0 0;
BA_REL_ "GenSigTimeoutTime" BU_SG_REL_ RLPSU SG_ 1842 GST_RLPSU_Byte0 0;
BA_ "NetworkRequest" SG_ 1842 GST_RLPSU_Byte0 0;
BA_ "NetworkRequestHoldingTime" SG_ 1842 GST_RLPSU_Byte0 5000;
BA_ "Version" SG_ 1842 GST_RLPSU_Byte0 "21.02.04";
BA_ "Description" SG_ 1842 GST_RLPSU_Byte2 "TP Index : 161";
BA_ "UsrSigPurpose" SG_ 1842 GST_RLPSU_Byte2 3;
BA_ "UserSigValidity" SG_ 1842 GST_RLPSU_Byte2 0;
BA_REL_ "GenSigTimeoutTime" BU_SG_REL_ RLPSU SG_ 1842 GST_RLPSU_Byte2 0;
BA_ "NetworkRequest" SG_ 1842 GST_RLPSU_Byte2 0;
BA_ "NetworkRequestHoldingTime" SG_ 1842 GST_RLPSU_Byte2 5000;
BA_ "Version" SG_ 1842 GST_RLPSU_Byte2 "21.02.04";
BA_ "Description" SG_ 1842 GST_RLPSU_Byte3 "TP Index : 161";
BA_ "UsrSigPurpose" SG_ 1842 GST_RLPSU_Byte3 3;
BA_ "UserSigValidity" SG_ 1842 GST_RLPSU_Byte3 0;
BA_REL_ "GenSigTimeoutTime" BU_SG_REL_ RLPSU SG_ 1842 GST_RLPSU_Byte3 0;
BA_ "NetworkRequest" SG_ 1842 GST_RLPSU_Byte3 0;
BA_ "NetworkRequestHoldingTime" SG_ 1842 GST_RLPSU_Byte3 5000;
BA_ "Version" SG_ 1842 GST_RLPSU_Byte3 "21.02.04";
BA_ "Description" SG_ 1842 GST_RLPSU_Byte4 "TP Index : 161";
BA_ "UsrSigPurpose" SG_ 1842 GST_RLPSU_Byte4 3;
BA_ "UserSigValidity" SG_ 1842 GST_RLPSU_Byte4 0;
BA_REL_ "GenSigTimeoutTime" BU_SG_REL_ RLPSU SG_ 1842 GST_RLPSU_Byte4 0;
BA_ "NetworkRequest" SG_ 1842 GST_RLPSU_Byte4 0;
BA_ "NetworkRequestHoldingTime" SG_ 1842 GST_RLPSU_Byte4 5000;
BA_ "Version" SG_ 1842 GST_RLPSU_Byte4 "21.02.04";
BA_ "Description" SG_ 1842 GST_RLPSU_Byte5 "TP Index : 161";
BA_ "UsrSigPurpose" SG_ 1842 GST_RLPSU_Byte5 3;
BA_ "UserSigValidity" SG_ 1842 GST_RLPSU_Byte5 0;
BA_REL_ "GenSigTimeoutTime" BU_SG_REL_ RLPSU SG_ 1842 GST_RLPSU_Byte5 0;
BA_ "NetworkRequest" SG_ 1842 GST_RLPSU_Byte5 0;
BA_ "NetworkRequestHoldingTime" SG_ 1842 GST_RLPSU_Byte5 5000;
BA_ "Version" SG_ 1842 GST_RLPSU_Byte5 "21.02.04";
BA_ "Description" SG_ 1842 GST_RLPSU_Byte6 "TP Index : 161";
BA_ "UsrSigPurpose" SG_ 1842 GST_RLPSU_Byte6 3;
BA_ "UserSigValidity" SG_ 1842 GST_RLPSU_Byte6 0;
BA_REL_ "GenSigTimeoutTime" BU_SG_REL_ RLPSU SG_ 1842 GST_RLPSU_Byte6 0;
BA_ "NetworkRequest" SG_ 1842 GST_RLPSU_Byte6 0;
BA_ "NetworkRequestHoldingTime" SG_ 1842 GST_RLPSU_Byte6 5000;
BA_ "Version" SG_ 1842 GST_RLPSU_Byte6 "21.02.04";
BA_ "Description" SG_ 1842 GST_RLPSU_Byte7 "TP Index : 161";
BA_ "UsrSigPurpose" SG_ 1842 GST_RLPSU_Byte7 3;
BA_ "UserSigValidity" SG_ 1842 GST_RLPSU_Byte7 0;
BA_REL_ "GenSigTimeoutTime" BU_SG_REL_ RLPSU SG_ 1842 GST_RLPSU_Byte7 0;
BA_ "NetworkRequest" SG_ 1842 GST_RLPSU_Byte7 0;
BA_ "NetworkRequestHoldingTime" SG_ 1842 GST_RLPSU_Byte7 5000;
BA_ "Version" SG_ 1842 GST_RLPSU_Byte7 "21.02.04";
BA_ "Description" SG_ 1842 GST_RLPSU_Byte1 "TP Index : 161";
BA_ "UsrSigPurpose" SG_ 1842 GST_RLPSU_Byte1 3;
BA_ "UserSigValidity" SG_ 1842 GST_RLPSU_Byte1 0;
BA_REL_ "GenSigTimeoutTime" BU_SG_REL_ RLPSU SG_ 1842 GST_RLPSU_Byte1 0;
BA_ "NetworkRequest" SG_ 1842 GST_RLPSU_Byte1 0;
BA_ "NetworkRequestHoldingTime" SG_ 1842 GST_RLPSU_Byte1 5000;
BA_ "Version" SG_ 1842 GST_RLPSU_Byte1 "21.02.04";
BA_ "GenMsgCycleTime" BO_ 1841 0;
BA_ "GenMsgCycleTimeFast" BO_ 1841 0;
BA_ "GenMsgNrOfRepetition" BO_ 1841 0;
BA_ "DiagRequest" BO_ 1841 1;
BA_ "GenMsgILSupport" BO_ 1841 0;
BA_ "TpMessage" BO_ 1841 1;
BA_ "TpTxIndex" BO_ 1841 166;
BA_ "Description" SG_ 1841 GST_RRPSU_Byte0 "TP Index : 166";
BA_ "UsrSigPurpose" SG_ 1841 GST_RRPSU_Byte0 3;
BA_ "UserSigValidity" SG_ 1841 GST_RRPSU_Byte0 0;
BA_REL_ "GenSigTimeoutTime" BU_SG_REL_ RRPSU SG_ 1841 GST_RRPSU_Byte0 0;
BA_ "NetworkRequest" SG_ 1841 GST_RRPSU_Byte0 0;
BA_ "NetworkRequestHoldingTime" SG_ 1841 GST_RRPSU_Byte0 5000;
BA_ "Version" SG_ 1841 GST_RRPSU_Byte0 "21.02.04";
BA_ "Description" SG_ 1841 GST_RRPSU_Byte2 "TP Index : 166";
BA_ "UsrSigPurpose" SG_ 1841 GST_RRPSU_Byte2 3;
BA_ "UserSigValidity" SG_ 1841 GST_RRPSU_Byte2 0;
BA_REL_ "GenSigTimeoutTime" BU_SG_REL_ RRPSU SG_ 1841 GST_RRPSU_Byte2 0;
BA_ "NetworkRequest" SG_ 1841 GST_RRPSU_Byte2 0;
BA_ "NetworkRequestHoldingTime" SG_ 1841 GST_RRPSU_Byte2 5000;
BA_ "Version" SG_ 1841 GST_RRPSU_Byte2 "21.02.04";
BA_ "Description" SG_ 1841 GST_RRPSU_Byte3 "TP Index : 166";
BA_ "UsrSigPurpose" SG_ 1841 GST_RRPSU_Byte3 3;
BA_ "UserSigValidity" SG_ 1841 GST_RRPSU_Byte3 0;
BA_REL_ "GenSigTimeoutTime" BU_SG_REL_ RRPSU SG_ 1841 GST_RRPSU_Byte3 0;
BA_ "NetworkRequest" SG_ 1841 GST_RRPSU_Byte3 0;
BA_ "NetworkRequestHoldingTime" SG_ 1841 GST_RRPSU_Byte3 5000;
BA_ "Version" SG_ 1841 GST_RRPSU_Byte3 "21.02.04";
BA_ "Description" SG_ 1841 GST_RRPSU_Byte4 "TP Index : 166";
BA_ "UsrSigPurpose" SG_ 1841 GST_RRPSU_Byte4 3;
BA_ "UserSigValidity" SG_ 1841 GST_RRPSU_Byte4 0;
BA_REL_ "GenSigTimeoutTime" BU_SG_REL_ RRPSU SG_ 1841 GST_RRPSU_Byte4 0;
BA_ "NetworkRequest" SG_ 1841 GST_RRPSU_Byte4 0;
BA_ "NetworkRequestHoldingTime" SG_ 1841 GST_RRPSU_Byte4 5000;
BA_ "Version" SG_ 1841 GST_RRPSU_Byte4 "21.02.04";
BA_ "Description" SG_ 1841 GST_RRPSU_Byte5 "TP Index : 166";
BA_ "UsrSigPurpose" SG_ 1841 GST_RRPSU_Byte5 3;
BA_ "UserSigValidity" SG_ 1841 GST_RRPSU_Byte5 0;
BA_REL_ "GenSigTimeoutTime" BU_SG_REL_ RRPSU SG_ 1841 GST_RRPSU_Byte5 0;
BA_ "NetworkRequest" SG_ 1841 GST_RRPSU_Byte5 0;
BA_ "NetworkRequestHoldingTime" SG_ 1841 GST_RRPSU_Byte5 5000;
BA_ "Version" SG_ 1841 GST_RRPSU_Byte5 "21.02.04";
BA_ "Description" SG_ 1841 GST_RRPSU_Byte6 "TP Index : 166";
BA_ "UsrSigPurpose" SG_ 1841 GST_RRPSU_Byte6 3;
BA_ "UserSigValidity" SG_ 1841 GST_RRPSU_Byte6 0;
BA_REL_ "GenSigTimeoutTime" BU_SG_REL_ RRPSU SG_ 1841 GST_RRPSU_Byte6 0;
BA_ "NetworkRequest" SG_ 1841 GST_RRPSU_Byte6 0;
BA_ "NetworkRequestHoldingTime" SG_ 1841 GST_RRPSU_Byte6 5000;
BA_ "Version" SG_ 1841 GST_RRPSU_Byte6 "21.02.04";
BA_ "Description" SG_ 1841 GST_RRPSU_Byte7 "TP Index : 166";
BA_ "UsrSigPurpose" SG_ 1841 GST_RRPSU_Byte7 3;
BA_ "UserSigValidity" SG_ 1841 GST_RRPSU_Byte7 0;
BA_REL_ "GenSigTimeoutTime" BU_SG_REL_ RRPSU SG_ 1841 GST_RRPSU_Byte7 0;
BA_ "NetworkRequest" SG_ 1841 GST_RRPSU_Byte7 0;
BA_ "NetworkRequestHoldingTime" SG_ 1841 GST_RRPSU_Byte7 5000;
BA_ "Version" SG_ 1841 GST_RRPSU_Byte7 "21.02.04";
BA_ "Description" SG_ 1841 GST_RRPSU_Byte1 "TP Index : 166";
BA_ "UsrSigPurpose" SG_ 1841 GST_RRPSU_Byte1 3;
BA_ "UserSigValidity" SG_ 1841 GST_RRPSU_Byte1 0;
BA_REL_ "GenSigTimeoutTime" BU_SG_REL_ RRPSU SG_ 1841 GST_RRPSU_Byte1 0;
BA_ "NetworkRequest" SG_ 1841 GST_RRPSU_Byte1 0;
BA_ "NetworkRequestHoldingTime" SG_ 1841 GST_RRPSU_Byte1 5000;
BA_ "Version" SG_ 1841 GST_RRPSU_Byte1 "21.02.04";
BA_ "GenMsgSendType" BO_ 2210462209 0;
BA_ "GenMsgCycleTime" BO_ 2210462209 50;
BA_ "GenMsgCycleTimeFast" BO_ 2210462209 0;
BA_ "GenMsgNrOfRepetition" BO_ 2210462209 0;
BA_ "VFrameFormat" BO_ 2210462209 1;
BA_ "Description" SG_ 2210462209 HCU_Crc3Val "The data area for CRC calculation is based on the data length (DLC) of the message DB.

The CRC shall be calculated over the entire data block (excluding the CRC bytes) including the user data, alive counter and Data ID

 

- CRC Polynomial (0x1021) , Initial Value : 0xFFFF, XOR value : 0x0000, Data ID : Message ID + 0xF800 

- The initial value is for CRC calculation and the message should be sent with the calculated result value. 

- The mathematical expression to 16 bit CRC polynomial is given here. G(x) = x16 + x12 + x5 + 1";
BA_ "GenSigStartValue" SG_ 2210462209 HCU_Crc3Val 65535;
BA_ "UserSigValidity" SG_ 2210462209 HCU_Crc3Val 3;
BA_ "RoutingFactor" SG_ 2210462209 HCU_Crc3Val 5;
BA_ "Version" SG_ 2210462209 HCU_Crc3Val "18.11.08";
BA_ "Description" SG_ 2210462209 HCU_AlvCnt3Val "For the first transmission request for a data element the counter shall be initialized with 0 and shall be incremented by 1 for every subsequent send request. 

When the counter reaches the maximum value(0xFF), then it shall restart with 0 for the next send request";
BA_ "UserSigValidity" SG_ 2210462209 HCU_AlvCnt3Val 3;
BA_ "RoutingFactor" SG_ 2210462209 HCU_AlvCnt3Val 5;
BA_ "Version" SG_ 2210462209 HCU_AlvCnt3Val "18.11.08";
BA_ "Description" SG_ 2210462209 HCU_DrvWhlDmndTqNmVal "Driver's Demand Torque Restricted by Battery Limit and HHT Temperature (If MSB of high byte is 1, (PH) = 1 * (HEX) ? 65536 [Nm]

else (PH) = 1 * (HEX) [Nm])";
BA_ "UserSigValidity" SG_ 2210462209 HCU_DrvWhlDmndTqNmVal 3;
BA_ "RoutingFactor" SG_ 2210462209 HCU_DrvWhlDmndTqNmVal 5;
BA_ "Version" SG_ 2210462209 HCU_DrvWhlDmndTqNmVal "18.08.02";
BA_ "Description" SG_ 2210462209 HCU_DucUsrSetCluSta "DUC User Setting Pop Up for Cluster";
BA_ "UserSigValidity" SG_ 2210462209 HCU_DucUsrSetCluSta 3;
BA_ "RoutingFactor" SG_ 2210462209 HCU_DucUsrSetCluSta 5;
BA_ "Version" SG_ 2210462209 HCU_DucUsrSetCluSta "18.08.02";
BA_ "Description" SG_ 2210462209 HCU_DucVal "Drive Until Charge for AUTO CdCs";
BA_ "UserSigValidity" SG_ 2210462209 HCU_DucVal 3;
BA_ "RoutingFactor" SG_ 2210462209 HCU_DucVal 5;
BA_ "Version" SG_ 2210462209 HCU_DucVal "18.08.02";
BA_ "Description" SG_ 2210462209 HCU_EstAccelPdlPcVal "Speed Control Status";
BA_ "UserSigValidity" SG_ 2210462209 HCU_EstAccelPdlPcVal 3;
BA_ "RoutingFactor" SG_ 2210462209 HCU_EstAccelPdlPcVal 5;
BA_ "Version" SG_ 2210462209 HCU_EstAccelPdlPcVal "18.08.02";
BA_ "Description" SG_ 2210462209 HCU_EstApsSelSta "HCU Estimated APS Select when Cruise Mode";
BA_ "UserSigValidity" SG_ 2210462209 HCU_EstApsSelSta 3;
BA_ "RoutingFactor" SG_ 2210462209 HCU_EstApsSelSta 5;
BA_ "Version" SG_ 2210462209 HCU_EstApsSelSta "18.08.02";
BA_ "Description" SG_ 2210462209 HCU_GreenZoneDrvModSta "0x0:Default (USM ¹Ì Ç¥Ãâ (¸Þ´º»èÁ¦))

0x1:Off (USM Ç¥Ãâ Off »óÅÂ Ç¥½Ã)

0x2:On (USM Ç¥Ãâ On »óÅÂ Ç¥½Ã

0x3:reserved";
BA_ "UserSigValidity" SG_ 2210462209 HCU_GreenZoneDrvModSta 3;
BA_ "RoutingFactor" SG_ 2210462209 HCU_GreenZoneDrvModSta 5;
BA_ "Version" SG_ 2210462209 HCU_GreenZoneDrvModSta "18.08.02";
BA_ "GenMsgSendType" BO_ 2210462210 0;
BA_ "GenMsgCycleTime" BO_ 2210462210 50;
BA_ "GenMsgCycleTimeFast" BO_ 2210462210 0;
BA_ "GenMsgNrOfRepetition" BO_ 2210462210 0;
BA_ "VFrameFormat" BO_ 2210462210 1;
BA_ "Description" SG_ 2210462210 HCU_GreenZoneLmpDis "Indicate Green Zone Area";
BA_ "UserSigValidity" SG_ 2210462210 HCU_GreenZoneLmpDis 3;
BA_ "RoutingFactor" SG_ 2210462210 HCU_GreenZoneLmpDis 5;
BA_ "Version" SG_ 2210462210 HCU_GreenZoneLmpDis "18.08.02";
BA_ "Description" SG_ 2210462210 HCU_MILOnReq "HCU sends this signal to turn on the Malfunction Indicator Lamp (MIL).";
BA_ "UserSigValidity" SG_ 2210462210 HCU_MILOnReq 3;
BA_ "RoutingFactor" SG_ 2210462210 HCU_MILOnReq 5;
BA_ "Version" SG_ 2210462210 HCU_MILOnReq "18.08.02";
BA_ "Description" SG_ 2210462210 HCU_PhevAutoModOnSta "PHEV Auto CD CS Mode";
BA_ "UserSigValidity" SG_ 2210462210 HCU_PhevAutoModOnSta 3;
BA_ "RoutingFactor" SG_ 2210462210 HCU_PhevAutoModOnSta 5;
BA_ "Version" SG_ 2210462210 HCU_PhevAutoModOnSta "20.04.02";
BA_ "Description" SG_ 2210462210 HCU_SccDrvOvrdReq "CF_Hcu_Ovrride ¡Ø Start Value : set bit 

Override Drive by driver request during SCC";
BA_ "UserSigValidity" SG_ 2210462210 HCU_SccDrvOvrdReq 3;
BA_ "RoutingFactor" SG_ 2210462210 HCU_SccDrvOvrdReq 5;
BA_ "Version" SG_ 2210462210 HCU_SccDrvOvrdReq "18.08.02";
BA_ "Description" SG_ 2210462210 HCU_SccEnblSta "Smart Cruise Control Enable";
BA_ "UserSigValidity" SG_ 2210462210 HCU_SccEnblSta 3;
BA_ "RoutingFactor" SG_ 2210462210 HCU_SccEnblSta 5;
BA_ "Version" SG_ 2210462210 HCU_SccEnblSta "18.08.02";
BA_ "Description" SG_ 2210462210 HCU_SlwDnSta "HCU determine slowdown state when HCU received slowdown command from TMU";
BA_ "UserSigValidity" SG_ 2210462210 HCU_SlwDnSta 3;
BA_ "RoutingFactor" SG_ 2210462210 HCU_SlwDnSta 5;
BA_ "Version" SG_ 2210462210 HCU_SlwDnSta "18.08.02";
BA_ "Description" SG_ 2210462210 HCU_HcuRdySta "Hybrid Control Unit ready";
BA_ "UserSigValidity" SG_ 2210462210 HCU_HcuRdySta 3;
BA_ "RoutingFactor" SG_ 2210462210 HCU_HcuRdySta 5;
BA_ "Version" SG_ 2210462210 HCU_HcuRdySta "18.08.02";
BA_ "Description" SG_ 2210462210 HCU_SmrtEcoGdDis "This signal indicates whether Smart eco guide displays or not. Display equipment(clutster) follows the direction of the value of this signal.";
BA_ "UserSigValidity" SG_ 2210462210 HCU_SmrtEcoGdDis 3;
BA_ "RoutingFactor" SG_ 2210462210 HCU_SmrtEcoGdDis 5;
BA_ "Version" SG_ 2210462210 HCU_SmrtEcoGdDis "18.08.02";
BA_ "Description" SG_ 2210462210 HCU_SmrtEcoLvlDis "This signal is used on the cluster which displays the current driver's demand for Smart eco guide.";
BA_ "UserSigValidity" SG_ 2210462210 HCU_SmrtEcoLvlDis 3;
BA_ "RoutingFactor" SG_ 2210462210 HCU_SmrtEcoLvlDis 5;
BA_ "Version" SG_ 2210462210 HCU_SmrtEcoLvlDis "18.08.02";
BA_ "Description" SG_ 2210462210 HCU_SmrtEcoRngDis "This signal is used on the cluster which guides a driver to drive the car economically.It is variable regarding driving condition such as the road, traffic and so on.";
BA_ "UserSigValidity" SG_ 2210462210 HCU_SmrtEcoRngDis 3;
BA_ "RoutingFactor" SG_ 2210462210 HCU_SmrtEcoRngDis 5;
BA_ "Version" SG_ 2210462210 HCU_SmrtEcoRngDis "18.08.02";
BA_ "Description" SG_ 2210462210 HCU_SpdLimDeviceActSta "Speed Limiter Device in Activation";
BA_ "UserSigValidity" SG_ 2210462210 HCU_SpdLimDeviceActSta 3;
BA_ "RoutingFactor" SG_ 2210462210 HCU_SpdLimDeviceActSta 5;
BA_ "Version" SG_ 2210462210 HCU_SpdLimDeviceActSta "18.08.02";
BA_ "Description" SG_ 2210462210 HCU_SpdLimDeviceOperSta "Speed Limiter Device in Operation";
BA_ "UserSigValidity" SG_ 2210462210 HCU_SpdLimDeviceOperSta 3;
BA_ "RoutingFactor" SG_ 2210462210 HCU_SpdLimDeviceOperSta 5;
BA_ "Version" SG_ 2210462210 HCU_SpdLimDeviceOperSta "20.05.02";
BA_ "Description" SG_ 2210462210 HCU_HEVRdyDis "This signal indicates whether ¡°READY¡± lamp on cluster turns on or off.";
BA_ "UserSigValidity" SG_ 2210462210 HCU_HEVRdyDis 3;
BA_ "RoutingFactor" SG_ 2210462210 HCU_HEVRdyDis 5;
BA_ "Version" SG_ 2210462210 HCU_HEVRdyDis "19.09.02";
BA_ "Description" SG_ 2210462210 HCU_SpdLimDeviceVehSpdVal "Speed Limiter Vehicle Speed";
BA_ "UserSigValidity" SG_ 2210462210 HCU_SpdLimDeviceVehSpdVal 3;
BA_ "RoutingFactor" SG_ 2210462210 HCU_SpdLimDeviceVehSpdVal 5;
BA_ "Version" SG_ 2210462210 HCU_SpdLimDeviceVehSpdVal "18.08.02";
BA_ "Description" SG_ 2210462210 HCU_SrvModSta "Service Test Mode";
BA_ "UserSigValidity" SG_ 2210462210 HCU_SrvModSta 3;
BA_ "RoutingFactor" SG_ 2210462210 HCU_SrvModSta 5;
BA_ "Version" SG_ 2210462210 HCU_SrvModSta "18.08.02";
BA_ "Description" SG_ 2210462210 HCU_StrtInhbt2Sta "Start Inhibit";
BA_ "UserSigValidity" SG_ 2210462210 HCU_StrtInhbt2Sta 3;
BA_ "RoutingFactor" SG_ 2210462210 HCU_StrtInhbt2Sta 5;
BA_ "Version" SG_ 2210462210 HCU_StrtInhbt2Sta "18.08.02";
BA_ "Description" SG_ 2210462210 HCU_StrtInhbtSta "HCU determine Start Inhibit state when HCU received Start Inhibit command from TMU";
BA_ "UserSigValidity" SG_ 2210462210 HCU_StrtInhbtSta 3;
BA_ "RoutingFactor" SG_ 2210462210 HCU_StrtInhbtSta 5;
BA_ "Version" SG_ 2210462210 HCU_StrtInhbtSta "18.08.02";
BA_ "Description" SG_ 2210462210 HCU_SysShtOffReq "CF_Hcu_SysShutOffReq indicates System Shut Off Request or not.";
BA_ "UserSigValidity" SG_ 2210462210 HCU_SysShtOffReq 3;
BA_ "RoutingFactor" SG_ 2210462210 HCU_SysShtOffReq 5;
BA_ "Version" SG_ 2210462210 HCU_SysShtOffReq "18.08.02";
BA_ "Description" SG_ 2210462210 HCU_VehStrtEnblSta "Start";
BA_ "UserSigValidity" SG_ 2210462210 HCU_VehStrtEnblSta 3;
BA_ "RoutingFactor" SG_ 2210462210 HCU_VehStrtEnblSta 5;
BA_ "Version" SG_ 2210462210 HCU_VehStrtEnblSta "18.08.02";
BA_ "Description" SG_ 2210462210 HCU_BrkLmpOnReq "Brake Lamp On Request";
BA_ "UserSigValidity" SG_ 2210462210 HCU_BrkLmpOnReq 3;
BA_ "RoutingFactor" SG_ 2210462210 HCU_BrkLmpOnReq 5;
BA_ "Version" SG_ 2210462210 HCU_BrkLmpOnReq "19.06.02";
BA_ "Description" SG_ 2210462210 HCU_HevRdySta "Hybrid Vehicle Drivable ready";
BA_ "UserSigValidity" SG_ 2210462210 HCU_HevRdySta 3;
BA_ "RoutingFactor" SG_ 2210462210 HCU_HevRdySta 5;
BA_ "Version" SG_ 2210462210 HCU_HevRdySta "18.08.02";
BA_ "Description" SG_ 2210462210 HCU_CcDrvAlrtDis "CC must be disengaged by system or can not be engaged";
BA_ "UserSigValidity" SG_ 2210462210 HCU_CcDrvAlrtDis 3;
BA_ "RoutingFactor" SG_ 2210462210 HCU_CcDrvAlrtDis 5;
BA_ "Version" SG_ 2210462210 HCU_CcDrvAlrtDis "19.12.07";
BA_ "Description" SG_ 2210462210 HCU_SldDrvAlrtDis "SLD must be disengaged by system or cannot be engaged";
BA_ "UserSigValidity" SG_ 2210462210 HCU_SldDrvAlrtDis 3;
BA_ "RoutingFactor" SG_ 2210462210 HCU_SldDrvAlrtDis 5;
BA_ "Version" SG_ 2210462210 HCU_SldDrvAlrtDis "20.01.01";
BA_ "Description" SG_ 2210462210 HCU_LimpOffSta "Limp off the road";
BA_ "UserSigValidity" SG_ 2210462210 HCU_LimpOffSta 3;
BA_ "RoutingFactor" SG_ 2210462210 HCU_LimpOffSta 5;
BA_ "Version" SG_ 2210462210 HCU_LimpOffSta "18.08.02";
BA_ "GenMsgSendType" BO_ 2210462211 0;
BA_ "GenMsgCycleTime" BO_ 2210462211 50;
BA_ "GenMsgCycleTimeFast" BO_ 2210462211 0;
BA_ "GenMsgNrOfRepetition" BO_ 2210462211 0;
BA_ "VFrameFormat" BO_ 2210462211 1;
BA_ "Description" SG_ 2210462211 HCU_WhlCrpCrpTqNmVal "Creep Torque at wheel (If MSB of high byte is 1, (PH) = 1 * (HEX) ? 65536 [Nm]

else (PH) = 1 * (HEX) [Nm])";
BA_ "UserSigValidity" SG_ 2210462211 HCU_WhlCrpCrpTqNmVal 3;
BA_ "RoutingFactor" SG_ 2210462211 HCU_WhlCrpCrpTqNmVal 5;
BA_ "Version" SG_ 2210462211 HCU_WhlCrpCrpTqNmVal "18.08.02";
BA_ "Description" SG_ 2210462211 LHCU_EngCltchTrnsfrTqPcVal_Copy_1 "This signal indicates Engine Clutch Transfer Torque (If MSB of high byte is 1, (PH) = 0.1953125 * (HEX) -200 [%] Else (PH) = 0.1953125 * HEX) [%])";
BA_ "UserSigValidity" SG_ 2210462211 LHCU_EngCltchTrnsfrTqPcVal_Copy_1 3;
BA_ "RoutingFactor" SG_ 2210462211 LHCU_EngCltchTrnsfrTqPcVal_Copy_1 5;
BA_ "Version" SG_ 2210462211 LHCU_EngCltchTrnsfrTqPcVal_Copy_1 "18.08.12";
BA_ "Description" SG_ 2210462211 HCU_RspaAlvCntVal "RSPA HCU Alive Counter";
BA_ "UserSigValidity" SG_ 2210462211 HCU_RspaAlvCntVal 3;
BA_ "RoutingFactor" SG_ 2210462211 HCU_RspaAlvCntVal 5;
BA_ "Version" SG_ 2210462211 HCU_RspaAlvCntVal "19.01.12";
BA_ "Description" SG_ 2210462211 HCU_RspaSta "HCU RSPA Cooperative control state";
BA_ "UserSigValidity" SG_ 2210462211 HCU_RspaSta 3;
BA_ "RoutingFactor" SG_ 2210462211 HCU_RspaSta 5;
BA_ "Version" SG_ 2210462211 HCU_RspaSta "19.01.12";
BA_ "Description" SG_ 2210462211 HCU_RspaCanFailSta "HCU RSPA CAN Fail Status";
BA_ "UserSigValidity" SG_ 2210462211 HCU_RspaCanFailSta 3;
BA_ "RoutingFactor" SG_ 2210462211 HCU_RspaCanFailSta 5;
BA_ "Version" SG_ 2210462211 HCU_RspaCanFailSta "19.01.12";
BA_ "Description" SG_ 2210462211 HCU_PdlStopCtrlSta "Request Signal for Paddle B Stop Control";
BA_ "UserSigValidity" SG_ 2210462211 HCU_PdlStopCtrlSta 3;
BA_ "RoutingFactor" SG_ 2210462211 HCU_PdlStopCtrlSta 5;
BA_ "Version" SG_ 2210462211 HCU_PdlStopCtrlSta "20.08.02";
BA_ "Description" SG_ 2210462211 HCU_PdlStopReqTqNmVal "Request Brake tq for Paddle B Stop Control";
BA_ "UserSigValidity" SG_ 2210462211 HCU_PdlStopReqTqNmVal 3;
BA_ "RoutingFactor" SG_ 2210462211 HCU_PdlStopReqTqNmVal 5;
BA_ "Version" SG_ 2210462211 HCU_PdlStopReqTqNmVal "20.08.02";
BA_ "Description" SG_ 2210462211 HCU_GearRInhbtSta "Drive inhibit flag in reverse gear.";
BA_ "UserSigValidity" SG_ 2210462211 HCU_GearRInhbtSta 3;
BA_ "RoutingFactor" SG_ 2210462211 HCU_GearRInhbtSta 5;
BA_ "Version" SG_ 2210462211 HCU_GearRInhbtSta "20.11.03";
BA_ "GenMsgSendType" BO_ 2210462212 0;
BA_ "GenMsgCycleTime" BO_ 2210462212 50;
BA_ "GenMsgCycleTimeFast" BO_ 2210462212 0;
BA_ "GenMsgNrOfRepetition" BO_ 2210462212 0;
BA_ "VFrameFormat" BO_ 2210462212 1;
BA_ "GenMsgSendType" BO_ 881 0;
BA_ "GenMsgCycleTime" BO_ 881 1000;
BA_ "GenMsgCycleTimeFast" BO_ 881 0;
BA_ "GenMsgNrOfRepetition" BO_ 881 0;
BA_ "Description" SG_ 881 HU_GNSS_UTC_year "2000+";
BA_ "UserSigValidity" SG_ 881 HU_GNSS_UTC_year 1;
BA_REL_ "GenSigTimeoutTime" BU_SG_REL_ BLTN_CAM SG_ 881 HU_GNSS_UTC_year 5000;
BA_ "Version" SG_ 881 HU_GNSS_UTC_year "21.08.01";
BA_ "Description" SG_ 881 HU_GNSS_UTC_month "range : [1, 12]";
BA_ "UserSigValidity" SG_ 881 HU_GNSS_UTC_month 1;
BA_REL_ "GenSigTimeoutTime" BU_SG_REL_ BLTN_CAM SG_ 881 HU_GNSS_UTC_month 5000;
BA_ "Version" SG_ 881 HU_GNSS_UTC_month "21.08.01";
BA_ "Description" SG_ 881 HU_GNSS_UTC_day "range : [1, 31]";
BA_ "UserSigValidity" SG_ 881 HU_GNSS_UTC_day 1;
BA_REL_ "GenSigTimeoutTime" BU_SG_REL_ BLTN_CAM SG_ 881 HU_GNSS_UTC_day 5000;
BA_ "Version" SG_ 881 HU_GNSS_UTC_day "21.08.01";
BA_ "Description" SG_ 881 HU_GNSS_UTC_hour "range : [0, 23]";
BA_ "UserSigValidity" SG_ 881 HU_GNSS_UTC_hour 1;
BA_REL_ "GenSigTimeoutTime" BU_SG_REL_ BLTN_CAM SG_ 881 HU_GNSS_UTC_hour 5000;
BA_ "Version" SG_ 881 HU_GNSS_UTC_hour "21.08.01";
BA_ "Description" SG_ 881 HU_GNSS_UTC_min "range : [0,59]";
BA_ "UserSigValidity" SG_ 881 HU_GNSS_UTC_min 1;
BA_REL_ "GenSigTimeoutTime" BU_SG_REL_ BLTN_CAM SG_ 881 HU_GNSS_UTC_min 5000;
BA_ "Version" SG_ 881 HU_GNSS_UTC_min "21.08.01";
BA_ "Description" SG_ 881 HU_GNSS_UTC_sec "ragne : [0, 60]  /  60 only for the leap second";
BA_ "UserSigValidity" SG_ 881 HU_GNSS_UTC_sec 1;
BA_REL_ "GenSigTimeoutTime" BU_SG_REL_ BLTN_CAM SG_ 881 HU_GNSS_UTC_sec 5000;
BA_ "Version" SG_ 881 HU_GNSS_UTC_sec "21.08.01";
BA_ "Description" SG_ 881 HU_GNSS_UTC_offset "GPS = UTC + offset";
BA_ "UserSigValidity" SG_ 881 HU_GNSS_UTC_offset 1;
BA_REL_ "GenSigTimeoutTime" BU_SG_REL_ BLTN_CAM SG_ 881 HU_GNSS_UTC_offset 5000;
BA_ "Version" SG_ 881 HU_GNSS_UTC_offset "21.08.01";
BA_ "GenMsgSendType" BO_ 883 0;
BA_ "GenMsgCycleTime" BO_ 883 1000;
BA_ "GenMsgCycleTimeFast" BO_ 883 0;
BA_ "GenMsgNrOfRepetition" BO_ 883 0;
BA_ "Description" SG_ 883 HU_GNSS_DGPS_age "whed using DGPS, (DGPS time - current time.)";
BA_ "UserSigValidity" SG_ 883 HU_GNSS_DGPS_age 1;
BA_ "Version" SG_ 883 HU_GNSS_DGPS_age "21.08.01";
BA_ "UserSigValidity" SG_ 883 HU_GNSS_TimeSource 1;
BA_ "Version" SG_ 883 HU_GNSS_TimeSource "21.08.01";
BA_ "UserSigValidity" SG_ 883 HU_GNSS_search 1;
BA_ "Version" SG_ 883 HU_GNSS_search "21.08.01";
BA_ "Description" SG_ 883 HU_GNSS_DST "DST setting";
BA_ "GenSigStartValue" SG_ 883 HU_GNSS_DST 3;
BA_ "UserSigValidity" SG_ 883 HU_GNSS_DST 1;
BA_REL_ "GenSigTimeoutTime" BU_SG_REL_ BLTN_CAM SG_ 883 HU_GNSS_DST 5000;
BA_ "Version" SG_ 883 HU_GNSS_DST "21.08.01";
BA_ "UserSigValidity" SG_ 883 HU_GNSS_SV_count 1;
BA_ "Version" SG_ 883 HU_GNSS_SV_count "21.08.01";
BA_ "Description" SG_ 883 HU_GNSS_TimezoneOffset "offset = [ value * factor(15) ] min.";
BA_ "UserSigValidity" SG_ 883 HU_GNSS_TimezoneOffset 1;
BA_REL_ "GenSigTimeoutTime" BU_SG_REL_ BLTN_CAM SG_ 883 HU_GNSS_TimezoneOffset 5000;
BA_ "Version" SG_ 883 HU_GNSS_TimezoneOffset "21.08.01";
BA_ "UserSigValidity" SG_ 883 HU_GNSS_Fix_status 1;
BA_ "Version" SG_ 883 HU_GNSS_Fix_status "21.08.01";
BA_ "GenMsgSendType" BO_ 884 0;
BA_ "GenMsgCycleTime" BO_ 884 1000;
BA_ "GenMsgCycleTimeFast" BO_ 884 0;
BA_ "GenMsgNrOfRepetition" BO_ 884 0;
BA_ "Description" SG_ 884 HU_MM_Latitude "range = -90*1,000,000 <= Value <=90*1,000,000

unit = degree*1,000,000";
BA_ "UserSigValidity" SG_ 884 HU_MM_Latitude 1;
BA_REL_ "GenSigTimeoutTime" BU_SG_REL_ BLTN_CAM SG_ 884 HU_MM_Latitude 5000;
BA_ "Version" SG_ 884 HU_MM_Latitude "21.08.01";
BA_ "Description" SG_ 884 HU_MM_Longitude "range = -180*1,000,000 <= Value <= 180*1,000,000

unit = degree*1,000,000";
BA_ "UserSigValidity" SG_ 884 HU_MM_Longitude 1;
BA_REL_ "GenSigTimeoutTime" BU_SG_REL_ BLTN_CAM SG_ 884 HU_MM_Longitude 5000;
BA_ "Version" SG_ 884 HU_MM_Longitude "21.08.01";
BA_ "GenMsgCycleTime" BO_ 1833 0;
BA_ "GenMsgCycleTimeFast" BO_ 1833 0;
BA_ "GenMsgNrOfRepetition" BO_ 1833 0;
BA_ "DiagResponse" BO_ 1833 1;
BA_ "GenMsgILSupport" BO_ 1833 0;
BA_ "TpMessage" BO_ 1833 1;
BA_ "TpTxIndex" BO_ 1833 153;
BA_ "Description" SG_ 1833 PFSU_GST_Byte0 "TP Index : 153";
BA_ "UsrSigPurpose" SG_ 1833 PFSU_GST_Byte0 4;
BA_ "UserSigValidity" SG_ 1833 PFSU_GST_Byte0 0;
BA_REL_ "GenSigTimeoutTime" BU_SG_REL_ CGW_CCU SG_ 1833 PFSU_GST_Byte0 0;
BA_ "NetworkRequest" SG_ 1833 PFSU_GST_Byte0 0;
BA_ "NetworkRequestHoldingTime" SG_ 1833 PFSU_GST_Byte0 5000;
BA_ "Version" SG_ 1833 PFSU_GST_Byte0 "21.02.04";
BA_ "Description" SG_ 1833 PFSU_GST_Byte2 "TP Index : 153";
BA_ "UsrSigPurpose" SG_ 1833 PFSU_GST_Byte2 4;
BA_ "UserSigValidity" SG_ 1833 PFSU_GST_Byte2 0;
BA_REL_ "GenSigTimeoutTime" BU_SG_REL_ CGW_CCU SG_ 1833 PFSU_GST_Byte2 0;
BA_ "NetworkRequest" SG_ 1833 PFSU_GST_Byte2 0;
BA_ "NetworkRequestHoldingTime" SG_ 1833 PFSU_GST_Byte2 5000;
BA_ "Version" SG_ 1833 PFSU_GST_Byte2 "21.02.04";
BA_ "Description" SG_ 1833 PFSU_GST_Byte3 "TP Index : 153";
BA_ "UsrSigPurpose" SG_ 1833 PFSU_GST_Byte3 4;
BA_ "UserSigValidity" SG_ 1833 PFSU_GST_Byte3 0;
BA_REL_ "GenSigTimeoutTime" BU_SG_REL_ CGW_CCU SG_ 1833 PFSU_GST_Byte3 0;
BA_ "NetworkRequest" SG_ 1833 PFSU_GST_Byte3 0;
BA_ "NetworkRequestHoldingTime" SG_ 1833 PFSU_GST_Byte3 5000;
BA_ "Version" SG_ 1833 PFSU_GST_Byte3 "21.02.04";
BA_ "Description" SG_ 1833 PFSU_GST_Byte4 "TP Index : 153";
BA_ "UsrSigPurpose" SG_ 1833 PFSU_GST_Byte4 4;
BA_ "UserSigValidity" SG_ 1833 PFSU_GST_Byte4 0;
BA_REL_ "GenSigTimeoutTime" BU_SG_REL_ CGW_CCU SG_ 1833 PFSU_GST_Byte4 0;
BA_ "NetworkRequest" SG_ 1833 PFSU_GST_Byte4 0;
BA_ "NetworkRequestHoldingTime" SG_ 1833 PFSU_GST_Byte4 5000;
BA_ "Version" SG_ 1833 PFSU_GST_Byte4 "21.02.04";
BA_ "Description" SG_ 1833 PFSU_GST_Byte5 "TP Index : 153";
BA_ "UsrSigPurpose" SG_ 1833 PFSU_GST_Byte5 4;
BA_ "UserSigValidity" SG_ 1833 PFSU_GST_Byte5 0;
BA_REL_ "GenSigTimeoutTime" BU_SG_REL_ CGW_CCU SG_ 1833 PFSU_GST_Byte5 0;
BA_ "NetworkRequest" SG_ 1833 PFSU_GST_Byte5 0;
BA_ "NetworkRequestHoldingTime" SG_ 1833 PFSU_GST_Byte5 5000;
BA_ "Version" SG_ 1833 PFSU_GST_Byte5 "21.02.04";
BA_ "Description" SG_ 1833 PFSU_GST_Byte6 "TP Index : 153";
BA_ "UsrSigPurpose" SG_ 1833 PFSU_GST_Byte6 4;
BA_ "UserSigValidity" SG_ 1833 PFSU_GST_Byte6 0;
BA_REL_ "GenSigTimeoutTime" BU_SG_REL_ CGW_CCU SG_ 1833 PFSU_GST_Byte6 0;
BA_ "NetworkRequest" SG_ 1833 PFSU_GST_Byte6 0;
BA_ "NetworkRequestHoldingTime" SG_ 1833 PFSU_GST_Byte6 5000;
BA_ "Version" SG_ 1833 PFSU_GST_Byte6 "21.02.04";
BA_ "Description" SG_ 1833 PFSU_GST_Byte7 "TP Index : 153";
BA_ "UsrSigPurpose" SG_ 1833 PFSU_GST_Byte7 4;
BA_ "UserSigValidity" SG_ 1833 PFSU_GST_Byte7 0;
BA_REL_ "GenSigTimeoutTime" BU_SG_REL_ CGW_CCU SG_ 1833 PFSU_GST_Byte7 0;
BA_ "NetworkRequest" SG_ 1833 PFSU_GST_Byte7 0;
BA_ "NetworkRequestHoldingTime" SG_ 1833 PFSU_GST_Byte7 5000;
BA_ "Version" SG_ 1833 PFSU_GST_Byte7 "21.02.04";
BA_ "Description" SG_ 1833 PFSU_GST_Byte1 "TP Index : 153";
BA_ "UsrSigPurpose" SG_ 1833 PFSU_GST_Byte1 4;
BA_ "UserSigValidity" SG_ 1833 PFSU_GST_Byte1 0;
BA_REL_ "GenSigTimeoutTime" BU_SG_REL_ CGW_CCU SG_ 1833 PFSU_GST_Byte1 0;
BA_ "NetworkRequest" SG_ 1833 PFSU_GST_Byte1 0;
BA_ "NetworkRequestHoldingTime" SG_ 1833 PFSU_GST_Byte1 5000;
BA_ "Version" SG_ 1833 PFSU_GST_Byte1 "21.02.04";
BA_ "GenMsgCycleTime" BO_ 1850 0;
BA_ "GenMsgCycleTimeFast" BO_ 1850 0;
BA_ "GenMsgNrOfRepetition" BO_ 1850 0;
BA_ "DiagResponse" BO_ 1850 1;
BA_ "GenMsgILSupport" BO_ 1850 0;
BA_ "TpMessage" BO_ 1850 1;
BA_ "TpTxIndex" BO_ 1850 161;
BA_ "Description" SG_ 1850 RLPSU_GST_Byte0 "TP Index : 161";
BA_ "UsrSigPurpose" SG_ 1850 RLPSU_GST_Byte0 4;
BA_ "UserSigValidity" SG_ 1850 RLPSU_GST_Byte0 0;
BA_REL_ "GenSigTimeoutTime" BU_SG_REL_ CGW_CCU SG_ 1850 RLPSU_GST_Byte0 0;
BA_ "NetworkRequest" SG_ 1850 RLPSU_GST_Byte0 0;
BA_ "NetworkRequestHoldingTime" SG_ 1850 RLPSU_GST_Byte0 5000;
BA_ "Version" SG_ 1850 RLPSU_GST_Byte0 "21.02.04";
BA_ "Description" SG_ 1850 RLPSU_GST_Byte2 "TP Index : 161";
BA_ "UsrSigPurpose" SG_ 1850 RLPSU_GST_Byte2 4;
BA_ "UserSigValidity" SG_ 1850 RLPSU_GST_Byte2 0;
BA_REL_ "GenSigTimeoutTime" BU_SG_REL_ CGW_CCU SG_ 1850 RLPSU_GST_Byte2 0;
BA_ "NetworkRequest" SG_ 1850 RLPSU_GST_Byte2 0;
BA_ "NetworkRequestHoldingTime" SG_ 1850 RLPSU_GST_Byte2 5000;
BA_ "Version" SG_ 1850 RLPSU_GST_Byte2 "21.02.04";
BA_ "Description" SG_ 1850 RLPSU_GST_Byte3 "TP Index : 161";
BA_ "UsrSigPurpose" SG_ 1850 RLPSU_GST_Byte3 4;
BA_ "UserSigValidity" SG_ 1850 RLPSU_GST_Byte3 0;
BA_REL_ "GenSigTimeoutTime" BU_SG_REL_ CGW_CCU SG_ 1850 RLPSU_GST_Byte3 0;
BA_ "NetworkRequest" SG_ 1850 RLPSU_GST_Byte3 0;
BA_ "NetworkRequestHoldingTime" SG_ 1850 RLPSU_GST_Byte3 5000;
BA_ "Version" SG_ 1850 RLPSU_GST_Byte3 "21.02.04";
BA_ "Description" SG_ 1850 RLPSU_GST_Byte4 "TP Index : 161";
BA_ "UsrSigPurpose" SG_ 1850 RLPSU_GST_Byte4 4;
BA_ "UserSigValidity" SG_ 1850 RLPSU_GST_Byte4 0;
BA_REL_ "GenSigTimeoutTime" BU_SG_REL_ CGW_CCU SG_ 1850 RLPSU_GST_Byte4 0;
BA_ "NetworkRequest" SG_ 1850 RLPSU_GST_Byte4 0;
BA_ "NetworkRequestHoldingTime" SG_ 1850 RLPSU_GST_Byte4 5000;
BA_ "Version" SG_ 1850 RLPSU_GST_Byte4 "21.02.04";
BA_ "Description" SG_ 1850 RLPSU_GST_Byte5 "TP Index : 161";
BA_ "UsrSigPurpose" SG_ 1850 RLPSU_GST_Byte5 4;
BA_ "UserSigValidity" SG_ 1850 RLPSU_GST_Byte5 0;
BA_REL_ "GenSigTimeoutTime" BU_SG_REL_ CGW_CCU SG_ 1850 RLPSU_GST_Byte5 0;
BA_ "NetworkRequest" SG_ 1850 RLPSU_GST_Byte5 0;
BA_ "NetworkRequestHoldingTime" SG_ 1850 RLPSU_GST_Byte5 5000;
BA_ "Version" SG_ 1850 RLPSU_GST_Byte5 "21.02.04";
BA_ "Description" SG_ 1850 RLPSU_GST_Byte6 "TP Index : 161";
BA_ "UsrSigPurpose" SG_ 1850 RLPSU_GST_Byte6 4;
BA_ "UserSigValidity" SG_ 1850 RLPSU_GST_Byte6 0;
BA_REL_ "GenSigTimeoutTime" BU_SG_REL_ CGW_CCU SG_ 1850 RLPSU_GST_Byte6 0;
BA_ "NetworkRequest" SG_ 1850 RLPSU_GST_Byte6 0;
BA_ "NetworkRequestHoldingTime" SG_ 1850 RLPSU_GST_Byte6 5000;
BA_ "Version" SG_ 1850 RLPSU_GST_Byte6 "21.02.04";
BA_ "Description" SG_ 1850 RLPSU_GST_Byte7 "TP Index : 161";
BA_ "UsrSigPurpose" SG_ 1850 RLPSU_GST_Byte7 4;
BA_ "UserSigValidity" SG_ 1850 RLPSU_GST_Byte7 0;
BA_REL_ "GenSigTimeoutTime" BU_SG_REL_ CGW_CCU SG_ 1850 RLPSU_GST_Byte7 0;
BA_ "NetworkRequest" SG_ 1850 RLPSU_GST_Byte7 0;
BA_ "NetworkRequestHoldingTime" SG_ 1850 RLPSU_GST_Byte7 5000;
BA_ "Version" SG_ 1850 RLPSU_GST_Byte7 "21.02.04";
BA_ "Description" SG_ 1850 RLPSU_GST_Byte1 "TP Index : 161";
BA_ "UsrSigPurpose" SG_ 1850 RLPSU_GST_Byte1 4;
BA_ "UserSigValidity" SG_ 1850 RLPSU_GST_Byte1 0;
BA_REL_ "GenSigTimeoutTime" BU_SG_REL_ CGW_CCU SG_ 1850 RLPSU_GST_Byte1 0;
BA_ "NetworkRequest" SG_ 1850 RLPSU_GST_Byte1 0;
BA_ "NetworkRequestHoldingTime" SG_ 1850 RLPSU_GST_Byte1 5000;
BA_ "Version" SG_ 1850 RLPSU_GST_Byte1 "21.02.04";
BA_ "GenMsgCycleTime" BO_ 1849 0;
BA_ "GenMsgCycleTimeFast" BO_ 1849 0;
BA_ "GenMsgNrOfRepetition" BO_ 1849 0;
BA_ "DiagResponse" BO_ 1849 1;
BA_ "GenMsgILSupport" BO_ 1849 0;
BA_ "TpMessage" BO_ 1849 1;
BA_ "TpTxIndex" BO_ 1849 166;
BA_ "Description" SG_ 1849 RRPSU_GST_Byte0 "TP Index : 166";
BA_ "UsrSigPurpose" SG_ 1849 RRPSU_GST_Byte0 4;
BA_ "UserSigValidity" SG_ 1849 RRPSU_GST_Byte0 0;
BA_REL_ "GenSigTimeoutTime" BU_SG_REL_ CGW_CCU SG_ 1849 RRPSU_GST_Byte0 0;
BA_ "NetworkRequest" SG_ 1849 RRPSU_GST_Byte0 0;
BA_ "NetworkRequestHoldingTime" SG_ 1849 RRPSU_GST_Byte0 5000;
BA_ "Version" SG_ 1849 RRPSU_GST_Byte0 "21.02.04";
BA_ "Description" SG_ 1849 RRPSU_GST_Byte2 "TP Index : 166";
BA_ "UsrSigPurpose" SG_ 1849 RRPSU_GST_Byte2 4;
BA_ "UserSigValidity" SG_ 1849 RRPSU_GST_Byte2 0;
BA_REL_ "GenSigTimeoutTime" BU_SG_REL_ CGW_CCU SG_ 1849 RRPSU_GST_Byte2 0;
BA_ "NetworkRequest" SG_ 1849 RRPSU_GST_Byte2 0;
BA_ "NetworkRequestHoldingTime" SG_ 1849 RRPSU_GST_Byte2 5000;
BA_ "Version" SG_ 1849 RRPSU_GST_Byte2 "21.02.04";
BA_ "Description" SG_ 1849 RRPSU_GST_Byte3 "TP Index : 166";
BA_ "UsrSigPurpose" SG_ 1849 RRPSU_GST_Byte3 4;
BA_ "UserSigValidity" SG_ 1849 RRPSU_GST_Byte3 0;
BA_REL_ "GenSigTimeoutTime" BU_SG_REL_ CGW_CCU SG_ 1849 RRPSU_GST_Byte3 0;
BA_ "NetworkRequest" SG_ 1849 RRPSU_GST_Byte3 0;
BA_ "NetworkRequestHoldingTime" SG_ 1849 RRPSU_GST_Byte3 5000;
BA_ "Version" SG_ 1849 RRPSU_GST_Byte3 "21.02.04";
BA_ "Description" SG_ 1849 RRPSU_GST_Byte4 "TP Index : 166";
BA_ "UsrSigPurpose" SG_ 1849 RRPSU_GST_Byte4 4;
BA_ "UserSigValidity" SG_ 1849 RRPSU_GST_Byte4 0;
BA_REL_ "GenSigTimeoutTime" BU_SG_REL_ CGW_CCU SG_ 1849 RRPSU_GST_Byte4 0;
BA_ "NetworkRequest" SG_ 1849 RRPSU_GST_Byte4 0;
BA_ "NetworkRequestHoldingTime" SG_ 1849 RRPSU_GST_Byte4 5000;
BA_ "Version" SG_ 1849 RRPSU_GST_Byte4 "21.02.04";
BA_ "Description" SG_ 1849 RRPSU_GST_Byte5 "TP Index : 166";
BA_ "UsrSigPurpose" SG_ 1849 RRPSU_GST_Byte5 4;
BA_ "UserSigValidity" SG_ 1849 RRPSU_GST_Byte5 0;
BA_REL_ "GenSigTimeoutTime" BU_SG_REL_ CGW_CCU SG_ 1849 RRPSU_GST_Byte5 0;
BA_ "NetworkRequest" SG_ 1849 RRPSU_GST_Byte5 0;
BA_ "NetworkRequestHoldingTime" SG_ 1849 RRPSU_GST_Byte5 5000;
BA_ "Version" SG_ 1849 RRPSU_GST_Byte5 "21.02.04";
BA_ "Description" SG_ 1849 RRPSU_GST_Byte6 "TP Index : 166";
BA_ "UsrSigPurpose" SG_ 1849 RRPSU_GST_Byte6 4;
BA_ "UserSigValidity" SG_ 1849 RRPSU_GST_Byte6 0;
BA_REL_ "GenSigTimeoutTime" BU_SG_REL_ CGW_CCU SG_ 1849 RRPSU_GST_Byte6 0;
BA_ "NetworkRequest" SG_ 1849 RRPSU_GST_Byte6 0;
BA_ "NetworkRequestHoldingTime" SG_ 1849 RRPSU_GST_Byte6 5000;
BA_ "Version" SG_ 1849 RRPSU_GST_Byte6 "21.02.04";
BA_ "Description" SG_ 1849 RRPSU_GST_Byte7 "TP Index : 166";
BA_ "UsrSigPurpose" SG_ 1849 RRPSU_GST_Byte7 4;
BA_ "UserSigValidity" SG_ 1849 RRPSU_GST_Byte7 0;
BA_REL_ "GenSigTimeoutTime" BU_SG_REL_ CGW_CCU SG_ 1849 RRPSU_GST_Byte7 0;
BA_ "NetworkRequest" SG_ 1849 RRPSU_GST_Byte7 0;
BA_ "NetworkRequestHoldingTime" SG_ 1849 RRPSU_GST_Byte7 5000;
BA_ "Version" SG_ 1849 RRPSU_GST_Byte7 "21.02.04";
BA_ "Description" SG_ 1849 RRPSU_GST_Byte1 "TP Index : 166";
BA_ "UsrSigPurpose" SG_ 1849 RRPSU_GST_Byte1 4;
BA_ "UserSigValidity" SG_ 1849 RRPSU_GST_Byte1 0;
BA_REL_ "GenSigTimeoutTime" BU_SG_REL_ CGW_CCU SG_ 1849 RRPSU_GST_Byte1 0;
BA_ "NetworkRequest" SG_ 1849 RRPSU_GST_Byte1 0;
BA_ "NetworkRequestHoldingTime" SG_ 1849 RRPSU_GST_Byte1 5000;
BA_ "Version" SG_ 1849 RRPSU_GST_Byte1 "21.02.04";
BA_ "GenMsgCycleTime" BO_ 1836 0;
BA_ "GenMsgCycleTimeFast" BO_ 1836 0;
BA_ "GenMsgNrOfRepetition" BO_ 1836 0;
BA_ "DiagResponse" BO_ 1836 1;
BA_ "GenMsgILSupport" BO_ 1836 0;
BA_ "TpMessage" BO_ 1836 1;
BA_ "TpTxIndex" BO_ 1836 168;
BA_ "Description" SG_ 1836 RWPC_GST_Byte0 "TP Index : 168";
BA_ "UsrSigPurpose" SG_ 1836 RWPC_GST_Byte0 4;
BA_ "UserSigValidity" SG_ 1836 RWPC_GST_Byte0 0;
BA_REL_ "GenSigTimeoutTime" BU_SG_REL_ CGW_CCU SG_ 1836 RWPC_GST_Byte0 0;
BA_ "NetworkRequest" SG_ 1836 RWPC_GST_Byte0 0;
BA_ "NetworkRequestHoldingTime" SG_ 1836 RWPC_GST_Byte0 5000;
BA_ "Version" SG_ 1836 RWPC_GST_Byte0 "21.02.04";
BA_ "Description" SG_ 1836 RWPC_GST_Byte2 "TP Index : 168";
BA_ "UsrSigPurpose" SG_ 1836 RWPC_GST_Byte2 4;
BA_ "UserSigValidity" SG_ 1836 RWPC_GST_Byte2 0;
BA_REL_ "GenSigTimeoutTime" BU_SG_REL_ CGW_CCU SG_ 1836 RWPC_GST_Byte2 0;
BA_ "NetworkRequest" SG_ 1836 RWPC_GST_Byte2 0;
BA_ "NetworkRequestHoldingTime" SG_ 1836 RWPC_GST_Byte2 5000;
BA_ "Version" SG_ 1836 RWPC_GST_Byte2 "21.02.04";
BA_ "Description" SG_ 1836 RWPC_GST_Byte3 "TP Index : 168";
BA_ "UsrSigPurpose" SG_ 1836 RWPC_GST_Byte3 4;
BA_ "UserSigValidity" SG_ 1836 RWPC_GST_Byte3 0;
BA_REL_ "GenSigTimeoutTime" BU_SG_REL_ CGW_CCU SG_ 1836 RWPC_GST_Byte3 0;
BA_ "NetworkRequest" SG_ 1836 RWPC_GST_Byte3 0;
BA_ "NetworkRequestHoldingTime" SG_ 1836 RWPC_GST_Byte3 5000;
BA_ "Version" SG_ 1836 RWPC_GST_Byte3 "21.02.04";
BA_ "Description" SG_ 1836 RWPC_GST_Byte4 "TP Index : 168";
BA_ "UsrSigPurpose" SG_ 1836 RWPC_GST_Byte4 4;
BA_ "UserSigValidity" SG_ 1836 RWPC_GST_Byte4 0;
BA_REL_ "GenSigTimeoutTime" BU_SG_REL_ CGW_CCU SG_ 1836 RWPC_GST_Byte4 0;
BA_ "NetworkRequest" SG_ 1836 RWPC_GST_Byte4 0;
BA_ "NetworkRequestHoldingTime" SG_ 1836 RWPC_GST_Byte4 5000;
BA_ "Version" SG_ 1836 RWPC_GST_Byte4 "21.02.04";
BA_ "Description" SG_ 1836 RWPC_GST_Byte5 "TP Index : 168";
BA_ "UsrSigPurpose" SG_ 1836 RWPC_GST_Byte5 4;
BA_ "UserSigValidity" SG_ 1836 RWPC_GST_Byte5 0;
BA_REL_ "GenSigTimeoutTime" BU_SG_REL_ CGW_CCU SG_ 1836 RWPC_GST_Byte5 0;
BA_ "NetworkRequest" SG_ 1836 RWPC_GST_Byte5 0;
BA_ "NetworkRequestHoldingTime" SG_ 1836 RWPC_GST_Byte5 5000;
BA_ "Version" SG_ 1836 RWPC_GST_Byte5 "21.02.04";
BA_ "Description" SG_ 1836 RWPC_GST_Byte6 "TP Index : 168";
BA_ "UsrSigPurpose" SG_ 1836 RWPC_GST_Byte6 4;
BA_ "UserSigValidity" SG_ 1836 RWPC_GST_Byte6 0;
BA_REL_ "GenSigTimeoutTime" BU_SG_REL_ CGW_CCU SG_ 1836 RWPC_GST_Byte6 0;
BA_ "NetworkRequest" SG_ 1836 RWPC_GST_Byte6 0;
BA_ "NetworkRequestHoldingTime" SG_ 1836 RWPC_GST_Byte6 5000;
BA_ "Version" SG_ 1836 RWPC_GST_Byte6 "21.02.04";
BA_ "Description" SG_ 1836 RWPC_GST_Byte7 "TP Index : 168";
BA_ "UsrSigPurpose" SG_ 1836 RWPC_GST_Byte7 4;
BA_ "UserSigValidity" SG_ 1836 RWPC_GST_Byte7 0;
BA_REL_ "GenSigTimeoutTime" BU_SG_REL_ CGW_CCU SG_ 1836 RWPC_GST_Byte7 0;
BA_ "NetworkRequest" SG_ 1836 RWPC_GST_Byte7 0;
BA_ "NetworkRequestHoldingTime" SG_ 1836 RWPC_GST_Byte7 5000;
BA_ "Version" SG_ 1836 RWPC_GST_Byte7 "21.02.04";
BA_ "Description" SG_ 1836 RWPC_GST_Byte1 "TP Index : 168";
BA_ "UsrSigPurpose" SG_ 1836 RWPC_GST_Byte1 4;
BA_ "UserSigValidity" SG_ 1836 RWPC_GST_Byte1 0;
BA_REL_ "GenSigTimeoutTime" BU_SG_REL_ CGW_CCU SG_ 1836 RWPC_GST_Byte1 0;
BA_ "NetworkRequest" SG_ 1836 RWPC_GST_Byte1 0;
BA_ "NetworkRequestHoldingTime" SG_ 1836 RWPC_GST_Byte1 5000;
BA_ "Version" SG_ 1836 RWPC_GST_Byte1 "21.02.04";
BA_ "GenMsgSendType" BO_ 799 0;
BA_ "Description" SG_ 799 SBCM_DRV_Crc1Val "The data area for CRC calculation is based on the data length (DLC) of the message DB.

The CRC shall be calculated over the entire data block (excluding the CRC bytes) including the user data, alive counter and Data ID 

 

- CRC Polynomial (0x1D) , Initial Value : 0x00, XOR value : 0xFF, Data ID Mode : Both, Data ID : Message ID + 0xF800 

- The initial value is for CRC calculation and the message should be sent with the calculated result value. 

The mathematical expression to 8 bit CRC polynomial is given here. G(x) = x8 + x4 + x3 + x2 + 1";
BA_ "GenSigSendType" SG_ 799 SBCM_DRV_Crc1Val 4;
BA_ "GenSigStartValue" SG_ 799 SBCM_DRV_Crc1Val 255;
BA_ "UserSigValidity" SG_ 799 SBCM_DRV_Crc1Val 0;
BA_ "Version" SG_ 799 SBCM_DRV_Crc1Val "19.07.06";
BA_ "Description" SG_ 799 DRV_CrashUnlockCmd "Drive Crash Unlock Command";
BA_ "GenSigSendType" SG_ 799 DRV_CrashUnlockCmd 4;
BA_ "UserSigValidity" SG_ 799 DRV_CrashUnlockCmd 0;
BA_REL_ "GenSigTimeoutTime" BU_SG_REL_ BLTN_CAM SG_ 799 DRV_CrashUnlockCmd 1500;
BA_ "NetworkRequest" SG_ 799 DRV_CrashUnlockCmd 0;
BA_ "Version" SG_ 799 DRV_CrashUnlockCmd "20.09.00";
BA_ "Description" SG_ 799 C_ApprOpenStatus "This is for Power Door System enable/disable signal.";
BA_ "GenSigSendType" SG_ 799 C_ApprOpenStatus 4;
BA_ "UserSigValidity" SG_ 799 C_ApprOpenStatus 0;
BA_ "Version" SG_ 799 C_ApprOpenStatus "20.09.00";
BA_ "Description" SG_ 799 SBCM_DRV_AlvCnt1Val "For the first transmission request for a data element the counter shall be initialized with 0 and shall be incremented by 1

for every subsequent send request. When the counter reaches the maximum value(0xE), then it shall restart with 0 for the next send request";
BA_ "GenSigSendType" SG_ 799 SBCM_DRV_AlvCnt1Val 4;
BA_ "UserSigValidity" SG_ 799 SBCM_DRV_AlvCnt1Val 0;
BA_ "Version" SG_ 799 SBCM_DRV_AlvCnt1Val "19.07.06";
BA_ "Description" SG_ 799 DoorLock_DrvKeyLkSwSta_SBCM "Door Lock Driver Mechanical Key Input Signal";
BA_ "GenSigSendType" SG_ 799 DoorLock_DrvKeyLkSwSta_SBCM 4;
BA_ "UserSigValidity" SG_ 799 DoorLock_DrvKeyLkSwSta_SBCM 0;
BA_ "NetworkRequest" SG_ 799 DoorLock_DrvKeyLkSwSta_SBCM 0;
BA_ "Version" SG_ 799 DoorLock_DrvKeyLkSwSta_SBCM "19.07.06";
BA_ "Description" SG_ 799 DoorLock_DrvKeyUnLkSwSta_SBCM "Door Drive Mechanical Key Unlock Switch State";
BA_ "GenSigSendType" SG_ 799 DoorLock_DrvKeyUnLkSwSta_SBCM 4;
BA_ "UserSigValidity" SG_ 799 DoorLock_DrvKeyUnLkSwSta_SBCM 0;
BA_ "NetworkRequest" SG_ 799 DoorLock_DrvKeyUnLkSwSta_SBCM 0;
BA_ "Version" SG_ 799 DoorLock_DrvKeyUnLkSwSta_SBCM "19.07.06";
BA_ "Description" SG_ 799 Warn_DrvDrSwSta_SBCM "Warning Drive Door Switch State";
BA_ "GenSigSendType" SG_ 799 Warn_DrvDrSwSta_SBCM 4;
BA_ "UserSigValidity" SG_ 799 Warn_DrvDrSwSta_SBCM 0;
BA_REL_ "GenSigTimeoutTime" BU_SG_REL_ WPC SG_ 799 Warn_DrvDrSwSta_SBCM 1500;
BA_REL_ "GenSigTimeoutTime" BU_SG_REL_ RWPC SG_ 799 Warn_DrvDrSwSta_SBCM 1500;
BA_REL_ "GenSigTimeoutTime" BU_SG_REL_ DPSU SG_ 799 Warn_DrvDrSwSta_SBCM 1500;
BA_REL_ "GenSigTimeoutTime" BU_SG_REL_ ATS SG_ 799 Warn_DrvDrSwSta_SBCM 1500;
BA_REL_ "GenSigTimeoutTime" BU_SG_REL_ BLTN_CAM SG_ 799 Warn_DrvDrSwSta_SBCM 1500;
BA_ "NetworkRequest" SG_ 799 Warn_DrvDrSwSta_SBCM 0;
BA_ "Version" SG_ 799 Warn_DrvDrSwSta_SBCM "21.07.07";
BA_ "Description" SG_ 799 DoorLock_DrvDrUnLkSta_SBCM "Drive Door Lock Unlock Status";
BA_ "GenSigSendType" SG_ 799 DoorLock_DrvDrUnLkSta_SBCM 4;
BA_ "UserSigValidity" SG_ 799 DoorLock_DrvDrUnLkSta_SBCM 0;
BA_REL_ "GenSigTimeoutTime" BU_SG_REL_ ATS SG_ 799 DoorLock_DrvDrUnLkSta_SBCM 1500;
BA_ "NetworkRequest" SG_ 799 DoorLock_DrvDrUnLkSta_SBCM 0;
BA_ "Version" SG_ 799 DoorLock_DrvDrUnLkSta_SBCM "19.07.06";
BA_ "Description" SG_ 799 DRV_SEAWarn_LH "Drive (FLH) Door SEA Warning";
BA_ "GenSigSendType" SG_ 799 DRV_SEAWarn_LH 4;
BA_ "UserSigValidity" SG_ 799 DRV_SEAWarn_LH 0;
BA_ "NetworkRequest" SG_ 799 DRV_SEAWarn_LH 0;
BA_ "Version" SG_ 799 DRV_SEAWarn_LH "19.12.00";
BA_ "Description" SG_ 799 DRV_SEAWarn_RH "Drive (FRH) Door SEA Warning";
BA_ "GenSigSendType" SG_ 799 DRV_SEAWarn_RH 4;
BA_ "UserSigValidity" SG_ 799 DRV_SEAWarn_RH 0;
BA_ "NetworkRequest" SG_ 799 DRV_SEAWarn_RH 0;
BA_ "Version" SG_ 799 DRV_SEAWarn_RH "19.12.07";
BA_ "Description" SG_ 799 DRV_SEWWarn_LH "Drive (FLH) Door Safety Exit Warning";
BA_ "GenSigSendType" SG_ 799 DRV_SEWWarn_LH 4;
BA_ "UserSigValidity" SG_ 799 DRV_SEWWarn_LH 0;
BA_ "NetworkRequest" SG_ 799 DRV_SEWWarn_LH 0;
BA_ "Version" SG_ 799 DRV_SEWWarn_LH "20.09.00";
BA_ "Description" SG_ 799 DRV_SEWWarn_RH "Drive (FRH) Door Safety Exit Warning";
BA_ "GenSigSendType" SG_ 799 DRV_SEWWarn_RH 4;
BA_ "UserSigValidity" SG_ 799 DRV_SEWWarn_RH 0;
BA_ "NetworkRequest" SG_ 799 DRV_SEWWarn_RH 0;
BA_ "Version" SG_ 799 DRV_SEWWarn_RH "20.09.00";
BA_ "GenSigSendType" SG_ 799 DRV_MRActivationAlarm 4;
BA_ "UserSigValidity" SG_ 799 DRV_MRActivationAlarm 0;
BA_ "NetworkRequest" SG_ 799 DRV_MRActivationAlarm 0;
BA_ "NetworkRequestHoldingTime" SG_ 799 DRV_MRActivationAlarm 5000;
BA_ "Version" SG_ 799 DRV_MRActivationAlarm "19.11.05";
BA_ "GenSigSendType" SG_ 799 DRV_ReleaseWarn 4;
BA_ "UserSigValidity" SG_ 799 DRV_ReleaseWarn 0;
BA_ "NetworkRequest" SG_ 799 DRV_ReleaseWarn 0;
BA_ "NetworkRequestHoldingTime" SG_ 799 DRV_ReleaseWarn 5000;
BA_ "Version" SG_ 799 DRV_ReleaseWarn "19.11.05";
BA_ "Description" SG_ 799 Latch_TypeOption_DRV "If the E-Lacth is applied, the signal will be send for identify the door lock/unlock function and option.";
BA_ "GenSigSendType" SG_ 799 Latch_TypeOption_DRV 4;
BA_ "UserSigValidity" SG_ 799 Latch_TypeOption_DRV 0;
BA_ "NetworkRequest" SG_ 799 Latch_TypeOption_DRV 0;
BA_ "Version" SG_ 799 Latch_TypeOption_DRV "20.09.00";
BA_ "GenSigSendType" SG_ 799 DRV_SWFailAlarm 4;
BA_ "UserSigValidity" SG_ 799 DRV_SWFailAlarm 0;
BA_ "NetworkRequest" SG_ 799 DRV_SWFailAlarm 0;
BA_ "NetworkRequestHoldingTime" SG_ 799 DRV_SWFailAlarm 5000;
BA_ "Version" SG_ 799 DRV_SWFailAlarm "19.11.05";
BA_ "GenSigSendType" SG_ 799 USM_PwrDRApprOpnSetSta 4;
BA_ "UserSigValidity" SG_ 799 USM_PwrDRApprOpnSetSta 0;
BA_ "NetworkRequest" SG_ 799 USM_PwrDRApprOpnSetSta 0;
BA_ "NetworkRequestHoldingTime" SG_ 799 USM_PwrDRApprOpnSetSta 5000;
BA_ "Version" SG_ 799 USM_PwrDRApprOpnSetSta "20.12.03";
BA_ "GenSigSendType" SG_ 799 USM_PwrDRApprOpnSetOpt 4;
BA_ "UserSigValidity" SG_ 799 USM_PwrDRApprOpnSetOpt 0;
BA_ "NetworkRequest" SG_ 799 USM_PwrDRApprOpnSetOpt 0;
BA_ "NetworkRequestHoldingTime" SG_ 799 USM_PwrDRApprOpnSetOpt 5000;
BA_ "Version" SG_ 799 USM_PwrDRApprOpnSetOpt "20.12.03";
BA_ "GenSigSendType" SG_ 799 USM_PwrDRCloseByRKELockSta 4;
BA_ "UserSigValidity" SG_ 799 USM_PwrDRCloseByRKELockSta 0;
BA_ "NetworkRequest" SG_ 799 USM_PwrDRCloseByRKELockSta 0;
BA_ "NetworkRequestHoldingTime" SG_ 799 USM_PwrDRCloseByRKELockSta 5000;
BA_ "Version" SG_ 799 USM_PwrDRCloseByRKELockSta "20.12.03";
BA_ "GenSigSendType" SG_ 799 USM_PwrDRCloseByRKELockOpt 4;
BA_ "UserSigValidity" SG_ 799 USM_PwrDRCloseByRKELockOpt 0;
BA_ "NetworkRequest" SG_ 799 USM_PwrDRCloseByRKELockOpt 0;
BA_ "NetworkRequestHoldingTime" SG_ 799 USM_PwrDRCloseByRKELockOpt 5000;
BA_ "Version" SG_ 799 USM_PwrDRCloseByRKELockOpt "20.12.03";
BA_ "GenSigSendType" SG_ 799 USM_PwrDRCloseByBrakeSta 4;
BA_ "UserSigValidity" SG_ 799 USM_PwrDRCloseByBrakeSta 0;
BA_ "NetworkRequest" SG_ 799 USM_PwrDRCloseByBrakeSta 0;
BA_ "NetworkRequestHoldingTime" SG_ 799 USM_PwrDRCloseByBrakeSta 5000;
BA_ "Version" SG_ 799 USM_PwrDRCloseByBrakeSta "20.12.03";
BA_ "GenSigSendType" SG_ 799 USM_PwrDRCloseByBrakeOpt 4;
BA_ "UserSigValidity" SG_ 799 USM_PwrDRCloseByBrakeOpt 0;
BA_ "NetworkRequest" SG_ 799 USM_PwrDRCloseByBrakeOpt 0;
BA_ "NetworkRequestHoldingTime" SG_ 799 USM_PwrDRCloseByBrakeOpt 5000;
BA_ "Version" SG_ 799 USM_PwrDRCloseByBrakeOpt "20.12.03";
BA_ "GenSigSendType" SG_ 799 USM_PwrDRBuzzerSta 4;
BA_ "UserSigValidity" SG_ 799 USM_PwrDRBuzzerSta 0;
BA_ "NetworkRequest" SG_ 799 USM_PwrDRBuzzerSta 0;
BA_ "NetworkRequestHoldingTime" SG_ 799 USM_PwrDRBuzzerSta 5000;
BA_ "Version" SG_ 799 USM_PwrDRBuzzerSta "20.12.03";
BA_ "GenSigSendType" SG_ 799 USM_PwrDRBuzzerOpt 4;
BA_ "UserSigValidity" SG_ 799 USM_PwrDRBuzzerOpt 0;
BA_ "NetworkRequest" SG_ 799 USM_PwrDRBuzzerOpt 0;
BA_ "NetworkRequestHoldingTime" SG_ 799 USM_PwrDRBuzzerOpt 5000;
BA_ "Version" SG_ 799 USM_PwrDRBuzzerOpt "20.12.03";
BA_ "GenSigSendType" SG_ 799 PDS_TypeOption_DRV 4;
BA_ "UserSigValidity" SG_ 799 PDS_TypeOption_DRV 0;
BA_ "NetworkRequest" SG_ 799 PDS_TypeOption_DRV 0;
BA_ "Version" SG_ 799 PDS_TypeOption_DRV "20.09.00";
BA_ "Description" SG_ 799 C_DrvDoorApproachOpen "Fob searching start and stop signal for PDS.";
BA_ "GenSigSendType" SG_ 799 C_DrvDoorApproachOpen 4;
BA_ "UserSigValidity" SG_ 799 C_DrvDoorApproachOpen 0;
BA_ "Version" SG_ 799 C_DrvDoorApproachOpen "20.09.00";
BA_ "Description" SG_ 799 C_DrvDoorApproachClose "To close the door automatically, request the fob searching signal";
BA_ "GenSigSendType" SG_ 799 C_DrvDoorApproachClose 4;
BA_ "UserSigValidity" SG_ 799 C_DrvDoorApproachClose 0;
BA_ "Version" SG_ 799 C_DrvDoorApproachClose "20.09.00";
BA_ "GenSigSendType" SG_ 799 DoorLock_PDSLkSwSta_DRV 4;
BA_ "UserSigValidity" SG_ 799 DoorLock_PDSLkSwSta_DRV 0;
BA_ "NetworkRequest" SG_ 799 DoorLock_PDSLkSwSta_DRV 0;
BA_ "Version" SG_ 799 DoorLock_PDSLkSwSta_DRV "20.09.00";
BA_ "GenSigSendType" SG_ 799 DRVDoorPushAlarm 4;
BA_ "UserSigValidity" SG_ 799 DRVDoorPushAlarm 0;
BA_ "NetworkRequest" SG_ 799 DRVDoorPushAlarm 0;
BA_ "NetworkRequestHoldingTime" SG_ 799 DRVDoorPushAlarm 5000;
BA_ "Version" SG_ 799 DRVDoorPushAlarm "20.09.00";
BA_ "GenMsgCycleTime" BO_ 1837 0;
BA_ "GenMsgCycleTimeFast" BO_ 1837 0;
BA_ "GenMsgNrOfRepetition" BO_ 1837 0;
BA_ "DiagResponse" BO_ 1837 1;
BA_ "GenMsgILSupport" BO_ 1837 0;
BA_ "TpMessage" BO_ 1837 1;
BA_ "TpTxIndex" BO_ 1837 180;
BA_ "Description" SG_ 1837 WPC_GST_Byte0 "TP Index : 180";
BA_ "UsrSigPurpose" SG_ 1837 WPC_GST_Byte0 4;
BA_ "UserSigValidity" SG_ 1837 WPC_GST_Byte0 0;
BA_REL_ "GenSigTimeoutTime" BU_SG_REL_ CGW_CCU SG_ 1837 WPC_GST_Byte0 0;
BA_ "NetworkRequest" SG_ 1837 WPC_GST_Byte0 0;
BA_ "NetworkRequestHoldingTime" SG_ 1837 WPC_GST_Byte0 5000;
BA_ "Version" SG_ 1837 WPC_GST_Byte0 "21.02.04";
BA_ "Description" SG_ 1837 WPC_GST_Byte2 "TP Index : 180";
BA_ "UsrSigPurpose" SG_ 1837 WPC_GST_Byte2 4;
BA_ "UserSigValidity" SG_ 1837 WPC_GST_Byte2 0;
BA_REL_ "GenSigTimeoutTime" BU_SG_REL_ CGW_CCU SG_ 1837 WPC_GST_Byte2 0;
BA_ "NetworkRequest" SG_ 1837 WPC_GST_Byte2 0;
BA_ "NetworkRequestHoldingTime" SG_ 1837 WPC_GST_Byte2 5000;
BA_ "Version" SG_ 1837 WPC_GST_Byte2 "21.02.04";
BA_ "Description" SG_ 1837 WPC_GST_Byte3 "TP Index : 180";
BA_ "UsrSigPurpose" SG_ 1837 WPC_GST_Byte3 4;
BA_ "UserSigValidity" SG_ 1837 WPC_GST_Byte3 0;
BA_REL_ "GenSigTimeoutTime" BU_SG_REL_ CGW_CCU SG_ 1837 WPC_GST_Byte3 0;
BA_ "NetworkRequest" SG_ 1837 WPC_GST_Byte3 0;
BA_ "NetworkRequestHoldingTime" SG_ 1837 WPC_GST_Byte3 5000;
BA_ "Version" SG_ 1837 WPC_GST_Byte3 "21.02.04";
BA_ "Description" SG_ 1837 WPC_GST_Byte4 "TP Index : 180";
BA_ "UsrSigPurpose" SG_ 1837 WPC_GST_Byte4 4;
BA_ "UserSigValidity" SG_ 1837 WPC_GST_Byte4 0;
BA_REL_ "GenSigTimeoutTime" BU_SG_REL_ CGW_CCU SG_ 1837 WPC_GST_Byte4 0;
BA_ "NetworkRequest" SG_ 1837 WPC_GST_Byte4 0;
BA_ "NetworkRequestHoldingTime" SG_ 1837 WPC_GST_Byte4 5000;
BA_ "Version" SG_ 1837 WPC_GST_Byte4 "21.02.04";
BA_ "Description" SG_ 1837 WPC_GST_Byte5 "TP Index : 180";
BA_ "UsrSigPurpose" SG_ 1837 WPC_GST_Byte5 4;
BA_ "UserSigValidity" SG_ 1837 WPC_GST_Byte5 0;
BA_REL_ "GenSigTimeoutTime" BU_SG_REL_ CGW_CCU SG_ 1837 WPC_GST_Byte5 0;
BA_ "NetworkRequest" SG_ 1837 WPC_GST_Byte5 0;
BA_ "NetworkRequestHoldingTime" SG_ 1837 WPC_GST_Byte5 5000;
BA_ "Version" SG_ 1837 WPC_GST_Byte5 "21.02.04";
BA_ "Description" SG_ 1837 WPC_GST_Byte6 "TP Index : 180";
BA_ "UsrSigPurpose" SG_ 1837 WPC_GST_Byte6 4;
BA_ "UserSigValidity" SG_ 1837 WPC_GST_Byte6 0;
BA_REL_ "GenSigTimeoutTime" BU_SG_REL_ CGW_CCU SG_ 1837 WPC_GST_Byte6 0;
BA_ "NetworkRequest" SG_ 1837 WPC_GST_Byte6 0;
BA_ "NetworkRequestHoldingTime" SG_ 1837 WPC_GST_Byte6 5000;
BA_ "Version" SG_ 1837 WPC_GST_Byte6 "21.02.04";
BA_ "Description" SG_ 1837 WPC_GST_Byte7 "TP Index : 180";
BA_ "UsrSigPurpose" SG_ 1837 WPC_GST_Byte7 4;
BA_ "UserSigValidity" SG_ 1837 WPC_GST_Byte7 0;
BA_REL_ "GenSigTimeoutTime" BU_SG_REL_ CGW_CCU SG_ 1837 WPC_GST_Byte7 0;
BA_ "NetworkRequest" SG_ 1837 WPC_GST_Byte7 0;
BA_ "NetworkRequestHoldingTime" SG_ 1837 WPC_GST_Byte7 5000;
BA_ "Version" SG_ 1837 WPC_GST_Byte7 "21.02.04";
BA_ "Description" SG_ 1837 WPC_GST_Byte1 "TP Index : 180";
BA_ "UsrSigPurpose" SG_ 1837 WPC_GST_Byte1 4;
BA_ "UserSigValidity" SG_ 1837 WPC_GST_Byte1 0;
BA_REL_ "GenSigTimeoutTime" BU_SG_REL_ CGW_CCU SG_ 1837 WPC_GST_Byte1 0;
BA_ "NetworkRequest" SG_ 1837 WPC_GST_Byte1 0;
BA_ "NetworkRequestHoldingTime" SG_ 1837 WPC_GST_Byte1 5000;
BA_ "Version" SG_ 1837 WPC_GST_Byte1 "21.02.04";
VAL_ 2239848449 FCA_OnOffEquipSta 0 "Default" 1 "Off" 2 "Warning" 3 "Assist" 4 "Reserved" 5 "Reserved" 6 "Reserved" 7 "Invalid" ;
VAL_ 2239848449 FCA_SysFlrSta 0 "Normal" 1 "Temp. Unavailable by Front View Camera (Sensor fusion)" 2 "Temp. Unavailable by Front Radar (Radar only or Sensor fusion in Radar)" 3 "Service Required" 4 "Temp. Unavailable by Front View Camera (Camera only)" 5 "Temp. Unavailable by Front View Camera (Sensor fusion in ADAS_DRV)" 6 "Temp. Unavailable by Front Radar (Sensor fusion in Camera)" 7 "Reserved" ;
VAL_ 2239848449 FCA_WrngLvlSta 0 "No warning" 1 "Warning level 1" 2 "Warning level 2" 3 "Warning level 3" ;
VAL_ 2239848449 FCA_VehStpReq 0 "No request" 1 "Stop control is required" 2 "Reserved" 3 "Error Indicator" ;
VAL_ 2239848449 FCA_StbltActvReq 0 "Release No alert" 1 "Pre-crash full retraction" 2 "Haptic warning" 3 "Reserved" 4 "Reserved" 5 "Reserved" 6 "Reserved" 7 "Reserved" ;
VAL_ 2239848449 FCA_HydrlcBstAsstReq 0 "Standard threshold" 1 "Lowered threshold 1" 2 "Lowered threshold 2" 3 "Lowered threshold 3" ;
VAL_ 2239848449 FCA_PrefillActvReq 0 "No pre-fill" 1 "Pre-fill act" 2 "Reserved" 3 "Error Indicator" ;
VAL_ 2239848449 FCA_PartialActvReq 0 "No Partial act" 1 "Partail act" 2 "Reserved" 3 "Error Indicator" ;
VAL_ 2239848449 FCA_FullActvReq 0 "No Full act" 1 "Full act" 2 "Reserved" 3 "Error Indicator" ;
VAL_ 2239848449 FCA_Regulation 0 "No warning" 1 "FCA Amber warning on" 2 "FCA Red warning blinking" 3 "Reserved" ;
VAL_ 2239848449 FCA_SnstvtyModRetVal 0 "Default" 1 "Late" 2 "Normal" 3 "Early" 4 "Reserved" 5 "Reserved" 6 "Reserved" 7 "Invalid" ;
VAL_ 2239848449 FCA_WrngSndSta 0 "No warning" 1 "Warning 1" 2 "Warning 2" 3 "Warning 3" 4 "Reserved" 5 "Reserved" 6 "Reserved" 7 "Error indicator" ;
VAL_ 2239848450 FCA_RelVel 511 "Signal Invalid" ;
VAL_ 2239848450 Nmode_FCAOff_Sta 0 "Not Applied" 1 "Disable" 2 "Enable" 3 "Invalid" ;
VAL_ 2239848450 FCA_Jnctn_OnOffEquipSta 0 "Default" 1 "Off" 2 "On" 3 "Invalid" ;
VAL_ 2239848450 HDP_EMOpSta 0 "Off" 1 "On (Not Active)" 2 "On (Active)" 3 "Reserved" 4 "Reserved" 5 "Reserved" 6 "Reserved" 7 "Error indicator" ;
VAL_ 2239848450 FCA_WrngTrgtDis 0 "None" 1 "FCA-Pedestrian" 2 "Reserved" 3 "FCA-Cyclist" 4 "Reserved" 5 "FCA-Car" 6 "Reserved" 7 "FCA-JC (L)" 8 "FCA-JC (R)" 9 "Reserved" 10 "Reserved" 11 "FCA-JT (L)" 12 "FCA-JT (R)" 13 "Reserved" 14 "Reserved" ;
VAL_ 2239848450 ADAS_DRV_FCA_Plus_Sta 0 "FCA-Car/Ped/Cyc+ »óÈ² ¹ÌÇØ´ç" 1 "FCA-Car/Ped/Cyc+ »óÈ² ÇØ´ç" 2 "Not Used" 3 "Error Indicator" ;
VAL_ 2239848450 ADAS_TrlOffStaDisp 0 "Normal" 1 "Auto Off by Trailer connected" 2 "Reserved" 3 "Reserved" ;
VAL_ 2239848450 FCA_FrOnOffEquipSta 0 "Default" 1 "Off" 2 "On" 3 "Invalid" ;
VAL_ 2239848450 FCA_JC_OnOffEquipSta 0 "Default" 1 "Off" 2 "On" 3 "Invalid" ;
VAL_ 2239848450 FCA_FrSdOnOffEquipSta 0 "Default" 1 "Off" 2 "On" 3 "Invalid" ;
VAL_ 2239848450 EM_WrngLvlSta 0 "No warning" 1 "Prefill (Warning level1)" 2 "Partial brake (Warning level2)" 3 "Full brake (Warning level3)" 4 "Reserved" 5 "Reserved" 6 "Reserved" 7 "Error indicator" ;
VAL_ 2239848450 BrkDelVLimReq 0 "Delta V limit required (Release brake control over ¥ÄV 50km/h)" 1 "Delta V limit not required w/ additional signal (Not release brake control)" 2 "Delta V limit not required w/o additional signal (Not release brake control)" 3 "Reserved" 4 "Reserved" 5 "Reserved" 6 "Reserved" 7 "Error indicator" ;
VAL_ 2239848450 ADAS_InhbtOffDispSta 0 "Default" 1 "Inhibit off in regulation (Cluster)" 2 "Inhibit off in regulation (H/UNIT)" 3 "Inhibit off in HDP (Cluster)" 4 "Reserved" 5 "Reserved" 6 "Reserved" 7 "Invalid" ;
VAL_ 2239848450 FCA_WarnTimeSta 0 "Default" 1 "Late" 2 "Normal" 3 "Reserved" 4 "Reserved" 5 "Reserved" 6 "Reserved" 7 "Invalid" ;
VAL_ 2256644609 CLU_DtntOutSta 0 "Detent Off" 1 "Detent On" 2 "Not used" 3 "Error Indicator" ;
VAL_ 2256644609 CLU_SpdUnitTyp 0 "km/h" 1 "MPH" 2 "Not used" 3 "Error Indicator" ;
VAL_ 2256644609 CLU_DisSpdDcmlVal 0 "0" 1 "0.125" 2 "0.250" 3 "0.375" ;
VAL_ 2256644609 CLU_SWRCCrsMainSwSta 0 "Off" 1 "Key On" 2 "Reserved" 3 "Invalid" ;
VAL_ 2256644609 CLU_SWRCCrsSwSta 0 "Idle Position" 1 "Plus" 2 "Minus" 3 "Headway" 4 "Cancel/Pause" 5 "Reserved" 6 "Reserved" 7 "Reserved" ;
VAL_ 2256644609 CLU_SWRCLFASwSta 0 "Off" 1 "Key On" 2 "Reserved" 3 "Invalid" ;
VAL_ 2256644609 CLU_SWRCSldMainSwSta 0 "Off" 1 "Key On" 2 "Reserved" 3 "Invalid" ;
VAL_ 2256644609 CLU_RhstaLvlSta 0 "Reserved" 1 "Step 1" 2 "Step 2" 3 "Step 3" 4 "Step 4" 5 "Step 5" 6 "Step 6" 7 "Step 7" 8 "Step 8" 9 "Step 9" 10 "Step 10" 11 "Step 11" 12 "Step 12" 13 "Step 13" 14 "Step 14" 15 "Step 15" 16 "Step 16" 17 "Step 17" 18 "Step 18" 19 "Step 19" 20 "Step 20 (Reset Value)" 21 "Step 21 (Detent)" ;
VAL_ 2256644609 CLU_DisSpdVal 1023 "Error" ;
VAL_ 2256644609 CLU_OKSwSta 0 "Off" 1 "Key On" 2 "Reserved" 3 "Invalid" ;
VAL_ 2256644610 CLU_DisSpdVal_KPH 511 "Error" ;
VAL_ 2256644610 CLU_CUSTOMSta_NEW 0 "Default" 1 "MY DRIVE MODE(CUSTOM)" 2 "SMART(CUSTOM)" 3 "BABY(CUSTOM)" 4 "RETRO(CUSTOM)" 5 "SNOW(CUSTOM)-Not Terrain" 6 "COMFORT(REAR)(CUSTOM)" 7 "" 8 "" 9 "" 10 "" 11 "" 12 "" 13 "" 14 "Off(CUSTOM)" 15 "Invalid" ;
VAL_ 2256644610 CLU_AutoBrightSta 0 "Reserved (Not Used)" 1 "0x01~0xC8:Bright State (1~200 Step)" 200 "0x01~0xC8:Bright State (1~200 Step)" ;
VAL_ 2256644610 CLU_PwrAutoOffResetReq_HCU 0 "Default" 1 "Reset Request" 2 "Reserved" 3 "Invalid" ;
VAL_ 2470761217 USM_AutoDrLkSetReq 0 "Default" 1 "Off" 2 "Vehicle Speed On (15Km)" 3 "Shift Lever On" 4 "Invalid" ;
VAL_ 2470761217 USM_AutoDrUnlckSetReq 0 "Default" 1 "Off" 2 "Key Out On (AllDoors)" 3 "Shift Lever On (AllDoors)" 4 "Override" 5 "Invalid" 6 "Key Out On (Driver Door)" 7 "Shift Lever On (Driver Door)" ;
VAL_ 2470761217 USM_HLmpEscrtSetReq 0 "Default Value" 1 "Escort Off" 2 "Escort On" 3 "Invalid" ;
VAL_ 2470761217 USM_SmrtTrnkSetReq 0 "Default" 1 "HandsFree Off" 2 "HandsFree On" 3 "Reserved" 4 "Invalid" ;
VAL_ 2470761217 USM_MdLmpSetReq 0 "Default Value" 1 "Mood Lamp Off" 2 "Mood Lamp On" 3 "Modd Lamp Auto" 4 "Invalid" 5 "Reserved" 6 "Reserved" 7 "Reserved" ;
VAL_ 2470761217 USM_HrnAnswerBckSetReq 0 "Default" 1 "Arm Disarm Buzzer Off" 2 "Arm Disarm Buzzer On" 3 "Invalid" ;
VAL_ 2470761217 USM_OneTouchTrplTrnSetReq 0 "Default" 1 "One Touch Turn Off" 2 "3 Flashing" 3 "5 Flashing" 4 "7 Flashing" 5 "Invalid" 6 "Reserved" 7 "Reserved" ;
VAL_ 2470761217 USM_PsmSetReq 0 "Default" 1 "Off (Disable)" 2 "50mmOn (Enable)" 3 "75mmOn (Enable)" 4 "Reserved" 5 "Reserved" 6 "Reserved" 7 "Invalid" ;
VAL_ 2470761217 USM_PtgmSetReq 0 "Default" 1 "Power Mode" 2 "Manual Mode" 3 "Invalid" ;
VAL_ 2470761217 USM_ScmSetReq 0 "Default" 1 "Steering Off" 2 "Steering On" 3 "Invalid" ;
VAL_ 2470761217 USM_OSTempUnitSetReq 0 "Default" 1 "Centigrade(¡É)" 2 "Fahrenheit(¢µ)" 3 "Invalid" ;
VAL_ 2470761217 USM_TfrChgSetReq 0 "Default" 1 "Disable" 2 "Enable" 3 "Reserved" ;
VAL_ 2470761217 USM_WALModSetreq 0 "Default" 1 "Disable" 2 "Enable" 3 "Invalid" ;
VAL_ 2470761217 USM_EscOffSetReq 0 "Default" 1 "Off Mode" 2 "Normal Mode" 3 "Sport mode" 4 "Reserved" 5 "Reserved" 6 "Reserved" 7 "Invalid" ;
VAL_ 2470761217 USM_PsmHgtSetReq 0 "Default(USM ¹Ì±¸¼º)" 1 "Off(Disable)" 2 "On(Enable)" 3 "Reserved" 4 "Reserved" 5 "Reserved" 6 "Reserved" 7 "Invalid" ;
VAL_ 2445572097 CLU_ICUDlvrModOffSetReq 0 "Default" 1 "OFF Request" 2 "Reserved" 3 "Invalid" ;
VAL_ 2445572097 CLU_SMKKeyOutWarnOffReq 0 "Default" 1 "OFF Request" 2 "Reserved" 3 "Invalid" ;
VAL_ 2445572097 CLU_SbwNModReq 0 "Off" 1 "N mode request" ;
VAL_ 2445572097 CLU_RrStRemindOffSetReq 0 "Default" 1 "Off Request" 2 "Off Request 2 (Warn in Rest)" 3 "Invalid" ;
VAL_ 2445572097 CLU_RrStRemindFdbckSetReq 0 "Off(Default)" 1 "On(1st ROA Alert On)" 2 "On(Warn in Rest On)" 3 "Invalid" ;
VAL_ 2445572097 CLU_PwrAutoOffResetReq 0 "Default" 1 "Reset Request" 2 "Reserved" 3 "Invalid" ;
VAL_ 2445572097 CLU_HDALCFuncOnSetReq 0 "Default" 1 "On Request" 2 "Reserved" 3 "Invalid" ;
VAL_ 2445572097 CLU_WelcomeStartReq 0 "Default" 1 "Welcome Start" 2 "Goodbye_Start(ADM_Off)" 3 "Invalid" ;
VAL_ 2445572097 CLU_HDAOnSetReq 0 "Default" 1 "On" 2 "Reserved" 3 "Invalid" ;
VAL_ 2445572097 CF_Clu_HCSSOSStopReq 0 "Default" 1 "SOS Call Stop Req" 2 "Reserved" 3 "Invalid" ;
VAL_ 2445572097 CLU_UpdateIGNIhn 0 "off(default)" 1 "Cranking" 2 "Cranking inhibit" 3 "IGN, Cranking inhibit" 4 "reserved" 5 "reserved" 6 "reserved" 7 "error inicator" ;
VAL_ 2445572097 CLU_TpmsSetReq 0 "Default" 1 "Start Settings" 2 "Confirm Settings" 3 "Cancel" 4 "Reserved" 5 "Reserved" 6 "Reserved" 7 "Invalid" ;
VAL_ 2395189249 DATC_SmrtVntOnOffSta 0 "Fuction Off" 1 "Function On" 2 "Not Used" 3 "Error Indicator" ;
VAL_ 2395189249 DATC_PsAutoDis 0 "AUTO Off" 1 "AUTO On" 2 "Not used" 3 "Error Indicator" ;
VAL_ 2395189249 DATC_RrOffDis 0 "Front and Rear OFF" 1 "Normal Display" 2 "Rear 'OFF' Display" 3 "Error Indicator" ;
VAL_ 2395189249 DATC_RrAutoDis 0 "AUTO Off" 1 "AUTO On" 2 "Not used" 3 "Error Indicator" ;
VAL_ 2395189249 DATC_RrDrvModDis 0 "Off(Blank Display, ÅäÃâ¸ðµå ¹ÌÇ¥½Ã ¿¹) Auto ½Ã)" 1 "VENT" 2 "B_L" 3 "FLOOR" 4 "MIX (7 MODE DEF FLOOR)" 5 "DEF (MAX DEF)" 6 "AUTO DEFOG" 7 "7 MODE DEF VENT" 8 "MODE AUTO" 9 "7 MODE DEF VENT FLOOR" 10 "7 MODE DEF" 11 "DEF VENT (Arrow)" 12 "DEF FLOOR (Arrow)" 13 "DEF VENT FLOOR (Arrow)" 14 "DEF (Arrow)" 15 "Error Indicator" ;
VAL_ 2395189249 DATC_RrPassModDis 0 "Off(Blank Display, ÅäÃâ¸ðµå ¹ÌÇ¥½Ã ¿¹) Auto ½Ã)" 1 "VENT" 2 "B_L" 3 "FLOOR" 4 "MIX (7 MODE DEF FLOOR)" 5 "DEF(MAX DEF)" 6 "AUTO DEFOG" 7 "7 MODE DEF VENT" 8 "MODE AUTO" 9 "7 MODE DEF VENT FLOOR" 10 "7 MODE DEF" 11 "DEF VENT (Arrow)" 12 "DEF FLOOR (Arrow)" 13 "DEF VENT FLOOR (Arrow)" 14 "DEF (Arrow)" 15 "Error Indicator" ;
VAL_ 2395189249 DATC_AutoArClnSysSta 0 "Auto Air Cleaning System Off" 1 "Auto Air Cleaning System On" 2 "Reserved" 3 "Invalid" ;
VAL_ 2395189249 DATC_DisplayThemes 0 "Default" 1 "White Theme" 2 "Black Theme" 3 "Invalid" ;
VAL_ 2395189249 DATC_AUTOStepPS 0 "Default" 1 "OFF" 2 "1st & 2nd & 3rd On (3 Step Type)" 3 "1st & 2nd On (3 Step Type)" 4 "1st On (3 Step Type)" 5 "1st & 2nd On (2 Step Type)" 6 "1st On (2 Step Type)" 7 "Error Indicator" ;
VAL_ 2395189249 DATC_AUTOStepRR 0 "Default" 1 "OFF" 2 "1st & 2nd & 3rd On (3 Step Type)" 3 "1st & 2nd On (3 Step Type)" 4 "1st On (3 Step Type)" 5 "1st & 2nd On (2 Step Type)" 6 "1st On (2 Step Type)" 7 "Error Indicator" ;
VAL_ 2395189249 DATC_AutoArClnUSMState 0 "Default" 1 "Auto AirCleaning USM OFF" 2 "Auto AirCleaning USM ON" 3 "Invalid" ;
VAL_ 2378398721 DATC_FragStrhUSMSta 0 "Default" 1 "Off" 2 "Low" 3 "Medium" 4 "High" 5 "Reserved" 6 "Reserved" 7 "Error Indicator" ;
VAL_ 2378398721 DATC_FragKindUSMSta 0 "Default" 1 "First" 2 "Second" 3 "Reserved" 4 "Reserved" 5 "Reserved" 6 "None" 7 "Error Indicator" ;
VAL_ 2378398721 DATC_Frag1ExpireDisp 0 "Default" 1 "Normal" 2 "Expired" 3 "Error Indicator" ;
VAL_ 2378398721 DATC_FragStrhDis 0 "Default" 1 "Off" 2 "Low" 3 "Medium" 4 "High" 5 "Reserved" 6 "Reserved" 7 "Error Indicator" ;
VAL_ 2378398721 DATC_FragKindDis 0 "Default" 1 "First" 2 "Second" 3 "Reserved" 4 "Reserved" 5 "Reserved" 6 "None" 7 "Error Indicator" ;
VAL_ 2378398721 DATC_Frag2ExpireDisp 0 "Default" 1 "Normal" 2 "Expired" 3 "Error Indicator" ;
VAL_ 2378398721 DATC_VitalityFragranceSta 0 "Default" 1 "Off" 2 "On" 3 "Error Indicator" ;
VAL_ 2378398721 DATC_DelightFragranceSta 0 "Default" 1 "Off" 2 "On" 3 "Error Indicator" ;
VAL_ 2378398721 DATC_CareFragranceSta 0 "Default" 1 "Off" 2 "On" 3 "Error Indicator" ;
VAL_ 2378398721 DATC_ComfortFragranceSta 0 "Default" 1 "Off" 2 "On" 3 "Error Indicator" ;
VAL_ 2378398721 DATC_Frag1Inform 0 "Default" 1 "THE DRIVER'S AWAKENING" 2 "MY FAVORITE PLACE" 3 "THE GREAT OUTDOORS" 4 "Reserved" 5 "Reserved" 6 "Reserved" 7 "Reserved" 8 "Reserved" 9 "Reserved" 10 "Reserved" 11 "Reserved" 12 "New Fragrance Mounted" 13 "No Cartridge Mounted" 14 "Unknown Cartridge Monuted" 15 "Error Indicator" ;
VAL_ 2378398721 DATC_Frag1RemainDisp 0 "Default" 1 "Remains 100% (70~100%)" 2 "Remains 70% (30~70%)" 3 "Remains 30% (0~30%)" 4 "Remains 0%" 5 "Reserved" 6 "Unknown" 7 "Error Indicator" ;
VAL_ 2378398721 DATC_Frag2Inform 0 "Default" 1 "THE DRIVER'S AWAKENING" 2 "MY FAVORITE PLACE" 3 "THE GREAT OUTDOORS" 4 "Reserved" 5 "Reserved" 6 "Reserved" 7 "Reserved" 8 "Reserved" 9 "Reserved" 10 "Reserved" 11 "Reserved" 12 "New Fragrance Mounted" 13 "No Cartridge Mounted" 14 "Unknown Cartridge Mounted" 15 "Error Indicator" ;
VAL_ 2378398721 DATC_Frag2RemainDisp 0 "Default" 1 "Remains 100% (70~100%)" 2 "Remains 70% (30~70%)" 3 "Remains 30% (0~30%)" 4 "Remains 0%" 5 "Reserved" 6 "Unknown" 7 "Error Indicator" ;
VAL_ 346 DPSS_WalkInSwitchSts 0 "Default" 1 "Off" 2 "On" 3 "Invalid" ;
VAL_ 345 DSAU_LumbarUpDis 0 "Default" 1 "Off" 2 "On" 3 "Invalid" ;
VAL_ 345 DSAU_LumbarMidDis 0 "Default" 1 "Off" 2 "On" 3 "Invalid" ;
VAL_ 345 DSAU_LumbarLowDis 0 "Default" 1 "Off" 2 "On" 3 "Invalid" ;
VAL_ 345 DSAU_LumbarDefDis 0 "Default" 1 "Off" 2 "On" 3 "Invalid" ;
VAL_ 348 DSAU_BolsterInfDis 0 "Default" 1 "Off" 2 "On" 3 "Invalid" ;
VAL_ 348 DSAU_BolsterDefDis 0 "Default" 1 "Off" 2 "On" 3 "Invalid" ;
VAL_ 349 DSAU_CushInfDis 0 "Default" 1 "Off" 2 "On" 3 "Invalid" ;
VAL_ 349 DSAU_CushDefDis 0 "Default" 1 "Off" 2 "On" 3 "Invalid" ;
VAL_ 350 DSAU_AirSptTimeRValueSet 0 "Default" 1 "Short" 2 "Normal" 3 "Long" 4 "Reserved" 5 "Reserved" 6 "Reserved" 7 "Reserved" ;
VAL_ 350 DSAU_DrvPostureAssistRValueSet 0 "Default" 1 "Off" 2 "On" 3 "Invalid" ;
VAL_ 350 DSAU_DrvSmtAirSptRValueSet 0 "Default" 1 "Off" 2 "On" 3 "Invalid" ;
VAL_ 350 DSAU_DrvSmtSptRValueSet 0 "Default" 1 "Off" 2 "On" 3 "Invalid" ;
VAL_ 350 DSAU_CushSoftRValueSet 0 "Default" 1 "Off" 2 "Soft" 3 "Mid" 4 "Hard" 5 "Reserved" 6 "Reserved" 7 "Reserved" ;
VAL_ 350 DSAU_BackSoftRValueSet 0 "Default" 1 "Off" 2 "Soft" 3 "Mid" 4 "Hard" 5 "Reserved" 6 "Reserved" 7 "Reserved" ;
VAL_ 350 DSAU_AirSptModeRValueSet 0 "Default" 1 "Mode 1" 2 "Mode 2" 3 "Mode 3" 4 "Mode 4" 5 "Mode 5" 6 "Reserved" 7 "Reserved" ;
VAL_ 350 DSAU_MsgModeSts 0 "Default" 1 "Off" 2 "Mode 1" 3 "Mode 2" 4 "Mode 3" 5 "Mode 4" 6 "Mode 5" 7 "Reserved" ;
VAL_ 350 DSAU_MsgModeStrength 0 "Default" 1 "Off" 2 "Low" 3 "Mid" 4 "High" 5 "Reserved" 6 "Reserved" 7 "Reserved" ;
VAL_ 350 DSAU_MoodTrpyRValueSet 0 "Default" 1 "Off" 2 "On" 3 "Invalid" ;
VAL_ 350 DSAU_MoodTrpyCareSta 0 "Default" 1 "Off" 2 "On" 3 "Invalid" ;
VAL_ 350 DSAU_MoodTrpyComfSta 0 "Default" 1 "Off" 2 "On" 3 "Invalid" ;
VAL_ 350 DASU_AirSptStrRValueSet 0 "Default" 1 "Low" 2 "Mid" 3 "High" 4 "Off" 5 "Reserved" 6 "Reserved" 7 "Reserved" ;
VAL_ 2277634049 EPB_LmpStaDis 0 "Release State (EPB AVH)" 1 "Apply State (EPB)" 2 "Dynamic Braking (EPB) or Driver Action Requested" ;
VAL_ 2277634049 EPB_FlrLmpStaDis 0 "No failure" 1 "Failure detected or in diagnosis mode" 2 "EOL configuration not done or Emergency released" 3 "Reserved" 4 "Reserved" 5 "Reserved" 6 "Reserved" 7 "Reserved" 8 "Reserved" 9 "Reserved" 10 "Reserved" 11 "Reserved" 12 "Reserved" 13 "Reserved" 14 "Not used" 15 "Error Indicator" ;
VAL_ 2277634049 EPB_OutDataDis 0 "Off" 1 "EPB is in maintenance mode" 2 "Driver tries to DAR but safety condition is not satisfied" 3 "EPB applies by ESC request" 4 "Driver tries to DAR but safety condition is not satisfied for China" 5 "Driver tries to release EPB by operating the switch without pressing the brake pedal" 6 "Driver tries to park in the N(Neutral) position" ;
VAL_ 2277634049 EPB_AlrmReq 0 "Off" 1 "Comfortable tone (Sound once)" 2 "Uncomfortable tone" 3 "Error Indicator" ;
VAL_ 2277634049 EPB_SwPosSta 0 "Neutral position" 1 "Apply position (pull)" 2 "Release position (push)" 3 "Switch failure" ;
VAL_ 2277634049 EPB_RrBrkLtActvReq 0 "No request" 1 "Request to turn on rear brake lights" 2 "Not used" 3 "Error Indicator" ;
VAL_ 2277634049 EPB_FrcErrSta 0 "No failure" 1 "Clamp position not reached" 2 "Emergency release" 3 "Force not measurable (e.g. sensor failure)" ;
VAL_ 2277634049 EPB_DynmBrkFrcReqSigSta 0 "EPB_DynmBrkFrcReqSigSta signal is invalid" 1 "EPB_DynmBrkFrcReqSigSta signal is valid" 2 "Not used" 3 "Error Indicator" ;
VAL_ 2277634049 EPB_FrcSta 0 "See details in EPB_FRC_ERR" 1 "Released" 2 "Clamped" 3 "Clamping in progress" 4 "Releasing in progress" 5 "Dynamic braking via EPB" 6 "Releasing in progress by switch" 7 "Clamping in progress by switch" ;
VAL_ 2277634049 EPB_FlSta 0 "Not valid" 1 "EPB No failure" 2 "EPB Initialization State" 3 "EPB Diagnostic" 4 "EPB Temporarily Not Available" 5 "EPB Permanently Not Available" ;
VAL_ 2277634049 EPB_EscReqAckSta 0 "Idle / No acknowledge" 1 "Acknowledge for external ESC request" 2 "Not used" 3 "Error Indicator" ;
VAL_ 2277634049 EPB_DynmBrkFrcReq 0 "No Request" 1 "Dynamic braking request" 2 "Not used" 3 "Error Indicator" ;
VAL_ 2277634049 EPB_EmerModReq 0 "No Request" 1 "Emergency EPB Mode Request" 2 "Normal EPB Mode Request" 3 "Not Used" ;
VAL_ 2277634049 EPB_EpbSta4VcuReq 0 "Undefined (Initialization or Unknown State)" 1 "Clamped by VCU Parking Command" 2 "Moving for EPB applying or releasing" 3 "Release State by VCU Not Parking Command" ;
VAL_ 2277634050 EPB_ActlFrcVal 0 "EPB Fully released" ;
VAL_ 2210462209 HCU_DucUsrSetCluSta 0 "None" 1 "User DUC Setting Page On" 2 "DUC Setting Cancel Page On" 3 "DUC Setting Confirm Page On" 4 "DUC Setting Inhibit" 5 "Reserved" 6 "Reserved" 7 "Reserved" ;
VAL_ 2210462209 HCU_EstApsSelSta 0 "EMS real APS use" 1 "HCU Estimated APS use" 2 "Not used" 3 "Error Indicator" ;
VAL_ 2210462209 HCU_GreenZoneDrvModSta 0 "Default" 1 "Off" 2 "On" 3 "reserved" ;
VAL_ 2210462210 HCU_GreenZoneLmpDis 0 "GDM Lamp Off" 1 "GDM Lamp On" ;
VAL_ 2210462210 HCU_MILOnReq 0 "Not request" 1 "MIL On Request" 2 "Not used" 3 "Error Indicator" ;
VAL_ 2210462210 HCU_PhevAutoModOnSta 0 "AUTO Mode Off" 1 "AUTO Mode On" ;
VAL_ 2210462210 HCU_SccDrvOvrdReq 0 "Override clear" 1 "Override set" 2 "Not used" 3 "Error Indicator" ;
VAL_ 2210462210 HCU_SccEnblSta 0 "SCC Impossible" 1 "SCC Possible" 2 "Not used" 3 "Error Indicator" ;
VAL_ 2210462210 HCU_SlwDnSta 0 "None" 1 "Slowdown state" 2 "Not used" 3 "Error Indicator" ;
VAL_ 2210462210 HCU_HcuRdySta 0 "HCU not Ready" 1 "HCU Control Board Ready" 2 "Not used" 3 "Error Indicator" ;
VAL_ 2210462210 HCU_SmrtEcoGdDis 0 "Off" 1 "On" 2 "Not used" 3 "Error Indicator" ;
VAL_ 2210462210 HCU_SmrtEcoLvlDis 0 "Not Display" 1 "1~100%" 2 "1~100%" 3 "1~100%" 4 "1~100%" 5 "1~100%" 6 "1~100%" 7 "1~100%" 8 "1~100%" 9 "1~100%" 10 "1~100%" 11 "1~100%" 12 "1~100%" 13 "1~100%" 14 "1~100%" 15 "1~100%" 16 "1~100%" 17 "1~100%" 18 "1~100%" 19 "1~100%" 20 "1~100%" 21 "1~100%" 22 "1~100%" 23 "1~100%" 24 "1~100%" 25 "1~100%" 26 "1~100%" 27 "1~100%" 28 "1~100%" 29 "1~100%" 30 "1~100%" 31 "1~100%" 32 "1~100%" 33 "1~100%" 34 "1~100%" 35 "1~100%" 36 "1~100%" 37 "1~100%" 38 "1~100%" 39 "1~100%" 40 "1~100%" 41 "1~100%" 42 "1~100%" 43 "1~100%" 44 "1~100%" 45 "1~100%" 46 "1~100%" 47 "1~100%" 48 "1~100%" 49 "1~100%" 50 "1~100%" 51 "1~100%" 52 "1~100%" 53 "1~100%" 54 "1~100%" 55 "1~100%" 56 "1~100%" 57 "1~100%" 58 "1~100%" 59 "1~100%" 60 "1~100%" 61 "1~100%" 62 "1~100%" 63 "1~100%" 64 "1~100%" 65 "1~100%" 66 "1~100%" 67 "1~100%" 68 "1~100%" 69 "1~100%" 70 "1~100%" 71 "1~100%" 72 "1~100%" 73 "1~100%" 74 "1~100%" 75 "1~100%" 76 "1~100%" 77 "1~100%" 78 "1~100%" 79 "1~100%" 80 "1~100%" 81 "1~100%" 82 "1~100%" 83 "1~100%" 84 "1~100%" 85 "1~100%" 86 "1~100%" 87 "1~100%" 88 "1~100%" 89 "1~100%" 90 "1~100%" 91 "1~100%" 92 "1~100%" 93 "1~100%" 94 "1~100%" 95 "1~100%" 96 "1~100%" 97 "1~100%" 98 "1~100%" 99 "1~100%" 100 "1~100%" 101 "Reserved" 102 "Reserved" 103 "Reserved" 104 "Reserved" 105 "Reserved" 106 "Reserved" 107 "Reserved" 108 "Reserved" 109 "Reserved" 110 "Reserved" 111 "Reserved" 112 "Reserved" 113 "Reserved" 114 "Reserved" 115 "Reserved" 116 "Reserved" 117 "Reserved" 118 "Reserved" 119 "Reserved" 120 "Reserved" 121 "Reserved" 122 "Reserved" 123 "Reserved" 124 "Reserved" 125 "Reserved" 126 "Reserved" 127 "Reserved" ;
VAL_ 2210462210 HCU_SmrtEcoRngDis 0 "Not Display" 1 "1~100%" 2 "1~100%" 3 "1~100%" 4 "1~100%" 5 "1~100%" 6 "1~100%" 7 "1~100%" 8 "1~100%" 9 "1~100%" 10 "1~100%" 11 "1~100%" 12 "1~100%" 13 "1~100%" 14 "1~100%" 15 "1~100%" 16 "1~100%" 17 "1~100%" 18 "1~100%" 19 "1~100%" 20 "1~100%" 21 "1~100%" 22 "1~100%" 23 "1~100%" 24 "1~100%" 25 "1~100%" 26 "1~100%" 27 "1~100%" 28 "1~100%" 29 "1~100%" 30 "1~100%" 31 "1~100%" 32 "1~100%" 33 "1~100%" 34 "1~100%" 35 "1~100%" 36 "1~100%" 37 "1~100%" 38 "1~100%" 39 "1~100%" 40 "1~100%" 41 "1~100%" 42 "1~100%" 43 "1~100%" 44 "1~100%" 45 "1~100%" 46 "1~100%" 47 "1~100%" 48 "1~100%" 49 "1~100%" 50 "1~100%" 51 "1~100%" 52 "1~100%" 53 "1~100%" 54 "1~100%" 55 "1~100%" 56 "1~100%" 57 "1~100%" 58 "1~100%" 59 "1~100%" 60 "1~100%" 61 "1~100%" 62 "1~100%" 63 "1~100%" 64 "1~100%" 65 "1~100%" 66 "1~100%" 67 "1~100%" 68 "1~100%" 69 "1~100%" 70 "1~100%" 71 "1~100%" 72 "1~100%" 73 "1~100%" 74 "1~100%" 75 "1~100%" 76 "1~100%" 77 "1~100%" 78 "1~100%" 79 "1~100%" 80 "1~100%" 81 "1~100%" 82 "1~100%" 83 "1~100%" 84 "1~100%" 85 "1~100%" 86 "1~100%" 87 "1~100%" 88 "1~100%" 89 "1~100%" 90 "1~100%" 91 "1~100%" 92 "1~100%" 93 "1~100%" 94 "1~100%" 95 "1~100%" 96 "1~100%" 97 "1~100%" 98 "1~100%" 99 "1~100%" 100 "1~100%" 101 "Reserved" 102 "Reserved" 103 "Reserved" 104 "Reserved" 105 "Reserved" 106 "Reserved" 107 "Reserved" 108 "Reserved" 109 "Reserved" 110 "Reserved" 111 "Reserved" 112 "Reserved" 113 "Reserved" 114 "Reserved" 115 "Reserved" 116 "Reserved" 117 "Reserved" 118 "Reserved" 119 "Reserved" 120 "Reserved" 121 "Reserved" 122 "Reserved" 123 "Reserved" 124 "Reserved" 125 "Reserved" 126 "Reserved" 127 "Reserved" ;
VAL_ 2210462210 HCU_SpdLimDeviceActSta 0 "Speed Limiter Lamp Off (Deactivation)" 1 "Speed Limiter Lamp On (Activation)" 2 "Not used" 3 "Error Indicator" ;
VAL_ 2210462210 HCU_SpdLimDeviceOperSta 0 "Speed Limiter Not Operation" 1 "Speed Limiter Operation" 2 "Speed Limiter Standby" 3 "Error Inicator" ;
VAL_ 2210462210 HCU_HEVRdyDis 0 "READY LAMP OFF" 1 "READY LAMP ON" 2 "Not used" 3 "READY LAMP BLINKING" ;
VAL_ 2210462210 HCU_SrvModSta 0 "Normal made" 1 "2WD Test mode" 2 "Not used" 3 "Error Indicator" ;
VAL_ 2210462210 HCU_StrtInhbt2Sta 0 "None" 1 "Start Inhibit" 2 "Not used" 3 "Error Indicator" ;
VAL_ 2210462210 HCU_StrtInhbtSta 0 "None" 1 "Start Inhibit state" 2 "Not used" 3 "Error Indicator" ;
VAL_ 2210462210 HCU_SysShtOffReq 0 "Not request" 1 "Request" 2 "Not used" 3 "Error Indicator" ;
VAL_ 2210462210 HCU_VehStrtEnblSta 0 "Start disable" 1 "Start Enable" 2 "Not used" 3 "Error Indicator" ;
VAL_ 2210462210 HCU_BrkLmpOnReq 0 "None" 1 "Lamp On Request" 2 "Not Used" 3 "Error Indicator" ;
VAL_ 2210462210 HCU_HevRdySta 0 "HEV not ready" 1 "HEV Drivable" 2 "Not used" 3 "Error Indicator" ;
VAL_ 2210462210 HCU_CcDrvAlrtDis 0 "default" 1 "CC Disengaged" 2 "No CC Engage Condition" 3 "reserved" ;
VAL_ 2210462210 HCU_SldDrvAlrtDis 0 "default" 1 "SLDdisengeged" 2 "NoSLDEngageCondition" 3 "Reserve" ;
VAL_ 2210462210 HCU_LimpOffSta 0 "None" 1 "Limp off the road" 2 "Not used" 3 "Error Indicator" ;
VAL_ 2210462211 HCU_RspaAlvCntVal 0 "counter" 1 "counter" 2 "counter" 3 "counter" ;
VAL_ 2210462211 HCU_RspaSta 0 "Invalid" 1 "Init" 2 "New Start" 3 "Ready OK" 4 "" 5 "Assist OK" 6 "Assist Fail" 7 "Abort" 8 "Ready Fail" ;
VAL_ 2210462211 HCU_RspaCanFailSta 0 "HCU received RSPA CAN message successfully" 1 "HCU failed to receive RSPA CAN message succesfully" 2 "Reserved" 3 "Reserved" ;
VAL_ 2210462211 HCU_PdlStopCtrlSta 0 "Not Request" 1 "Request" 2 "Not Used" 3 "Not Used" ;
VAL_ 2210462211 HCU_GearRInhbtSta 0 "Not Request" 1 "Request for Drive Inhibit Gear R" 2 "Reserve" 3 "Reserve" ;
VAL_ 883 HU_GNSS_TimeSource 0 "none" 1 "RTC" 2 "GPS(<10ms)" 3 "GPS(<1ms)" ;
VAL_ 883 HU_GNSS_search 0 "none" 1 "blind" 2 "anywhere" ;
VAL_ 883 HU_GNSS_DST 0 "DST OFF" 1 "DST ON" 2 "reserved" 3 "Invalid" ;
VAL_ 883 HU_GNSS_Fix_status 0 "Doing position fixes" 2 "need time" 3 "PDOP too high" 5 "No usable SVs" 6 "one usable SV" 7 "two usable SVs" 8 "three usable SVs" ;
VAL_ 799 DRV_CrashUnlockCmd 0 "Off" 1 "Unlock(Crash)" ;
VAL_ 799 C_ApprOpenStatus 0 "Approach Open Off" 1 "Approach Open On" ;
VAL_ 799 DoorLock_DrvKeyLkSwSta_SBCM 0 "Off" 1 "Lock" 2 "Not Used" 3 "Error Indicator" ;
VAL_ 799 DoorLock_DrvKeyUnLkSwSta_SBCM 0 "Off" 1 "Unlock" 2 "Not Used" 3 "Error Indicator" ;
VAL_ 799 Warn_DrvDrSwSta_SBCM 0 "Close" 1 "Open" 2 "RESERVED" 3 "Error Indicator" ;
VAL_ 799 DoorLock_DrvDrUnLkSta_SBCM 0 "Lock" 1 "Unlock" 2 "Not Used" 3 "Error Indicator" ;
VAL_ 799 DRV_SEAWarn_LH 0 "SEA Left Warning OFF" 1 "SEA Left Warning ON" 2 "Reserved" 3 "Invalid" ;
VAL_ 799 DRV_SEAWarn_RH 0 "SEA Right Warning OFF" 1 "SEA Right  Warning ON" 2 "Reserved" 3 "Invalid" ;
VAL_ 799 DRV_SEWWarn_LH 0 "SEW Left Warning OFF" 1 "SEW Left Warning ON" 2 "Reserved" 3 "Invalid" ;
VAL_ 799 DRV_SEWWarn_RH 0 "SEW Right Warning OFF" 1 "SEW Right Warning ON" 2 "Reserved" 3 "Invalid" ;
VAL_ 799 DRV_MRActivationAlarm 0 "Off" 1 "On" 2 "Not Used" 3 "Error Indicator" ;
VAL_ 799 DRV_ReleaseWarn 0 "Release Warning OFF" 1 "Release Warning ON" 2 "Reserved" 3 "Invalid" ;
VAL_ 799 Latch_TypeOption_DRV 0 "Off" 1 "On" 2 "Not Used" 3 "Error Indicator" ;
VAL_ 799 DRV_SWFailAlarm 0 "Off" 1 "On" 2 "Not Used" 3 "Error Indicator" ;
VAL_ 799 USM_PwrDRApprOpnSetSta 0 "Default" 1 "Off" 2 "On" 3 "Invalid" ;
VAL_ 799 USM_PwrDRApprOpnSetOpt 0 "Default" 1 "Off" 2 "On" 3 "Invalid" ;
VAL_ 799 USM_PwrDRCloseByRKELockSta 0 "Default" 1 "Off" 2 "On" 3 "Invalid" ;
VAL_ 799 USM_PwrDRCloseByRKELockOpt 0 "Default" 1 "Off" 2 "On" 3 "Invalid" ;
VAL_ 799 USM_PwrDRCloseByBrakeSta 0 "Default" 1 "Off" 2 "On" 3 "Invalid" ;
VAL_ 799 USM_PwrDRCloseByBrakeOpt 0 "Default" 1 "Off" 2 "On" 3 "Invalid" ;
VAL_ 799 USM_PwrDRBuzzerSta 0 "Default" 1 "Off" 2 "On" 3 "Invalid" ;
VAL_ 799 USM_PwrDRBuzzerOpt 0 "Default" 1 "Off" 2 "On" 3 "Invalid" ;
VAL_ 799 PDS_TypeOption_DRV 0 "Off" 1 "On" 2 "Not Used" 3 "Error Indicator" ;
VAL_ 799 C_DrvDoorApproachOpen 0 "Default" 1 "Approach Open Request" 2 "Approach Open Stop" 3 "Not Used" ;
VAL_ 799 C_DrvDoorApproachClose 0 "Default" 1 "Approach Close Request" 2 "Approach Close Stop" 3 "Not Used" ;
VAL_ 799 DoorLock_PDSLkSwSta_DRV 0 "Default" 1 "Lock" 2 "Not Used" 3 "Error Indicator" ;
VAL_ 799 DRVDoorPushAlarm 0 "Off" 1 "On" 2 "Not Used" 3 "Error Indicator" ;
